VERSION ""

NS_ :

BS_:

BU_: WCM VPM VLM VKM UVM TIM TEST_TOOL_2 TEST_TOOL_1 TCP TCM TCCM3 TCCM STC SRR_SRR SRR_SLR SRR_RR SRR_RF SRR_LR_CR SRR_LF SIB SDM SCL SBZA_R SBZA_L SBM SADS RadioLow RSC RDCM PTM PDR PA NVM MTCM_R MTCM_L MSM_RR MSM_P MSM_LR MSM_D MSB2 MSB1 MRCM_R MRCM_L MFC LRR_HC LRR LIB1 IPC ICS_Info ICCM HVAC_FP_R HVAC_FP_F HUD_CAN HDLM FCM_LC FCM EPS EOCM_HCP2 EOCM_HCP1 EOCM ELM ECP_X1 ECP_MC ECP_E ECM EBCM DMS DEFC DCM CSM CMMb CMMa CGM BSM_MH BSM BCM ARS ARB APA AOS AMP ALC AHS AHL_AFL AGC

BO_ 1425 CGM_CAN5_PDU108: 6 CGM
 SG_ PTOSet2SpdCstAvlFlg4 : 0|1@0+ (1,0) [0|1] "" CSM,RadioLow
 SG_ PTOSet2SpdCstAvlFlg3 : 1|1@0+ (1,0) [0|1] "" CSM,RadioLow
 SG_ PTOSet2SpdCstAvlFlg2 : 2|1@0+ (1,0) [0|1] "" CSM,RadioLow
 SG_ PTOSet2SpdCstAvlFlg15 : 3|1@0+ (1,0) [0|1] "" CSM,RadioLow
 SG_ PTOSet2SpdCstAvlFlg14 : 4|1@0+ (1,0) [0|1] "" CSM,RadioLow
 SG_ PTOSet2SpdCstAvlFlg13 : 5|1@0+ (1,0) [0|1] "" CSM,RadioLow
 SG_ PTOSet2SpdCstAvlFlg12 : 6|1@0+ (1,0) [0|1] "" CSM,RadioLow
 SG_ PTOSet2SpdCstAvlFlg11 : 7|1@0+ (1,0) [0|1] "" CSM,RadioLow
 SG_ PTOStndbySpdCstAvlFlg3 : 8|1@0+ (1,0) [0|1] "" CSM,RadioLow
 SG_ PTOStndbySpdCstAvlFlg2 : 9|1@0+ (1,0) [0|1] "" CSM,RadioLow
 SG_ PTOStndbySpdCstAvlFlg1 : 10|1@0+ (1,0) [0|1] "" CSM,RadioLow
 SG_ PTOSet2SpdCstAvlFlg9 : 11|1@0+ (1,0) [0|1] "" CSM,RadioLow
 SG_ PTOSet2SpdCstAvlFlg8 : 12|1@0+ (1,0) [0|1] "" CSM,RadioLow
 SG_ PTOSet2SpdCstAvlFlg7 : 13|1@0+ (1,0) [0|1] "" CSM,RadioLow
 SG_ PTOSet2SpdCstAvlFlg6 : 14|1@0+ (1,0) [0|1] "" CSM,RadioLow
 SG_ PTOSet2SpdCstAvlFlg5 : 15|1@0+ (1,0) [0|1] "" CSM,RadioLow
 SG_ PTOTpStpSpdCstAvlFlg4 : 16|1@0+ (1,0) [0|1] "" CSM,RadioLow
 SG_ PTOTpStpSpdCstAvlFlg3 : 17|1@0+ (1,0) [0|1] "" CSM,RadioLow
 SG_ PTOTpStpSpdCstAvlFlg2 : 18|1@0+ (1,0) [0|1] "" CSM,RadioLow
 SG_ PTOTpStpSpdCstAvlFlg1 : 19|1@0+ (1,0) [0|1] "" CSM,RadioLow
 SG_ PTOStndbySpdCstAvlFlg7 : 20|1@0+ (1,0) [0|1] "" CSM,RadioLow
 SG_ PTOStndbySpdCstAvlFlg6 : 21|1@0+ (1,0) [0|1] "" CSM,RadioLow
 SG_ PTOStndbySpdCstAvlFlg5 : 22|1@0+ (1,0) [0|1] "" CSM,RadioLow
 SG_ PTOStndbySpdCstAvlFlg4 : 23|1@0+ (1,0) [0|1] "" CSM,RadioLow
 SG_ UpftrSnwPlwIndReq : 25|2@0+ (1,0) [0|3] "" IPC
 SG_ UpftrRrAprchPrtctnIndReq : 28|3@0+ (1,0) [0|4] "" IPC
 SG_ PTOTpStpSpdCstAvlFlg7 : 29|1@0+ (1,0) [0|1] "" CSM,RadioLow
 SG_ PTOTpStpSpdCstAvlFlg6 : 30|1@0+ (1,0) [0|1] "" CSM,RadioLow
 SG_ PTOTpStpSpdCstAvlFlg5 : 31|1@0+ (1,0) [0|1] "" CSM,RadioLow
 SG_ IBS12VEstdBatTemp : 34|8@0+ (1,-40) [-40|215] "Degree C" CSM
 SG_ IBS12VEstdBatTemp_Inv : 35|1@0+ (1,0) [0|1] "" CSM
 SG_ UpftrRadioMutReqd : 36|1@0+ (1,0) [0|1] "" RadioLow
 SG_ UpftrBkupCamActvnReqd : 37|1@0+ (1,0) [0|1] "" RadioLow
 SG_ UpftrVehStrtEnblIndReq : 41|2@0+ (1,0) [0|3] "" IPC
 SG_ TransOilFiltChgIndOn : 42|1@0+ (1,0) [0|1] "" IPC

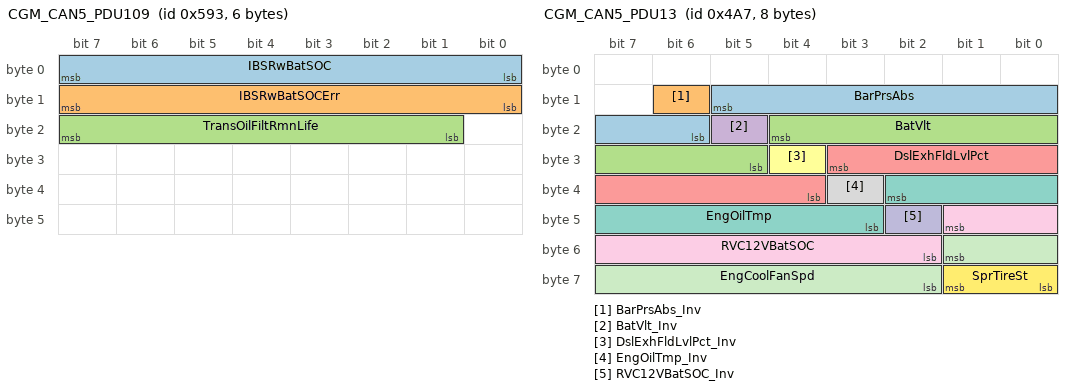
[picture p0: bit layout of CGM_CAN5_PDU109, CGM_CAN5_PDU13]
BO_ 1427 CGM_CAN5_PDU109: 6 CGM
 SG_ IBSRwBatSOC : 7|8@0+ (0.39,0) [0|99.45] "%" CSM
 SG_ IBSRwBatSOCErr : 15|8@0+ (0.39,0) [0|99.45] "%" CSM
 SG_ TransOilFiltRmnLife : 23|7@0+ (1,0) [0|127] "%" IPC

BO_ 1188 CGM_CAN5_PDU10: 8 CGM
 SG_ StBltTghtngCstAvlFlg7 : 0|1@0+ (1,0) [0|1] "" CSM,RadioLow
 SG_ StBltTghtngCstAvlFlg6 : 1|1@0+ (1,0) [0|1] "" CSM,RadioLow
 SG_ StBltTghtngCstAvlFlg5 : 2|1@0+ (1,0) [0|1] "" CSM,RadioLow
 SG_ StBltTghtngCstAvlFlg4 : 3|1@0+ (1,0) [0|1] "" CSM,RadioLow
 SG_ StBltTghtngCstAvlFlg3 : 4|1@0+ (1,0) [0|1] "" CSM,RadioLow
 SG_ StBltTghtngCstAvlFlg2 : 5|1@0+ (1,0) [0|1] "" CSM,RadioLow
 SG_ StBltTghtngCstAvlFlg1 : 6|1@0+ (1,0) [0|1] "" CSM,RadioLow
 SG_ RrCrsTrfcAlrtCstAvlFlg7 : 7|1@0+ (1,0) [0|1] "" CSM,RadioLow
 SG_ TrnsOlTmpSnsPrs : 8|1@0+ (1,0) [0|1] "" CSM,TCP
 SG_ TrffcLgtAsstCstAvlFlg7 : 9|1@0+ (1,0) [0|1] "" CSM,RadioLow
 SG_ TrffcLgtAsstCstAvlFlg6 : 10|1@0+ (1,0) [0|1] "" CSM,RadioLow
 SG_ TrffcLgtAsstCstAvlFlg5 : 11|1@0+ (1,0) [0|1] "" CSM,RadioLow
 SG_ TrffcLgtAsstCstAvlFlg4 : 12|1@0+ (1,0) [0|1] "" CSM,RadioLow
 SG_ TrffcLgtAsstCstAvlFlg3 : 13|1@0+ (1,0) [0|1] "" CSM,RadioLow
 SG_ TrffcLgtAsstCstAvlFlg2 : 14|1@0+ (1,0) [0|1] "" CSM,RadioLow
 SG_ TrffcLgtAsstCstAvlFlg1 : 15|1@0+ (1,0) [0|1] "" CSM,RadioLow
 SG_ DEFWVSL_S1SpdLmt : 23|8@0+ (1,0) [0|255] "km / h" IPC
 SG_ DEFWVSL_S2SpdLmt : 31|8@0+ (1,0) [0|255] "km / h" IPC
 SG_ DEFWVSL_S3SpdLmt : 39|8@0+ (1,0) [0|255] "km / h" IPC
 SG_ CustNonUsblSOC : 46|16@0+ (0.00152588,0) [0|99.9985] "%" IPC
 SG_ CustNonUsblSOC_DuD : 47|1@0+ (1,0) [0|1] "" IPC
 SG_ ClmCtlCbnAirCondCustLdEstd : 62|7@0+ (1,0) [0|127] "%" IPC

BO_ 1189 CGM_CAN5_PDU11: 8 CGM
 SG_ GoNotfrCstAvlFlg7 : 0|1@0+ (1,0) [0|1] "" CSM,RadioLow
 SG_ GoNotfrCstAvlFlg6 : 1|1@0+ (1,0) [0|1] "" CSM,RadioLow
 SG_ GoNotfrCstAvlFlg5 : 2|1@0+ (1,0) [0|1] "" CSM,RadioLow
 SG_ GoNotfrCstAvlFlg4 : 3|1@0+ (1,0) [0|1] "" CSM,RadioLow
 SG_ GoNotfrCstAvlFlg3 : 4|1@0+ (1,0) [0|1] "" CSM,RadioLow
 SG_ GoNotfrCstAvlFlg2 : 5|1@0+ (1,0) [0|1] "" CSM,RadioLow
 SG_ GoNotfrCstAvlFlg1 : 6|1@0+ (1,0) [0|1] "" CSM,RadioLow
 SG_ GlrFrHgBmRspTypCstAvlFlg7 : 7|1@0+ (1,0) [0|1] "" CSM,RadioLow
 SG_ LtRtHnTrCstAvlFlg1 : 8|1@0+ (1,0) [0|1] "" CSM,RadioLow
 SG_ LnChgAlrtCstAvlFlg7 : 9|1@0+ (1,0) [0|1] "" CSM,RadioLow,TCP
 SG_ LnChgAlrtCstAvlFlg6 : 10|1@0+ (1,0) [0|1] "" CSM,RadioLow,TCP
 SG_ LnChgAlrtCstAvlFlg5 : 11|1@0+ (1,0) [0|1] "" CSM,RadioLow,TCP
 SG_ LnChgAlrtCstAvlFlg4 : 12|1@0+ (1,0) [0|1] "" CSM,RadioLow,TCP
 SG_ LnChgAlrtCstAvlFlg3 : 13|1@0+ (1,0) [0|1] "" CSM,RadioLow,TCP
 SG_ LnChgAlrtCstAvlFlg2 : 14|1@0+ (1,0) [0|1] "" CSM,RadioLow,TCP
 SG_ LnChgAlrtCstAvlFlg1 : 15|1@0+ (1,0) [0|1] "" CSM,RadioLow,TCP
 SG_ PrkAsstONOFFCstAvlFlg1 : 16|1@0+ (1,0) [0|1] "" CSM,RadioLow
 SG_ PTHiElecLdReqd : 17|1@0+ (1,0) [0|1] "" CSM
 SG_ LtRtHnTrCstAvlFlg7 : 18|1@0+ (1,0) [0|1] "" CSM,RadioLow
 SG_ LtRtHnTrCstAvlFlg6 : 19|1@0+ (1,0) [0|1] "" CSM,RadioLow
 SG_ LtRtHnTrCstAvlFlg5 : 20|1@0+ (1,0) [0|1] "" CSM,RadioLow
 SG_ LtRtHnTrCstAvlFlg4 : 21|1@0+ (1,0) [0|1] "" CSM,RadioLow
 SG_ LtRtHnTrCstAvlFlg3 : 22|1@0+ (1,0) [0|1] "" CSM,RadioLow
 SG_ LtRtHnTrCstAvlFlg2 : 23|1@0+ (1,0) [0|1] "" CSM,RadioLow
 SG_ PrkAsstTrHtchPsntCstAvlFlg2 : 24|1@0+ (1,0) [0|1] "" CSM,RadioLow
 SG_ PrkAsstTrHtchPsntCstAvlFlg1 : 25|1@0+ (1,0) [0|1] "" CSM,RadioLow
 SG_ PrkAsstONOFFCstAvlFlg7 : 26|1@0+ (1,0) [0|1] "" CSM,RadioLow
 SG_ PrkAsstONOFFCstAvlFlg6 : 27|1@0+ (1,0) [0|1] "" CSM,RadioLow
 SG_ PrkAsstONOFFCstAvlFlg5 : 28|1@0+ (1,0) [0|1] "" CSM,RadioLow
 SG_ PrkAsstONOFFCstAvlFlg4 : 29|1@0+ (1,0) [0|1] "" CSM,RadioLow
 SG_ PrkAsstONOFFCstAvlFlg3 : 30|1@0+ (1,0) [0|1] "" CSM,RadioLow
 SG_ PrkAsstONOFFCstAvlFlg2 : 31|1@0+ (1,0) [0|1] "" CSM,RadioLow
 SG_ PFASndSeltnCstAvlFlg2 : 32|1@0+ (1,0) [0|1] "" CSM
 SG_ PFASndSeltnCstAvlFlg1 : 33|1@0+ (1,0) [0|1] "" CSM
 SG_ LgslDiagStdCndMet : 34|1@0+ (1,0) [0|1] "" TCP
 SG_ PrkAsstTrHtchPsntCstAvlFlg7 : 35|1@0+ (1,0) [0|1] "" CSM,RadioLow
 SG_ PrkAsstTrHtchPsntCstAvlFlg6 : 36|1@0+ (1,0) [0|1] "" CSM,RadioLow
 SG_ PrkAsstTrHtchPsntCstAvlFlg5 : 37|1@0+ (1,0) [0|1] "" CSM,RadioLow
 SG_ PrkAsstTrHtchPsntCstAvlFlg4 : 38|1@0+ (1,0) [0|1] "" CSM,RadioLow
 SG_ PrkAsstTrHtchPsntCstAvlFlg3 : 39|1@0+ (1,0) [0|1] "" CSM,RadioLow
 SG_ RnngBrdAutoDplyCstAvlFlg4 : 40|1@0+ (1,0) [0|1] "" CSM,RadioLow
 SG_ RnngBrdAutoDplyCstAvlFlg3 : 41|1@0+ (1,0) [0|1] "" CSM,RadioLow
 SG_ RnngBrdAutoDplyCstAvlFlg2 : 42|1@0+ (1,0) [0|1] "" CSM,RadioLow
 SG_ RnngBrdAutoDplyCstAvlFlg1 : 43|1@0+ (1,0) [0|1] "" CSM,RadioLow
 SG_ PFASndSeltnCstAvlFlg6 : 44|1@0+ (1,0) [0|1] "" CSM
 SG_ PFASndSeltnCstAvlFlg5 : 45|1@0+ (1,0) [0|1] "" CSM
 SG_ PFASndSeltnCstAvlFlg4 : 46|1@0+ (1,0) [0|1] "" CSM
 SG_ PFASndSeltnCstAvlFlg3 : 47|1@0+ (1,0) [0|1] "" CSM
 SG_ RnngBrdManDplyCstAvlFlg5 : 48|1@0+ (1,0) [0|1] "" CSM,RadioLow
 SG_ RnngBrdManDplyCstAvlFlg4 : 49|1@0+ (1,0) [0|1] "" CSM,RadioLow
 SG_ RnngBrdManDplyCstAvlFlg3 : 50|1@0+ (1,0) [0|1] "" CSM,RadioLow
 SG_ RnngBrdManDplyCstAvlFlg2 : 51|1@0+ (1,0) [0|1] "" CSM,RadioLow
 SG_ RnngBrdManDplyCstAvlFlg1 : 52|1@0+ (1,0) [0|1] "" CSM,RadioLow
 SG_ RnngBrdAutoDplyCstAvlFlg7 : 53|1@0+ (1,0) [0|1] "" CSM,RadioLow
 SG_ RnngBrdAutoDplyCstAvlFlg6 : 54|1@0+ (1,0) [0|1] "" CSM,RadioLow
 SG_ RnngBrdAutoDplyCstAvlFlg5 : 55|1@0+ (1,0) [0|1] "" CSM,RadioLow
 SG_ RrCrsTrfcAlrtCstAvlFlg6 : 56|1@0+ (1,0) [0|1] "" CSM,RadioLow
 SG_ RrCrsTrfcAlrtCstAvlFlg5 : 57|1@0+ (1,0) [0|1] "" CSM,RadioLow
 SG_ RrCrsTrfcAlrtCstAvlFlg4 : 58|1@0+ (1,0) [0|1] "" CSM,RadioLow
 SG_ RrCrsTrfcAlrtCstAvlFlg3 : 59|1@0+ (1,0) [0|1] "" CSM,RadioLow
 SG_ RrCrsTrfcAlrtCstAvlFlg2 : 60|1@0+ (1,0) [0|1] "" CSM,RadioLow
 SG_ RrCrsTrfcAlrtCstAvlFlg1 : 61|1@0+ (1,0) [0|1] "" CSM,RadioLow
 SG_ RnngBrdManDplyCstAvlFlg7 : 62|1@0+ (1,0) [0|1] "" CSM,RadioLow
 SG_ RnngBrdManDplyCstAvlFlg6 : 63|1@0+ (1,0) [0|1] "" CSM,RadioLow

BO_ 1190 CGM_CAN5_PDU12: 8 CGM
 SG_ TrnsOilRmnLf : 15|8@0+ (0.392157,0) [0|100] "%" CSM,IPC,TCP,VKM
 SG_ AutMemRclCstAvlFlg4 : 24|1@0+ (1,0) [0|1] "" CSM,RadioLow
 SG_ AutMemRclCstAvlFlg3 : 25|1@0+ (1,0) [0|1] "" CSM,RadioLow
 SG_ AutMemRclCstAvlFlg2 : 26|1@0+ (1,0) [0|1] "" CSM,RadioLow
 SG_ AutMemRclCstAvlFlg1 : 27|1@0+ (1,0) [0|1] "" CSM,RadioLow
 SG_ AdpLghtRspTypCstAvlFlg7 : 28|1@0+ (1,0) [0|1] "" CSM,RadioLow
 SG_ AdpLghtRspTypCstAvlFlg6 : 29|1@0+ (1,0) [0|1] "" CSM,RadioLow
 SG_ AdpLghtRspTypCstAvlFlg5 : 30|1@0+ (1,0) [0|1] "" CSM,RadioLow
 SG_ AdpLghtRspTypCstAvlFlg4 : 31|1@0+ (1,0) [0|1] "" CSM,RadioLow
 SG_ EsyExtCstAvlFlg4 : 32|1@0+ (1,0) [0|1] "" CSM,RadioLow
 SG_ EsyExtCstAvlFlg3 : 33|1@0+ (1,0) [0|1] "" CSM,RadioLow
 SG_ EsyExtCstAvlFlg2 : 34|1@0+ (1,0) [0|1] "" CSM,RadioLow
 SG_ EsyExtCstAvlFlg1 : 35|1@0+ (1,0) [0|1] "" CSM,RadioLow
 SG_ EngIdlAtv : 36|1@0+ (1,0) [0|1] "" CSM,IPC
 SG_ AutMemRclCstAvlFlg7 : 37|1@0+ (1,0) [0|1] "" CSM,RadioLow
 SG_ AutMemRclCstAvlFlg6 : 38|1@0+ (1,0) [0|1] "" CSM,RadioLow
 SG_ AutMemRclCstAvlFlg5 : 39|1@0+ (1,0) [0|1] "" CSM,RadioLow
 SG_ FrntPCMRspTypCstAvlFlg4 : 40|1@0+ (1,0) [0|1] "" CSM,RadioLow
 SG_ FrntPCMRspTypCstAvlFlg3 : 41|1@0+ (1,0) [0|1] "" CSM,RadioLow
 SG_ FrntPCMRspTypCstAvlFlg2 : 42|1@0+ (1,0) [0|1] "" CSM,RadioLow
 SG_ FrntPCMRspTypCstAvlFlg1 : 43|1@0+ (1,0) [0|1] "" CSM,RadioLow
 SG_ FlToPsSwAtv : 44|1@0+ (1,0) [0|1] "" CSM
 SG_ EsyExtCstAvlFlg7 : 45|1@0+ (1,0) [0|1] "" CSM,RadioLow
 SG_ EsyExtCstAvlFlg6 : 46|1@0+ (1,0) [0|1] "" CSM,RadioLow
 SG_ EsyExtCstAvlFlg5 : 47|1@0+ (1,0) [0|1] "" CSM,RadioLow
 SG_ FrwdImpMtgnOpSlctCstAvlFlg5 : 48|1@0+ (1,0) [0|1] "" CSM,RadioLow,TCP
 SG_ FrwdImpMtgnOpSlctCstAvlFlg4 : 49|1@0+ (1,0) [0|1] "" CSM,RadioLow,TCP
 SG_ FrwdImpMtgnOpSlctCstAvlFlg3 : 50|1@0+ (1,0) [0|1] "" CSM,RadioLow,TCP
 SG_ FrwdImpMtgnOpSlctCstAvlFlg2 : 51|1@0+ (1,0) [0|1] "" CSM,RadioLow,TCP
 SG_ FrwdImpMtgnOpSlctCstAvlFlg1 : 52|1@0+ (1,0) [0|1] "" CSM,RadioLow,TCP
 SG_ FrntPCMRspTypCstAvlFlg7 : 53|1@0+ (1,0) [0|1] "" CSM,RadioLow
 SG_ FrntPCMRspTypCstAvlFlg6 : 54|1@0+ (1,0) [0|1] "" CSM,RadioLow
 SG_ FrntPCMRspTypCstAvlFlg5 : 55|1@0+ (1,0) [0|1] "" CSM,RadioLow
 SG_ GlrFrHgBmRspTypCstAvlFlg6 : 56|1@0+ (1,0) [0|1] "" CSM,RadioLow
 SG_ GlrFrHgBmRspTypCstAvlFlg5 : 57|1@0+ (1,0) [0|1] "" CSM,RadioLow
 SG_ GlrFrHgBmRspTypCstAvlFlg4 : 58|1@0+ (1,0) [0|1] "" CSM,RadioLow
 SG_ GlrFrHgBmRspTypCstAvlFlg3 : 59|1@0+ (1,0) [0|1] "" CSM,RadioLow
 SG_ GlrFrHgBmRspTypCstAvlFlg2 : 60|1@0+ (1,0) [0|1] "" CSM,RadioLow
 SG_ GlrFrHgBmRspTypCstAvlFlg1 : 61|1@0+ (1,0) [0|1] "" CSM,RadioLow
 SG_ FrwdImpMtgnOpSlctCstAvlFlg7 : 62|1@0+ (1,0) [0|1] "" CSM,RadioLow,TCP
 SG_ FrwdImpMtgnOpSlctCstAvlFlg6 : 63|1@0+ (1,0) [0|1] "" CSM,RadioLow,TCP

BO_ 1191 CGM_CAN5_PDU13: 8 CGM
 SG_ BarPrsAbs : 13|8@0+ (0.5,0) [0|127.5] "kPa" CSM
 SG_ BarPrsAbs_Inv : 14|1@0+ (1,0) [0|1] "" CSM
 SG_ BatVlt : 20|8@0+ (0.1,3) [3|28.5] "volts" CSM,PDR,TCP,VKM
 SG_ BatVlt_Inv : 21|1@0+ (1,0) [0|1] "" CSM,PDR,TCP
 SG_ DslExhFldLvlPct : 27|8@0+ (0.392157,0) [0|100] "%" CSM,IPC
 SG_ DslExhFldLvlPct_Inv : 28|1@0+ (1,0) [0|1] "" CSM,IPC
 SG_ EngOilTmp : 34|8@0+ (1,-40) [-40|215] "deg C" CSM,IPC,PDR,TCP
 SG_ EngOilTmp_Inv : 35|1@0+ (1,0) [0|1] "" CSM,IPC,PDR
 SG_ RVC12VBatSOC : 41|8@0+ (0.5,0) [0|127.5] "%" CSM,TCP,VKM
 SG_ RVC12VBatSOC_Inv : 42|1@0+ (1,0) [0|1] "" CSM,TCP
 SG_ EngCoolFanSpd : 49|8@0+ (0.392157,0) [0|100] "%" CSM
 SG_ SprTireSt : 57|2@0+ (1,0) [0|2] "" CSM

BO_ 1192 CGM_CAN5_PDU14: 8 CGM
 SG_ OATP_OtsAirTmpAuth : 7|8@0+ (0.5,-40) [-40|87.5] "Deg C" CSM,RadioLow
 SG_ OATP_OtsAirTmpCrValAuth : 15|8@0+ (0.5,-40) [-40|87.5] "Deg C" CSM,IPC,PDR,RadioLow
 SG_ HiVltgBatMaxTemp : 21|8@0+ (0.5,-40) [-40|87.5] "Deg C" PDR
 SG_ HiVltgBatMaxTemp_Inv : 22|1@0+ (1,0) [0|1] "" PDR
 SG_ OATP_OtsAirTmpCrValAuth_Inv : 23|1@0+ (1,0) [0|1] "" CSM,IPC,PDR,RadioLow
 SG_ PwrRrClsrCstAvlFlg4 : 24|1@0+ (1,0) [0|1] "" CSM,RadioLow
 SG_ PwrRrClsrCstAvlFlg3 : 25|1@0+ (1,0) [0|1] "" CSM,RadioLow
 SG_ PwrRrClsrCstAvlFlg2 : 26|1@0+ (1,0) [0|1] "" CSM,RadioLow
 SG_ PwrRrClsrCstAvlFlg1 : 27|1@0+ (1,0) [0|1] "" CSM,RadioLow
 SG_ PFASndSeltnCstSetAval : 28|1@0+ (1,0) [0|1] "" CSM
 SG_ PFASndSeltnCstAvlFlg7 : 29|1@0+ (1,0) [0|1] "" CSM
 SG_ WEPRP_WhlEdgesPerRevRrAuth : 38|7@0+ (1,30) [30|157] "edges" CSM,TCP
 SG_ PwrRrClsrCstAvlFlg5 : 39|1@0+ (1,0) [0|1] "" CSM,RadioLow
 SG_ ACRfHiSdFldPrs_Inv : 40|1@0+ (1,0) [0|1] "" CSM,TCP
 SG_ WEPRP_WhlEdgesPerRevFrtAuth : 47|7@0+ (1,30) [30|157] "edges" CSM,TCP
 SG_ ACRfHiSdFldPrs : 55|8@0+ (14,0) [0|3570] "kPaG" CSM,TCP
 SG_ ACCmpNrmLdGrdAld : 63|8@0+ (0.1,0) [0|25.5] "dm3/m/s" CSM

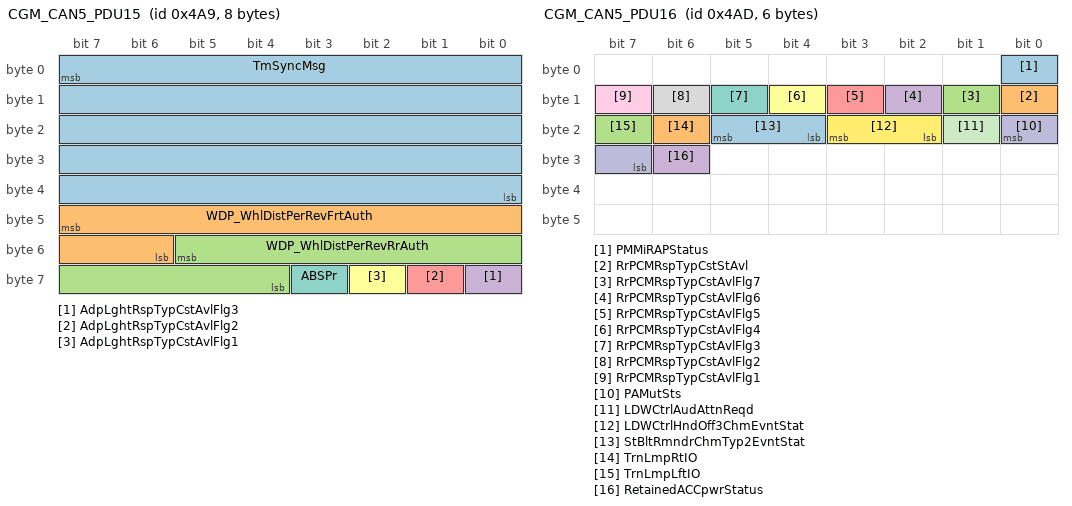
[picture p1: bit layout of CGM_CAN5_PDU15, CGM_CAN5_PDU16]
BO_ 1193 CGM_CAN5_PDU15: 8 CGM
 SG_ TmSyncMsg : 7|40@0+ (100,0) [0|1.09951e+014] "ms" AGC,AMP,CSM,HUD_CAN,HVAC_FP_F,HVAC_FP_R,ICS_Info,IPC,PDR,MFC,RSC,RadioLow,TCP,VKM,WCM
 SG_ WDP_WhlDistPerRevFrtAuth : 47|10@0+ (3,800) [800|3869] "mm" CSM,PDR,TCP
 SG_ WDP_WhlDistPerRevRrAuth : 53|10@0+ (3,800) [800|3869] "mm" CSM,PDR,TCP
 SG_ AdpLghtRspTypCstAvlFlg3 : 56|1@0+ (1,0) [0|1] "" CSM,RadioLow
 SG_ AdpLghtRspTypCstAvlFlg2 : 57|1@0+ (1,0) [0|1] "" CSM,RadioLow
 SG_ AdpLghtRspTypCstAvlFlg1 : 58|1@0+ (1,0) [0|1] "" CSM,RadioLow
 SG_ ABSPr : 59|1@0+ (1,0) [0|1] "" TCP

BO_ 1197 CGM_CAN5_PDU16: 6 CGM
 SG_ PMMiRAPStatus : 0|1@0+ (1,0) [0|1] "" WCM
 SG_ RrPCMRspTypCstStAvl : 8|1@0+ (1,0) [0|1] "" CSM,RadioLow
 SG_ RrPCMRspTypCstAvlFlg7 : 9|1@0+ (1,0) [0|1] "" CSM,RadioLow
 SG_ RrPCMRspTypCstAvlFlg6 : 10|1@0+ (1,0) [0|1] "" CSM,RadioLow
 SG_ RrPCMRspTypCstAvlFlg5 : 11|1@0+ (1,0) [0|1] "" CSM,RadioLow
 SG_ RrPCMRspTypCstAvlFlg4 : 12|1@0+ (1,0) [0|1] "" CSM,RadioLow
 SG_ RrPCMRspTypCstAvlFlg3 : 13|1@0+ (1,0) [0|1] "" CSM,RadioLow
 SG_ RrPCMRspTypCstAvlFlg2 : 14|1@0+ (1,0) [0|1] "" CSM,RadioLow
 SG_ RrPCMRspTypCstAvlFlg1 : 15|1@0+ (1,0) [0|1] "" CSM,RadioLow
 SG_ PAMutSts : 16|2@0+ (1,0) [0|2] "" IPC
 SG_ LDWCtrlAudAttnReqd : 17|1@0+ (1,0) [0|1] "" CSM,RadioLow
 SG_ LDWCtrlHndOff3ChmEvntStat : 19|2@0+ (1,0) [0|2] "" CSM,IPC
 SG_ StBltRmndrChmTyp2EvntStat : 21|2@0+ (1,0) [0|2] "" CSM,IPC
 SG_ TrnLmpRtIO : 22|1@0+ (1,0) [0|1] "" CSM,IPC,TCP
 SG_ TrnLmpLftIO : 23|1@0+ (1,0) [0|1] "" CSM,IPC,TCP
 SG_ RetainedACCpwrStatus : 30|1@0+ (1,0) [0|1] "" TCP

BO_ 1198 CGM_CAN5_PDU17: 8 CGM
 SG_ PrkAsstRrLftSdZn1ChEvntSt : 1|2@0+ (1,0) [0|2] "" IPC
 SG_ PrkAsstRrFrstRprtChEvntSt : 3|2@0+ (1,0) [0|2] "" IPC
 SG_ PrkAsstFrRgrChEvntSt : 5|2@0+ (1,0) [0|2] "" IPC
 SG_ PrkAsstFrRghtSdZn6ChEvntSt : 7|2@0+ (1,0) [0|2] "" IPC
 SG_ PrkAsstRrLftSdZn5ChEvntSt : 9|2@0+ (1,0) [0|2] "" IPC
 SG_ PrkAsstRrLftSdZn4ChEvntSt : 11|2@0+ (1,0) [0|2] "" IPC
 SG_ PrkAsstRrLftSdZn3ChEvntSt : 13|2@0+ (1,0) [0|2] "" IPC
 SG_ PrkAsstRrLftSdZn2ChEvntSt : 15|2@0+ (1,0) [0|2] "" IPC
 SG_ PrkAsstRrRghtSdZn3ChEvntSt : 17|2@0+ (1,0) [0|2] "" IPC
 SG_ PrkAsstRrRghtSdZn2ChEvntSt : 19|2@0+ (1,0) [0|2] "" IPC
 SG_ PrkAsstRrRghtSdZn1ChEvntSt : 21|2@0+ (1,0) [0|2] "" IPC
 SG_ PrkAsstRrLftSdZn6ChEvntSt : 23|2@0+ (1,0) [0|2] "" IPC
 SG_ PrkAsstRrRgrChEvntSt : 25|2@0+ (1,0) [0|2] "" IPC
 SG_ PrkAsstRrRghtSdZn6ChEvntSt : 27|2@0+ (1,0) [0|2] "" IPC
 SG_ PrkAsstRrRghtSdZn5ChEvntSt : 29|2@0+ (1,0) [0|2] "" IPC
 SG_ PrkAsstRrRghtSdZn4ChEvntSt : 31|2@0+ (1,0) [0|2] "" IPC
 SG_ RrCrsTrfcAlrtLftIndCtrl : 33|2@0+ (1,0) [0|2] "" CSM,RadioLow
 SG_ RlOvrDsblStsChgChmEvntStat : 35|2@0+ (1,0) [0|2] "" IPC
 SG_ RIMIntCllnChmEvStat : 37|2@0+ (1,0) [0|2] "" CSM,IPC
 SG_ RIMBrkPlsChEvStat : 39|2@0+ (1,0) [0|2] "" IPC
 SG_ RrPCMChmEvntSt : 41|2@0+ (1,0) [0|2] "" CSM,IPC
 SG_ RrCrsTrfcAlrtRtSdChmEvntStat : 43|2@0+ (1,0) [0|2] "" CSM,IPC
 SG_ RrCrsTrfcAlrtRgIndCtrl : 45|2@0+ (1,0) [0|2] "" CSM,RadioLow
 SG_ RrCrsTrfcAlrtLtSdChmEvntStat : 47|2@0+ (1,0) [0|2] "" CSM,IPC
 SG_ DrHndlLRAuthReqd : 48|1@0+ (1,0) [0|1] "" VKM
 SG_ DrHndlLFAuthReqd : 49|1@0+ (1,0) [0|1] "" VKM
 SG_ FrtPedtrnClsnMtgnAudAttnReqd : 50|1@0+ (1,0) [0|1] "" CSM,RadioLow
 SG_ ACCGoNtfrChmEvntSt : 51|1@0+ (1,0) [0|1] "" IPC
 SG_ TrffcLgtAsstWrnChmEvntStat : 53|2@0+ (1,0) [0|3] "" IPC
 SG_ StBltRmndrChmEvntStat : 55|2@0+ (1,0) [0|2] "" CSM,IPC
 SG_ HVACUsrCtlIntrctnDispReqd : 56|1@0+ (1,0) [0|1] "" CSM,RadioLow
 SG_ AirDflctrIndReq : 58|2@0+ (1,0) [0|2] "" IPC
 SG_ RrClsrRelAuthReqd : 59|1@0+ (1,0) [0|1] "" VKM
 SG_ LnKpAsstTkStrIndOn : 60|1@0+ (1,0) [0|1] "" CSM,TCP
 SG_ FrtClsrRelAuthReqd : 61|1@0+ (1,0) [0|1] "" VKM
 SG_ DrHndlRRAuthReqd : 62|1@0+ (1,0) [0|1] "" VKM
 SG_ DrHndlRFAuthReqd : 63|1@0+ (1,0) [0|1] "" VKM

BO_ 1199 CGM_CAN5_PDU18: 8 CGM
 SG_ MemStrTrplBeepChmEvStCoDrv : 1|2@0+ (1,0) [0|2] "" IPC
 SG_ MemStrSnglBeepChmEvStRR : 3|2@0+ (1,0) [0|2] "" IPC
 SG_ MemStrSnglBeepChmEvStLR : 5|2@0+ (1,0) [0|2] "" IPC
 SG_ MemStrSnglBeepChmEvStDrv : 7|2@0+ (1,0) [0|2] "" IPC
 SG_ PrkAsstFlChEvntSt : 9|2@0+ (1,0) [0|2] "" CSM,IPC
 SG_ MemStrTrplBeepChmEvStRR : 11|2@0+ (1,0) [0|2] "" IPC
 SG_ MemStrTrplBeepChmEvStLR : 13|2@0+ (1,0) [0|2] "" IPC
 SG_ MemStrTrplBeepChmEvStDrv : 15|2@0+ (1,0) [0|2] "" IPC
 SG_ PrkAsstFllFrZn4ChEvntSt : 17|2@0+ (1,0) [0|2] "" CSM,IPC
 SG_ PrkAsstFllFrZn3ChEvntSt : 19|2@0+ (1,0) [0|2] "" CSM,IPC
 SG_ PrkAsstFllFrZn2ChEvntSt : 21|2@0+ (1,0) [0|2] "" CSM,IPC
 SG_ PrkAsstFllFrZn1ChEvntSt : 23|2@0+ (1,0) [0|2] "" CSM,IPC
 SG_ PrkAsstFllRrZn2ChEvntSt : 25|2@0+ (1,0) [0|2] "" CSM,IPC
 SG_ PrkAsstFllRrZn1ChEvntSt : 27|2@0+ (1,0) [0|2] "" CSM,IPC
 SG_ PrkAsstFllFrZn6ChEvntSt : 29|2@0+ (1,0) [0|2] "" CSM,IPC
 SG_ PrkAsstFllFrZn5ChEvntSt : 31|2@0+ (1,0) [0|2] "" CSM,IPC
 SG_ PrkAsstFllRrZn6ChEvntSt : 33|2@0+ (1,0) [0|2] "" CSM,IPC
 SG_ PrkAsstFllRrZn5ChEvntSt : 35|2@0+ (1,0) [0|2] "" CSM,IPC
 SG_ PrkAsstFllRrZn4ChEvntSt : 37|2@0+ (1,0) [0|2] "" CSM,IPC
 SG_ PrkAsstFllRrZn3ChEvntSt : 39|2@0+ (1,0) [0|2] "" CSM,IPC
 SG_ PrkAsstFrLftSdZn3ChEvntSt : 41|2@0+ (1,0) [0|2] "" CSM,IPC
 SG_ PrkAsstFrLftSdZn2ChEvntSt : 43|2@0+ (1,0) [0|2] "" CSM,IPC
 SG_ PrkAsstFrLftSdZn1ChEvntSt : 45|2@0+ (1,0) [0|2] "" CSM,IPC
 SG_ PrkAsstFrFrstRprtChEvntSt : 47|2@0+ (1,0) [0|2] "" CSM,IPC
 SG_ PrkAsstFrRghtSdZn1ChEvntSt : 49|2@0+ (1,0) [0|2] "" CSM,IPC
 SG_ PrkAsstFrLftSdZn6ChEvntSt : 51|2@0+ (1,0) [0|2] "" CSM,IPC
 SG_ PrkAsstFrLftSdZn5ChEvntSt : 53|2@0+ (1,0) [0|2] "" CSM,IPC
 SG_ PrkAsstFrLftSdZn4ChEvntSt : 55|2@0+ (1,0) [0|2] "" CSM,IPC
 SG_ PrkAsstFrRghtSdZn5ChEvntSt : 57|2@0+ (1,0) [0|2] "" CSM,IPC
 SG_ PrkAsstFrRghtSdZn4ChEvntSt : 59|2@0+ (1,0) [0|2] "" CSM,IPC
 SG_ PrkAsstFrRghtSdZn3ChEvntSt : 61|2@0+ (1,0) [0|2] "" CSM,IPC
 SG_ PrkAsstFrRghtSdZn2ChEvntSt : 63|2@0+ (1,0) [0|2] "" CSM,IPC

BO_ 1200 CGM_CAN5_PDU19: 8 CGM
 SG_ TrlrConnCntr : 3|4@0+ (1,0) [0|15] "Count" CSM
 SG_ FrwdClsnAlrtImntAlrtAudAttnReqd : 4|1@0+ (1,0) [0|1] "" CSM,RadioLow
 SG_ LKALnMrkgIndLt : 7|3@0+ (1,0) [0|4] "" CSM,IPC
 SG_ LKALnMrkgIndRt : 9|3@0+ (1,0) [0|4] "" CSM,IPC
 SG_ FrntPsSeatbeltStat : 11|2@0+ (1,0) [0|2] "" CSM,RadioLow,TCP
 SG_ FrntPsSeatbeltStat_Inv : 12|1@0+ (1,0) [0|1] "" CSM,RadioLow,TCP
 SG_ EPBSP_ElecPrkBrkApplStsAuth : 15|3@0+ (1,0) [0|4] "" CSM,VKM
 SG_ RrPCMRspTypCstCrStVal : 16|3@0+ (1,0) [0|6] "" CSM,RadioLow
 SG_ ORIP_DrvrStBltStsAuth_Inv : 17|1@0+ (1,0) [0|1] "" CSM,RadioLow,TCP
 SG_ ORIP_DrvrStBltStsAuth : 19|2@0+ (1,0) [0|2] "" CSM,RadioLow,TCP
 SG_ LnDtWrnCntrlVsAlrtCmdGnc : 22|3@0+ (1,0) [0|4] "" CSM,HUD_CAN,IPC,RadioLow
 SG_ ElecPrkBrkCtnChiEveStat : 33|2@0+ (1,0) [0|2] "" CSM,IPC
 SG_ LDWCtrlHndOff1ChmEvntStat : 41|2@0+ (1,0) [0|2] "" CSM,IPC,TCP
 SG_ FrwdCllsnAlrtImAlrtDrIntAlrtChmE : 43|2@0+ (1,0) [0|2] "" CSM,IPC,TCP
 SG_ FrntPCMChmEvntStat : 45|2@0+ (1,0) [0|2] "" CSM,IPC
 SG_ ElecPrkBrkFixDurChiEveStat : 47|2@0+ (1,0) [0|2] "" CSM,IPC
 SG_ MemStrDblBeepChmEvStCoDrv : 49|2@0+ (1,0) [0|2] "" IPC
 SG_ LDWCtrlRtHndSdChmEvntStat : 51|2@0+ (1,0) [0|2] "" CSM,IPC,TCP
 SG_ LDWCtrlLtHndSdChmEvntStat : 53|2@0+ (1,0) [0|2] "" CSM,IPC,TCP
 SG_ LDWCtrlHndOff2ChmEvntStat : 55|2@0+ (1,0) [0|2] "" CSM,IPC,TCP
 SG_ MemStrSnglBeepChmEvStCoDrv : 57|2@0+ (1,0) [0|2] "" IPC
 SG_ MemStrDblBeepChmEvStRR : 59|2@0+ (1,0) [0|2] "" IPC
 SG_ MemStrDblBeepChmEvStLR : 61|2@0+ (1,0) [0|2] "" IPC
 SG_ MemStrDblBeepChmEvStDrv : 63|2@0+ (1,0) [0|2] "" IPC

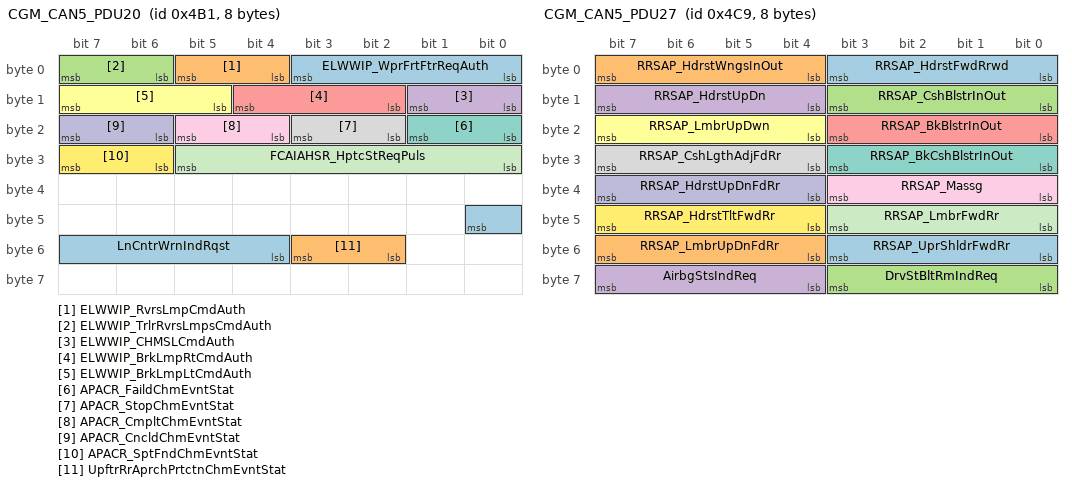
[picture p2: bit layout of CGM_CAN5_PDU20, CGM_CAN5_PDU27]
BO_ 1201 CGM_CAN5_PDU20: 8 CGM
 SG_ ELWWIP_WprFrtFtrReqAuth : 3|4@0+ (1,0) [0|12] "" CSM
 SG_ ELWWIP_RvrsLmpCmdAuth : 5|2@0+ (1,0) [0|2] "" CSM
 SG_ ELWWIP_TrlrRvrsLmpsCmdAuth : 7|2@0+ (1,0) [0|2] "" CSM
 SG_ ELWWIP_CHMSLCmdAuth : 9|2@0+ (1,0) [0|3] "" CSM
 SG_ ELWWIP_BrkLmpRtCmdAuth : 12|3@0+ (1,0) [0|4] "" CSM
 SG_ ELWWIP_BrkLmpLtCmdAuth : 15|3@0+ (1,0) [0|4] "" CSM
 SG_ APACR_FaildChmEvntStat : 17|2@0+ (1,0) [0|2] "" CSM,IPC
 SG_ APACR_StopChmEvntStat : 19|2@0+ (1,0) [0|2] "" CSM,IPC
 SG_ APACR_CmpltChmEvntStat : 21|2@0+ (1,0) [0|2] "" CSM,IPC
 SG_ APACR_CncldChmEvntStat : 23|2@0+ (1,0) [0|2] "" CSM,IPC
 SG_ FCAIAHSR_HptcStReqPuls : 29|6@0+ (1,0) [0|63] "pulses" CSM,TCP
 SG_ APACR_SptFndChmEvntStat : 31|2@0+ (1,0) [0|2] "" CSM,IPC
 SG_ LnCntrWrnIndRqst : 40|5@0+ (1,0) [0|16] "" CSM,TCP
 SG_ UpftrRrAprchPrtctnChmEvntStat : 51|2@0+ (1,0) [0|2] "" IPC

BO_ 1219 CGM_CAN5_PDU21: 8 CGM
 SG_ TrlLfTrInLtFld : 0|1@0+ (1,0) [0|1] "" CSM,IPC,RadioLow
 SG_ TnDrvRIMOFFUnvIndOn : 1|1@0+ (1,0) [0|1] "" IPC,TCP
 SG_ StNtLtchdIO : 2|1@0+ (1,0) [0|1] "" IPC
 SG_ SrvPedtrnProtSysIO : 3|1@0+ (1,0) [0|1] "" CSM,IPC,TCP
 SG_ SftTpVltLwIO : 4|1@0+ (1,0) [0|1] "" IPC
 SG_ SftTpVehOvSpdIO : 5|1@0+ (1,0) [0|1] "" CSM,IPC
 SG_ SftTpTmpLwIO : 6|1@0+ (1,0) [0|1] "" CSM,IPC
 SG_ SftTpStrIO : 7|1@0+ (1,0) [0|1] "" CSM,IPC
 SG_ TrlrTlLtFld : 8|1@0+ (1,0) [0|1] "" CSM,IPC,RadioLow
 SG_ RrVirtBmpAutoBrkRelIndOn : 9|1@0+ (1,0) [0|1] "" IPC
 SG_ TrlrRvrsLmpOtgIndOn : 10|1@0+ (1,0) [0|1] "" CSM,IPC,RadioLow
 SG_ TrlrRtTrInLtFld : 11|1@0+ (1,0) [0|1] "" CSM,IPC,RadioLow
 SG_ TrlrFgLtFld : 13|1@0+ (1,0) [0|1] "" CSM,IPC,RadioLow
 SG_ TrlrDisconndIndOn : 14|1@0+ (1,0) [0|1] "" CSM
 SG_ TrlrBrkLtFld : 15|1@0+ (1,0) [0|1] "" CSM,IPC,RadioLow
 SG_ TrnsNEmsRltMlfActv : 16|1@0+ (1,0) [0|1] "" CSM,IPC,TCP
 SG_ TrnsEmsRltMlfAtv : 17|1@0+ (1,0) [0|1] "" CSM
 SG_ DM2Denied : 18|1@0+ (1,0) [0|1] "" IPC
 SG_ TrnLmpRrRtOtgIndOn : 19|1@0+ (1,0) [0|1] "" CSM,IPC,TCP
 SG_ TrnLmpRrLtOtgIndOn : 20|1@0+ (1,0) [0|1] "" CSM,IPC,TCP
 SG_ DM1Denied : 21|1@0+ (1,0) [0|1] "" IPC
 SG_ TrnLmpFrtRtOtgIndOn : 22|1@0+ (1,0) [0|1] "" CSM,IPC,RadioLow,TCP
 SG_ TrnLmpFrtLtOtgIndOn : 23|1@0+ (1,0) [0|1] "" CSM,IPC,RadioLow,TCP
 SG_ RdHgtStatIndReq : 24|4@0+ (1,0) [0|10] "" IPC
 SG_ SftTpFlrIO : 25|1@0+ (1,0) [0|1] "" IPC
 SG_ ACCSysSlctdMd : 27|2@0+ (1,0) [0|2] "" IPC,TCP
 SG_ BkupPwrMdStrtStpIgntSwtchPrsdRpt : 28|1@0+ (1,0) [0|1] "" CSM,RadioLow
 SG_ VltSwAtvIO : 29|1@0+ (1,0) [0|1] "" CSM,IPC,TCP
 SG_ ValetModeActive : 30|1@0+ (1,0) [0|1] "" CSM,IPC,PDR,RadioLow,TCP
 SG_ TrnsOilChngIO : 31|1@0+ (1,0) [0|1] "" IPC,TCP,VKM
 SG_ HillDscntCtlTgtSetSpd : 32|10@0+ (0.1,0) [0|102.3] "km/h" IPC
 SG_ RdHgtWrn2IndReq : 36|4@0+ (1,0) [0|14] "" IPC
 SG_ LnchCtlWhlSlSts : 48|5@0+ (1,0) [0|21] "" IPC
 SG_ LnchCtlEngRPMSts : 54|6@0+ (1,0) [0|38] "" IPC
 SG_ LnchCtlBrkPresVal : 59|4@0+ (10,0) [0|150] "%" IPC

BO_ 1220 CGM_CAN5_PDU22: 8 CGM
 SG_ LogisticModeStatus : 1|2@0+ (1,0) [0|3] "" CSM,HVAC_FP_F,HVAC_FP_R,PDR,RadioLow,VKM
 SG_ LnCntrEsclnSts : 3|2@0+ (1,0) [0|3] "" TCP
 SG_ InvsblTrlrOprtlSts : 5|2@0+ (1,0) [0|3] "" CSM
 SG_ GlrFrHiBmSts : 7|2@0+ (1,0) [0|2] "" CSM
 SG_ CkBrkLmpsIndOn : 8|1@0+ (1,0) [0|1] "" CSM,IPC
 SG_ CIBAutoBrkRelIndOn : 9|1@0+ (1,0) [0|1] "" IPC
 SG_ BrkLtsAtv : 10|1@0+ (1,0) [0|1] "" CSM
 SG_ AutoHgBmCtrlIO : 11|1@0+ (1,0) [0|1] "" CSM,IPC
 SG_ PAVisObjIndStatReq : 15|2@0+ (1,0) [0|3] "" IPC
 SG_ ClsTrnkLidIO : 16|1@0+ (1,0) [0|1] "" CSM,IPC
 SG_ CkSoftTpIO : 17|1@0+ (1,0) [0|1] "" CSM,IPC
 SG_ CkRrPrkLmpIndOn : 18|1@0+ (1,0) [0|1] "" IPC,TCP
 SG_ CkLoBmsIndOn : 19|1@0+ (1,0) [0|1] "" CSM,IPC,RadioLow,TCP
 SG_ CkFrtPrkLmpsIndOn : 20|1@0+ (1,0) [0|1] "" CSM,IPC,TCP
 SG_ CkFgLmpsIndOn : 21|1@0+ (1,0) [0|1] "" IPC
 SG_ CkDyTmRnngLmpsIndOn : 22|1@0+ (1,0) [0|1] "" CSM,IPC,TCP
 SG_ CkCrnrLmpsIndOn : 23|1@0+ (1,0) [0|1] "" IPC
 SG_ FrntPsMtzdStBltFldIndOn : 24|1@0+ (1,0) [0|1] "" CSM,IPC
 SG_ ESCLTrntheStrWheelWhlStrtgIO : 25|1@0+ (1,0) [0|1] "" IPC
 SG_ DrvStBltRmIndOn : 26|1@0+ (1,0) [0|1] "" IPC
 SG_ DrvShftCntrlReqDndIO : 27|1@0+ (1,0) [0|1] "" CSM,IPC
 SG_ DrMtzdStBltUnIndOn : 28|1@0+ (1,0) [0|1] "" CSM,IPC
 SG_ DrMtzdStBltFldIndOn : 29|1@0+ (1,0) [0|1] "" CSM,IPC
 SG_ DRLAct : 30|1@0+ (1,0) [0|1] "" CSM,IPC
 SG_ CrsCntAtv : 31|1@0+ (1,0) [0|1] "" CSM,IPC
 SG_ LicLpOtIO : 32|1@0+ (1,0) [0|1] "" CSM,IPC,RadioLow,TCP
 SG_ LSCMBAutoBrkRlsIndOn : 33|1@0+ (1,0) [0|1] "" IPC
 SG_ HiBmOtgIndOn : 34|1@0+ (1,0) [0|1] "" CSM,IPC
 SG_ GrdBrkgAct : 35|1@0+ (1,0) [0|1] "" CSM,IPC
 SG_ FrwdVhHdwyAlrtIndOn : 36|1@0+ (1,0) [0|1] "" CSM,IPC,TCP
 SG_ EngFuelInjnSysFltIndOn : 37|1@0+ (1,0) [0|1] "" IPC
 SG_ FrntPsStbltRmIndOn : 38|1@0+ (1,0) [0|1] "" IPC,TCP
 SG_ FrntPsMtzdStBltUnIndOn : 39|1@0+ (1,0) [0|1] "" CSM,IPC
 SG_ RIMOFFIndOn : 40|1@0+ (1,0) [0|1] "" CSM,IPC
 SG_ PrkBrkSwAtv : 41|1@0+ (1,0) [0|1] "" CSM,IPC,RadioLow,TCP,VKM
 SG_ PedtrnProtSysDpl : 42|1@0+ (1,0) [0|1] "" IPC
 SG_ NoSDCrdPrIndOn : 43|1@0+ (1,0) [0|1] "" CSM,RadioLow
 SG_ MovblTpServRqrdIO : 44|1@0+ (1,0) [0|1] "" IPC
 SG_ MovblTpNormzRqrdIO : 45|1@0+ (1,0) [0|1] "" IPC
 SG_ LnCntrMisuseCond : 46|1@0+ (1,0) [0|1] "" TCP
 SG_ LnCntrDrvAwrIndOn : 47|1@0+ (1,0) [0|1] "" TCP
 SG_ RvLpOtIO : 48|1@0+ (1,0) [0|1] "" CSM,IPC,RadioLow,TCP
 SG_ RstrntDplyIndOn : 49|1@0+ (1,0) [0|1] "" IPC
 SG_ RrFgLpOtIO : 50|1@0+ (1,0) [0|1] "" CSM,IPC,TCP
 SG_ RrCrsTrfcAlrtOffIndOn : 51|1@0+ (1,0) [0|1] "" IPC
 SG_ BrkOvrhtdIndOn : 52|1@0+ (1,0) [0|1] "" IPC
 SG_ RearPsStbltVisIndMd : 53|1@0+ (1,0) [0|1] "" CSM,IPC
 SG_ RIMUnIndOn : 54|1@0+ (1,0) [0|1] "" CSM,IPC
 SG_ RIMONIndOn : 55|1@0+ (1,0) [0|1] "" IPC
 SG_ SftTpPlsDnWrngIO : 56|1@0+ (1,0) [0|1] "" CSM,IPC
 SG_ SftTpPlsDnSrtdIO : 57|1@0+ (1,0) [0|1] "" CSM,IPC
 SG_ SftTpMchnOvhtIO : 58|1@0+ (1,0) [0|1] "" CSM,IPC
 SG_ SftTpLtcIO : 59|1@0+ (1,0) [0|1] "" CSM,IPC
 SG_ ServHdlmpsIndOn : 60|1@0+ (1,0) [0|1] "" IPC
 SG_ SerRideSysIO : 61|1@0+ (1,0) [0|1] "" CSM,IPC,TCP
 SG_ SDCrdFllIndOn : 62|1@0+ (1,0) [0|1] "" CSM,RadioLow
 SG_ SDCrdErrIndOn : 63|1@0+ (1,0) [0|1] "" CSM,RadioLow

BO_ 1221 CGM_CAN5_PDU23: 8 CGM
 SG_ LnchCtlModeSts : 1|3@0+ (1,0) [0|7] "" IPC
 SG_ RdHgtMvmtIndReq : 4|3@0+ (1,0) [0|4] "" IPC
 SG_ RdHgtAtLocIndReq : 7|3@0+ (1,0) [0|5] "" IPC
 SG_ TrlrMirVidEnblCstCurrSetVal : 8|3@0+ (1,0) [0|7] "" CSM,RadioLow
 SG_ PARgn : 11|3@0+ (1,0) [0|1] "" IPC
 SG_ RdHgtWrn1IndReq : 14|3@0+ (1,0) [0|6] "" IPC
 SG_ WndPstnStsLF : 18|3@0+ (1,0) [0|7] "" AMP,RadioLow,TCP,VKM
 SG_ TrnsSftMdSt : 21|3@0+ (1,0) [0|3] "" CSM,IPC
 SG_ WndPstnStsRR : 25|3@0+ (1,0) [0|7] "" AMP,RadioLow,TCP,VKM
 SG_ WndPstnStsRF : 28|3@0+ (1,0) [0|7] "" AMP,RadioLow,TCP,VKM
 SG_ WndPstnStsLR : 31|3@0+ (1,0) [0|7] "" AMP,RadioLow,TCP,VKM
 SG_ CltTpTrvAchv_Inv : 32|1@0+ (1,0) [0|1] "" CSM
 SG_ BrkPadLifeFrtDistWrnIndReq : 34|2@0+ (1,0) [0|2] "" IPC
 SG_ AdvdFrtLgtSysIndReq : 36|2@0+ (1,0) [0|3] "" CSM,IPC
 SG_ ACCAutoStSpStat : 38|2@0+ (1,0) [0|3] "" CSM,IPC
 SG_ CmdThrdRwCtStbtVisInd : 40|2@0+ (1,0) [0|3] "" CSM,IPC
 SG_ CmdSndRwRtStbtVisInd : 42|2@0+ (1,0) [0|3] "" CSM,IPC
 SG_ CmdSndRwLtStbtVisInd : 44|2@0+ (1,0) [0|3] "" CSM,IPC
 SG_ CmdSndRwCtStbtVisInd : 46|2@0+ (1,0) [0|3] "" CSM,IPC
 SG_ CltTpTrvAchv : 47|1@0+ (1,0) [0|1] "" CSM
 SG_ DrLckStsLR : 48|2@0+ (1,0) [0|2] "" VKM
 SG_ DrLckStsLF : 50|2@0+ (1,0) [0|2] "" VKM
 SG_ CmdThrdRwRtStbtVisInd : 52|2@0+ (1,0) [0|3] "" CSM,IPC
 SG_ CmdThrdRwLtStbtVisInd : 54|2@0+ (1,0) [0|3] "" CSM,IPC
 SG_ AutoBmSlctAllwd : 56|1@0+ (1,0) [0|1] "" CSM
 SG_ DrSlctdSpdLmtAutMdSpdLmtStat : 58|2@0+ (1,0) [0|3] "" CSM,IPC,TCP
 SG_ DrLckStsRR : 60|2@0+ (1,0) [0|2] "" VKM
 SG_ DrLckStsRF : 62|2@0+ (1,0) [0|2] "" VKM

BO_ 1222 CGM_CAN5_PDU24: 8 CGM
 SG_ PAIM_FaildIndOn : 0|1@0+ (1,0) [0|1] "" CSM,IPC,TCP
 SG_ PAIM_RrOffIndOn : 1|1@0+ (1,0) [0|1] "" IPC,TCP
 SG_ PAIM_DsbldIndOn : 2|1@0+ (1,0) [0|1] "" CSM,IPC
 SG_ PAIM_TeenDrvrPAOffUnvIndOn : 3|1@0+ (1,0) [0|1] "" IPC
 SG_ PAIM_FrtOffIndOn : 4|1@0+ (1,0) [0|1] "" IPC
 SG_ PAIM_SnsrDstbdIndOn : 5|1@0+ (1,0) [0|1] "" CSM,IPC
 SG_ PAIM_SnsrBlckdIndOn : 6|1@0+ (1,0) [0|1] "" CSM,IPC
 SG_ PAIM_SnsrClnIndOn : 7|1@0+ (1,0) [0|1] "" CSM,IPC
 SG_ eLSDActrTrqPctg : 13|8@0+ (0.4,0) [0|102] "%" IPC,PDR
 SG_ eLSDActrTrqPctg_Inv : 14|1@0+ (1,0) [0|1] "" IPC,PDR
 SG_ PAIM_OffIndOn : 15|1@0+ (1,0) [0|1] "" IPC,TCP
 SG_ FourWhlDrvWrnIndReq : 17|4@0+ (1,0) [0|15] "" IPC
 SG_ EnrgMgtLdShdRq : 21|4@0+ (1,0) [0|4] "" CSM,TCP,WCM
 SG_ BrkSysHillStrtAsstStat : 25|3@0+ (1,0) [0|7] "" CSM
 SG_ FrntPsStbltRmIndReq : 29|4@0+ (1,0) [0|7] "" CSM,IPC,TCP
 SG_ CrgBedVwAutoLgtCstCurrSetVal : 32|3@0+ (1,0) [0|7] "" CSM,RadioLow
 SG_ CnvtBkWndPstnSts : 35|3@0+ (1,0) [0|7] "" CSM
 SG_ CTDStat : 38|3@0+ (1,0) [0|5] "" TCP,VKM
 SG_ FrntPsStBltRmOccStat : 41|2@0+ (1,0) [0|2] "" CSM,RadioLow
 SG_ FrntPsStBltRmOccStat_Inv : 42|1@0+ (1,0) [0|1] "" CSM,RadioLow
 SG_ EngAirFiltMonSts : 45|3@0+ (1,0) [0|5] "" CSM,IPC
 SG_ LnDtWrnCntrlFtrSt : 52|3@0+ (1,0) [0|4] "" CSM,TCP
 SG_ FrwdVhImAlrtIndRqst : 55|3@0+ (1,0) [0|7] "" CSM,IPC,RadioLow,TCP
 SG_ AirbgStIndOn : 56|1@0+ (1,0) [0|1] "" IPC,TCP
 SG_ PrkAsstStat : 59|3@0+ (1,0) [0|7] "" CSM,RadioLow
 SG_ NghtVsnSysStat : 62|3@0+ (1,0) [0|7] "" IPC

BO_ 1223 CGM_CAN5_PDU25: 8 CGM
 SG_ FPARS_RtCntr : 3|4@0+ (1,0) [0|14] "" CSM,IPC
 SG_ FPARS_Lt : 7|4@0+ (1,0) [0|14] "" CSM,IPC
 SG_ FPARS_Rt : 11|4@0+ (1,0) [0|14] "" CSM,IPC
 SG_ FPARS_LtCntr : 15|4@0+ (1,0) [0|14] "" CSM,IPC
 SG_ FPLTLI_PrkLmpLtCmd : 17|3@0+ (1,0) [0|4] "" CSM
 SG_ FPLTLI_AuxPrkLmpLtCmd : 20|3@0+ (1,0) [0|4] "" CSM
 SG_ FPLTLI_PrkLmpRtCmd : 23|3@0+ (1,0) [0|4] "" CSM
 SG_ PAVehPathCrv : 27|12@0- (0.001,0) [-2.048|2.047] "" IPC
 SG_ FPLTLI_AuxPrkLmpRtCmd : 30|3@0+ (1,0) [0|4] "" CSM
 SG_ CrwlModeDndRsnIndReq : 40|3@0+ (1,0) [0|4] "" IPC
 SG_ FuelFiltRmnLife : 47|7@0+ (1,0) [0|127] "%" CSM,IPC
 SG_ BSISP_ETRSHydrlcBrkgStsAuth : 49|2@0+ (1,0) [0|2] "" CSM
 SG_ BSISP_ESCActvAuth : 50|1@0+ (1,0) [0|1] "" CSM,PDR,RadioLow
 SG_ BSISP_TCSFaildAuth : 51|1@0+ (1,0) [0|1] "" CSM,TCP
 SG_ MaxChrgSts : 53|2@0+ (1,0) [0|2] "" CSM,IPC
 SG_ ArtcldRnngBrdSt : 58|3@0+ (1,0) [0|6] "" IPC
 SG_ BSISP_ESCSysStsAuth : 61|3@0+ (1,0) [0|4] "" CSM
 SG_ BSISP_TCSActvAuth : 62|1@0+ (1,0) [0|1] "" CSM,PDR,RadioLow,TCP
 SG_ BSISP_TCSDrvrIntntAuth : 63|1@0+ (1,0) [0|1] "" CSM

BO_ 1224 CGM_CAN5_PDU26: 8 CGM
 SG_ BVSCRP_CPSAxlTrqCmdLimStsAuth : 1|2@0+ (1,0) [0|3] "" CSM
 SG_ BVSCRP_ACCAxlTrqCmdReqStsAuth : 4|3@0+ (1,0) [0|4] "" CSM,TCP
 SG_ BVSCRP_ACCAxlTrqCmdLimStsAuth : 6|2@0+ (1,0) [0|3] "" CSM
 SG_ BVSCRP_CruzCtlEnbldAuth : 7|1@0+ (1,0) [0|1] "" CSM,IPC
 SG_ BVSCRP_CltchPdlActPosAuth : 12|8@0+ (0.392157,0) [0|100] "" AMP,CSM,PDR,TCP
 SG_ BVSCRP_CPSAxlTrqCmdReqStsAuth : 15|3@0+ (1,0) [0|6] "" CSM
 SG_ TCTPIR_EstdClchTmpDisp : 19|8@0+ (0.392157,0) [0|100] "%" IPC
 SG_ BVSCRP_CltchPdlActPosAuth_Inv : 20|1@0+ (1,0) [0|1] "" AMP,CSM,PDR,TCP
 SG_ TCTPIR_DrvrNtfn : 27|4@0+ (1,0) [0|8] "" IPC
 SG_ TCTPIR_EstdClchCoolDnTmpTgtDisp : 39|8@0+ (0.392157,0) [0|100] "%" IPC
 SG_ RTPP_TirePrsRRAuth : 46|8@0+ (4,0) [0|1020] "kPaG" CSM,IPC,PDR,RadioLow,TCP,VKM
 SG_ RTPP_TirePrsRRAuth_Inv : 47|1@0+ (1,0) [0|1] "" CSM,IPC,PDR,RadioLow,TCP,VKM
 SG_ RTPP_TirePrsLRAuth : 53|8@0+ (4,0) [0|1020] "kPaG" CSM,IPC,PDR,RadioLow,TCP,VKM
 SG_ RTPP_TirePrsLRAuth_Inv : 54|1@0+ (1,0) [0|1] "" CSM,IPC,PDR,RadioLow,TCP,VKM
 SG_ AdptCrsCntrlEngd : 56|1@0+ (1,0) [0|1] "" CSM,IPC,TCP
 SG_ SGI_PV : 58|2@0+ (1,0) [0|3] "" IPC
 SG_ SGI_ARC : 60|2@0+ (1,0) [0|3] "" IPC
 SG_ SGI_ServStSysIndOn : 61|1@0+ (1,0) [0|1] "" IPC,TCP

BO_ 1225 CGM_CAN5_PDU27: 8 CGM
 SG_ RRSAP_HdrstFwdRrwd : 3|4@0+ (1,0) [0|15] "" CSM,RadioLow
 SG_ RRSAP_HdrstWngsInOut : 7|4@0+ (1,0) [0|15] "" CSM,RadioLow
 SG_ RRSAP_CshBlstrInOut : 11|4@0+ (1,0) [0|15] "" CSM,RadioLow
 SG_ RRSAP_HdrstUpDn : 15|4@0+ (1,0) [0|15] "" CSM,RadioLow
 SG_ RRSAP_BkBlstrInOut : 19|4@0+ (1,0) [0|15] "" CSM,RadioLow
 SG_ RRSAP_LmbrUpDwn : 23|4@0+ (1,0) [0|15] "" CSM,RadioLow
 SG_ RRSAP_BkCshBlstrInOut : 27|4@0+ (1,0) [0|15] "" CSM,RadioLow
 SG_ RRSAP_CshLgthAdjFdRr : 31|4@0+ (1,0) [0|15] "" CSM,RadioLow
 SG_ RRSAP_Massg : 35|4@0+ (1,0) [0|15] "" CSM,RadioLow
 SG_ RRSAP_HdrstUpDnFdRr : 39|4@0+ (1,0) [0|15] "" CSM,RadioLow
 SG_ RRSAP_LmbrFwdRr : 43|4@0+ (1,0) [0|15] "" CSM,RadioLow
 SG_ RRSAP_HdrstTltFwdRr : 47|4@0+ (1,0) [0|15] "" CSM,RadioLow
 SG_ RRSAP_UprShldrFwdRr : 51|4@0+ (1,0) [0|15] "" CSM,RadioLow
 SG_ RRSAP_LmbrUpDnFdRr : 55|4@0+ (1,0) [0|15] "" CSM,RadioLow
 SG_ DrvStBltRmIndReq : 59|4@0+ (1,0) [0|7] "" CSM,IPC
 SG_ AirbgStsIndReq : 63|4@0+ (1,0) [0|7] "" CSM,IPC

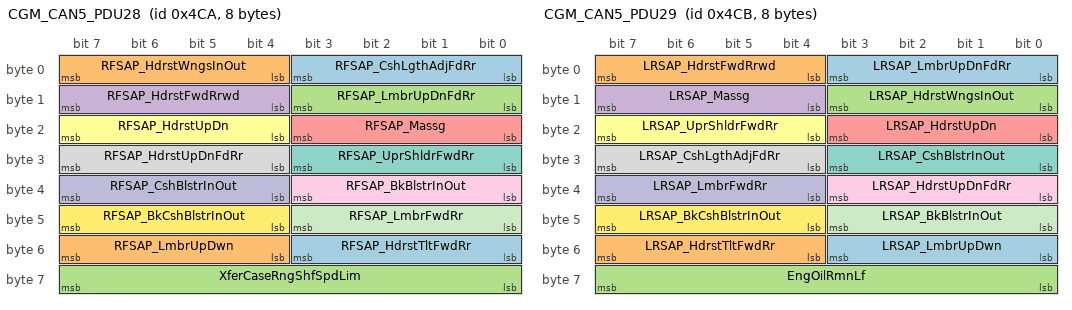
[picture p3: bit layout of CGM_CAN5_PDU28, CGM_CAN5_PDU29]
BO_ 1226 CGM_CAN5_PDU28: 8 CGM
 SG_ RFSAP_CshLgthAdjFdRr : 3|4@0+ (1,0) [0|15] "" CSM,RadioLow
 SG_ RFSAP_HdrstWngsInOut : 7|4@0+ (1,0) [0|15] "" CSM,RadioLow
 SG_ RFSAP_LmbrUpDnFdRr : 11|4@0+ (1,0) [0|15] "" CSM,RadioLow
 SG_ RFSAP_HdrstFwdRrwd : 15|4@0+ (1,0) [0|15] "" CSM,RadioLow
 SG_ RFSAP_Massg : 19|4@0+ (1,0) [0|15] "" CSM,RadioLow
 SG_ RFSAP_HdrstUpDn : 23|4@0+ (1,0) [0|15] "" CSM,RadioLow
 SG_ RFSAP_UprShldrFwdRr : 27|4@0+ (1,0) [0|15] "" CSM,RadioLow
 SG_ RFSAP_HdrstUpDnFdRr : 31|4@0+ (1,0) [0|15] "" CSM,RadioLow
 SG_ RFSAP_BkBlstrInOut : 35|4@0+ (1,0) [0|15] "" CSM,RadioLow
 SG_ RFSAP_CshBlstrInOut : 39|4@0+ (1,0) [0|15] "" CSM,RadioLow
 SG_ RFSAP_LmbrFwdRr : 43|4@0+ (1,0) [0|15] "" CSM,RadioLow
 SG_ RFSAP_BkCshBlstrInOut : 47|4@0+ (1,0) [0|15] "" CSM,RadioLow
 SG_ RFSAP_HdrstTltFwdRr : 51|4@0+ (1,0) [0|15] "" CSM,RadioLow
 SG_ RFSAP_LmbrUpDwn : 55|4@0+ (1,0) [0|15] "" CSM,RadioLow
 SG_ XferCaseRngShfSpdLim : 63|8@0+ (1,0) [0|255] "km/h" IPC

BO_ 1227 CGM_CAN5_PDU29: 8 CGM
 SG_ LRSAP_LmbrUpDnFdRr : 3|4@0+ (1,0) [0|15] "" CSM,RadioLow
 SG_ LRSAP_HdrstFwdRrwd : 7|4@0+ (1,0) [0|15] "" CSM,RadioLow
 SG_ LRSAP_HdrstWngsInOut : 11|4@0+ (1,0) [0|15] "" CSM,RadioLow
 SG_ LRSAP_Massg : 15|4@0+ (1,0) [0|15] "" CSM,RadioLow
 SG_ LRSAP_HdrstUpDn : 19|4@0+ (1,0) [0|15] "" CSM,RadioLow
 SG_ LRSAP_UprShldrFwdRr : 23|4@0+ (1,0) [0|15] "" CSM,RadioLow
 SG_ LRSAP_CshBlstrInOut : 27|4@0+ (1,0) [0|15] "" CSM,RadioLow
 SG_ LRSAP_CshLgthAdjFdRr : 31|4@0+ (1,0) [0|15] "" CSM,RadioLow
 SG_ LRSAP_HdrstUpDnFdRr : 35|4@0+ (1,0) [0|15] "" CSM,RadioLow
 SG_ LRSAP_LmbrFwdRr : 39|4@0+ (1,0) [0|15] "" CSM,RadioLow
 SG_ LRSAP_BkBlstrInOut : 43|4@0+ (1,0) [0|15] "" CSM,RadioLow
 SG_ LRSAP_BkCshBlstrInOut : 47|4@0+ (1,0) [0|15] "" CSM,RadioLow
 SG_ LRSAP_LmbrUpDwn : 51|4@0+ (1,0) [0|15] "" CSM,RadioLow
 SG_ LRSAP_HdrstTltFwdRr : 55|4@0+ (1,0) [0|15] "" CSM,RadioLow
 SG_ EngOilRmnLf : 63|8@0+ (0.392157,0) [0|100] "%" CSM,IPC,RadioLow,TCP,VKM

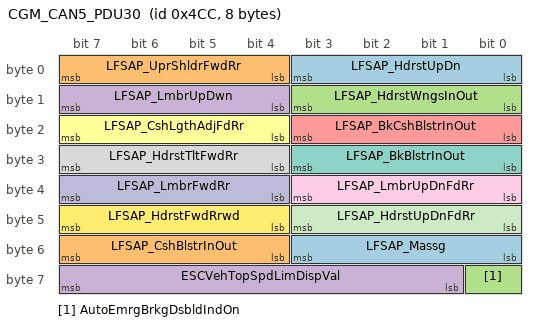
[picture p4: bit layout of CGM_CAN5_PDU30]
BO_ 1228 CGM_CAN5_PDU30: 8 CGM
 SG_ LFSAP_HdrstUpDn : 3|4@0+ (1,0) [0|15] "" CSM,RadioLow
 SG_ LFSAP_UprShldrFwdRr : 7|4@0+ (1,0) [0|15] "" CSM,RadioLow
 SG_ LFSAP_HdrstWngsInOut : 11|4@0+ (1,0) [0|15] "" CSM,RadioLow
 SG_ LFSAP_LmbrUpDwn : 15|4@0+ (1,0) [0|15] "" CSM,RadioLow
 SG_ LFSAP_BkCshBlstrInOut : 19|4@0+ (1,0) [0|15] "" CSM,RadioLow
 SG_ LFSAP_CshLgthAdjFdRr : 23|4@0+ (1,0) [0|15] "" CSM,RadioLow
 SG_ LFSAP_BkBlstrInOut : 27|4@0+ (1,0) [0|15] "" CSM,RadioLow
 SG_ LFSAP_HdrstTltFwdRr : 31|4@0+ (1,0) [0|15] "" CSM,RadioLow
 SG_ LFSAP_LmbrUpDnFdRr : 35|4@0+ (1,0) [0|15] "" CSM,RadioLow
 SG_ LFSAP_LmbrFwdRr : 39|4@0+ (1,0) [0|15] "" CSM,RadioLow
 SG_ LFSAP_HdrstUpDnFdRr : 43|4@0+ (1,0) [0|15] "" CSM,RadioLow
 SG_ LFSAP_HdrstFwdRrwd : 47|4@0+ (1,0) [0|15] "" CSM,RadioLow
 SG_ LFSAP_Massg : 51|4@0+ (1,0) [0|15] "" CSM,RadioLow
 SG_ LFSAP_CshBlstrInOut : 55|4@0+ (1,0) [0|15] "" CSM,RadioLow
 SG_ AutoEmrgBrkgDsbldIndOn : 56|1@0+ (1,0) [0|1] "" CSM,IPC
 SG_ ESCVehTopSpdLimDispVal : 63|7@0+ (1,0) [0|127] "kph" IPC

BO_ 1230 CGM_CAN5_PDU31: 6 CGM
 SG_ PTCrnkAct : 3|1@0+ (1,0) [0|1] "" IPC,TCP
 SG_ DrvShftCntrlTrgtGr : 7|4@0+ (1,0) [0|10] "" CSM,IPC

BO_ 1240 CGM_CAN5_PDU32: 8 CGM
 SG_ DrvrAlrtTypCstAvlFlg3 : 0|1@0+ (1,0) [0|1] "" CSM,RadioLow
 SG_ DrvrAlrtTypCstAvlFlg2 : 1|1@0+ (1,0) [0|1] "" CSM,RadioLow
 SG_ DrvrAlrtTypCstAvlFlg1 : 2|1@0+ (1,0) [0|1] "" CSM,RadioLow
 SG_ CrgBedVwAutoLgtCstSetAval : 3|1@0+ (1,0) [0|1] "" CSM,RadioLow
 SG_ RrClsrAjrStat : 4|1@0+ (1,0) [0|1] "" AMP,CSM,IPC,RadioLow,TCP,VKM
 SG_ RrClsrAjrStat_Inv : 5|1@0+ (1,0) [0|1] "" CSM,IPC,TCP,VKM
 SG_ RRDrAjrStat : 6|1@0+ (1,0) [0|1] "" AMP,CSM,IPC,RadioLow,TCP,VKM
 SG_ RRDrAjrStat_Inv : 7|1@0+ (1,0) [0|1] "" CSM,IPC,TCP,VKM
 SG_ EsyExtCstStAvl : 8|1@0+ (1,0) [0|1] "" CSM,RadioLow
 SG_ DsplyTrgVdOn : 9|1@0+ (1,0) [0|1] "" CSM,RadioLow
 SG_ DspFrnt360CmrON : 10|1@0+ (1,0) [0|1] "" CSM,RadioLow
 SG_ DrvrAlrtTypCstStAvl : 11|1@0+ (1,0) [0|1] "" CSM,RadioLow
 SG_ DrvrAlrtTypCstAvlFlg7 : 12|1@0+ (1,0) [0|1] "" CSM,RadioLow
 SG_ DrvrAlrtTypCstAvlFlg6 : 13|1@0+ (1,0) [0|1] "" CSM,RadioLow
 SG_ DrvrAlrtTypCstAvlFlg5 : 14|1@0+ (1,0) [0|1] "" CSM,RadioLow
 SG_ DrvrAlrtTypCstAvlFlg4 : 15|1@0+ (1,0) [0|1] "" CSM,RadioLow
 SG_ LnChgAlrtLmtdTrlrIndOn : 16|1@0+ (1,0) [0|1] "" IPC
 SG_ LnChgAlrtCstStAvl : 17|1@0+ (1,0) [0|1] "" CSM,RadioLow,TCP
 SG_ JckKnfDtnCstSetAval : 18|1@0+ (1,0) [0|1] "" CSM,RadioLow
 SG_ HptcStFldIndOn : 19|1@0+ (1,0) [0|1] "" IPC,TCP
 SG_ GoNotfrCstStAvl : 20|1@0+ (1,0) [0|1] "" CSM,RadioLow
 SG_ GlrFrHgBmRspTypCstStAvl : 21|1@0+ (1,0) [0|1] "" CSM,RadioLow
 SG_ FrwdImpMtgnOpSlctCstStAvl : 22|1@0+ (1,0) [0|1] "" CSM,RadioLow,TCP
 SG_ FrntPCMRspTypCstStAvl : 23|1@0+ (1,0) [0|1] "" CSM,RadioLow
 SG_ RnngBrdManDplyCstSetSelbl : 24|1@0+ (1,0) [0|1] "" CSM,RadioLow
 SG_ RnngBrdManDplyCstSetAval : 25|1@0+ (1,0) [0|1] "" CSM,RadioLow
 SG_ RnngBrdAutoDplyCstSetAval : 26|1@0+ (1,0) [0|1] "" CSM,RadioLow
 SG_ PrkAsstTrHtchPsntCstStAvl : 28|1@0+ (1,0) [0|1] "" CSM,RadioLow
 SG_ PrkAsstONOFFCstStAvl : 29|1@0+ (1,0) [0|1] "" CSM,RadioLow
 SG_ LtRtHnTrCstStAvl : 30|1@0+ (1,0) [0|1] "" CSM,RadioLow
 SG_ LnChgAlrtSysOffIndOn : 31|1@0+ (1,0) [0|1] "" IPC,TCP
 SG_ SBZAlrtCstAvlFlg6 : 32|1@0+ (1,0) [0|1] "" CSM,RadioLow
 SG_ SBZAlrtCstAvlFlg5 : 33|1@0+ (1,0) [0|1] "" CSM,RadioLow
 SG_ SBZAlrtCstAvlFlg4 : 34|1@0+ (1,0) [0|1] "" CSM,RadioLow
 SG_ SBZAlrtCstAvlFlg3 : 35|1@0+ (1,0) [0|1] "" CSM,RadioLow
 SG_ SBZAlrtCstAvlFlg2 : 36|1@0+ (1,0) [0|1] "" CSM,RadioLow
 SG_ SBZAlrtCstAvlFlg1 : 37|1@0+ (1,0) [0|1] "" CSM,RadioLow
 SG_ RrVwPrkAstSymCsStAvl : 38|1@0+ (1,0) [0|1] "" CSM,RadioLow
 SG_ RrCrsTrfcAlrtCstStAvl : 39|1@0+ (1,0) [0|1] "" CSM,RadioLow
 SG_ TargaTopAjrStat : 40|1@0+ (1,0) [0|1] "" AMP,CSM,RadioLow
 SG_ StBltTghtngCstStAv : 41|1@0+ (1,0) [0|1] "" CSM,RadioLow
 SG_ SrrndVwLghtCsStAvl : 42|1@0+ (1,0) [0|1] "" CSM,RadioLow
 SG_ ServSdDtcSysIndOn : 43|1@0+ (1,0) [0|1] "" IPC,TCP
 SG_ SdDtcTempUnvIndOn : 44|1@0+ (1,0) [0|1] "" IPC
 SG_ SBZAlrtOffIndOn : 45|1@0+ (1,0) [0|1] "" IPC
 SG_ SBZAlrtCstStAvl : 46|1@0+ (1,0) [0|1] "" CSM,RadioLow
 SG_ SBZAlrtCstAvlFlg7 : 47|1@0+ (1,0) [0|1] "" CSM,RadioLow
 SG_ EngAirFiltLifeRmn : 49|7@0+ (1,0) [0|127] "%" CSM,IPC,TCP
 SG_ TrnSigSwRtActv : 50|1@0+ (1,0) [0|1] "" CSM,TCP
 SG_ TrnSigSwLtActv : 51|1@0+ (1,0) [0|1] "" CSM,TCP
 SG_ TrlrMirVidGdlnsCstSetAval : 52|1@0+ (1,0) [0|1] "" CSM,RadioLow
 SG_ TrlrMirVidEnblCstSetAval : 53|1@0+ (1,0) [0|1] "" CSM,RadioLow
 SG_ TrlrConnStat : 54|1@0+ (1,0) [0|1] "" CSM,RadioLow
 SG_ TrffcLgtAsstCstSetAval : 55|1@0+ (1,0) [0|1] "" CSM,RadioLow
 SG_ PwrRrClsrCstCurrSetVal : 58|3@0+ (1,0) [0|7] "" CSM,RadioLow

BO_ 1241 CGM_CAN5_PDU33: 8 CGM
 SG_ GlrFrHgBmRspTypCstCurSetVal : 1|3@0+ (1,0) [0|7] "" CSM,RadioLow
 SG_ FrwdImpMtgnOpSlctCstCrStVal : 4|3@0+ (1,0) [0|7] "" CSM,RadioLow,TCP
 SG_ FrntPCMRspTypCstCrStVal : 7|3@0+ (1,0) [0|7] "" CSM,RadioLow
 SG_ LnChgAlrtCstCrStVal : 8|3@0+ (1,0) [0|7] "" CSM,RadioLow,TCP
 SG_ JckKnfDtnCstCurrSetVal : 11|3@0+ (1,0) [0|7] "" CSM,RadioLow
 SG_ GoNotfrCstCrStVal : 14|3@0+ (1,0) [0|7] "" CSM,RadioLow
 SG_ PrkAsstONOFFCstCrStVal : 18|3@0+ (1,0) [0|7] "" CSM,RadioLow
 SG_ LtRtHnTrCstCurSetVal : 21|3@0+ (1,0) [0|7] "" CSM,RadioLow
 SG_ RnngBrdAutoDplyCstCurrSetVal : 25|3@0+ (1,0) [0|6] "" CSM,RadioLow
 SG_ PFASndSeltnCstCurrSetVal : 28|3@0+ (1,0) [0|7] "" CSM
 SG_ PrkAsstTrHtchPsntCstCrStVal : 31|3@0+ (1,0) [0|7] "" CSM,RadioLow
 SG_ RrVwPrkAstSymCsCrStVal : 32|3@0+ (1,0) [0|7] "" CSM,RadioLow
 SG_ RrCrsTrfcAlrtCstCrStVal : 35|3@0+ (1,0) [0|7] "" CSM,RadioLow
 SG_ RnngBrdManDplyCstCurrSetVal : 38|3@0+ (1,0) [0|7] "" CSM,RadioLow
 SG_ SrrndVwLghtCsCrStVal : 42|3@0+ (1,0) [0|7] "" CSM,RadioLow
 SG_ SBZAlrtCstCrStVal : 45|3@0+ (1,0) [0|7] "" CSM,RadioLow
 SG_ TrlrMirVidGdlnsCstCurrSetVal : 49|3@0+ (1,0) [0|7] "" CSM,RadioLow
 SG_ TrffcLgtAsstCstCurrSetVal : 52|3@0+ (1,0) [0|7] "" CSM,RadioLow
 SG_ StBltTghtngCstCrStVal : 55|3@0+ (1,0) [0|7] "" CSM,RadioLow
 SG_ CnvtblTopTneuAjrStat : 56|1@0+ (1,0) [0|1] "" AMP
 SG_ LftglsAjrStat : 57|1@0+ (1,0) [0|1] "" AMP,IPC,VKM
 SG_ LftglsAjrStat_Inv : 58|1@0+ (1,0) [0|1] "" AMP,IPC,VKM
 SG_ LRDrAjrStat : 59|1@0+ (1,0) [0|1] "" AMP,CSM,IPC,RadioLow,TCP,VKM
 SG_ LRDrAjrStat_Inv : 60|1@0+ (1,0) [0|1] "" CSM,TCP,VKM
 SG_ ElvtdIdlCstCrStVal : 62|2@0+ (1,0) [0|2] "" CSM,IPC,RadioLow

BA_DEF_ SG_  "SignalType" STRING ;
BA_DEF_ SG_  "SignalLongName" STRING ;
BA_DEF_ BO_  "GenMsgCycleTime" INT 0 10000;
BA_DEF_ BO_  "GenMsgSendType" ENUM "cyclicX","spontanX","cyclicIfActiveX","spontanWithDelay","cyclicAndSpontanX","cyclicAndSpontanWithDelay","spontanWithRepetition","cyclicIfActiveAndSpontanWD";
BA_DEF_DEF_  "SignalType" "";
BA_DEF_DEF_  "SignalLongName" "";
BA_DEF_DEF_  "GenMsgCycleTime" 0;
BA_DEF_DEF_  "GenMsgSendType" "cyclicX";
BA_ "GenMsgCycleTime" BO_ 1425 1000;
BA_ "GenMsgCycleTime" BO_ 1427 1000;
BA_ "GenMsgCycleTime" BO_ 1188 1000;
BA_ "GenMsgCycleTime" BO_ 1189 1000;
BA_ "GenMsgCycleTime" BO_ 1190 1000;
BA_ "GenMsgCycleTime" BO_ 1191 1000;
BA_ "GenMsgCycleTime" BO_ 1192 1000;
BA_ "GenMsgCycleTime" BO_ 1193 1000;
BA_ "GenMsgCycleTime" BO_ 1197 1000;
BA_ "GenMsgCycleTime" BO_ 1198 1000;
BA_ "GenMsgCycleTime" BO_ 1199 1000;
BA_ "GenMsgCycleTime" BO_ 1200 1000;
BA_ "GenMsgCycleTime" BO_ 1201 1000;
BA_ "GenMsgCycleTime" BO_ 1219 1000;
BA_ "GenMsgCycleTime" BO_ 1220 1000;
BA_ "GenMsgCycleTime" BO_ 1221 1000;
BA_ "GenMsgCycleTime" BO_ 1222 1000;
BA_ "GenMsgCycleTime" BO_ 1223 1000;
BA_ "GenMsgCycleTime" BO_ 1224 1000;
BA_ "GenMsgCycleTime" BO_ 1225 1000;
BA_ "GenMsgCycleTime" BO_ 1226 1000;
BA_ "GenMsgCycleTime" BO_ 1227 1000;
BA_ "GenMsgCycleTime" BO_ 1228 1000;
BA_ "GenMsgCycleTime" BO_ 1230 1000;
BA_ "GenMsgCycleTime" BO_ 1240 1000;
BA_ "GenMsgCycleTime" BO_ 1241 1000;
BA_ "SignalType" SG_ 1425 PTOSet2SpdCstAvlFlg4 "ENM";
BA_ "SignalLongName" SG_ 1425 PTOSet2SpdCstAvlFlg4 "Power Take Off Set 2 Speed Customization Availability Flag 4";
BA_ "SignalType" SG_ 1425 PTOSet2SpdCstAvlFlg3 "ENM";
BA_ "SignalLongName" SG_ 1425 PTOSet2SpdCstAvlFlg3 "Power Take Off Set 2 Speed Customization Availability Flag 3";
BA_ "SignalType" SG_ 1425 PTOSet2SpdCstAvlFlg2 "ENM";
BA_ "SignalLongName" SG_ 1425 PTOSet2SpdCstAvlFlg2 "Power Take Off Set 2 Speed Customization Availability Flag 2";
BA_ "SignalType" SG_ 1425 PTOSet2SpdCstAvlFlg15 "ENM";
BA_ "SignalLongName" SG_ 1425 PTOSet2SpdCstAvlFlg15 "Power Take Off Set 2 Speed Customization Availability Flag 15";
BA_ "SignalType" SG_ 1425 PTOSet2SpdCstAvlFlg14 "ENM";
BA_ "SignalLongName" SG_ 1425 PTOSet2SpdCstAvlFlg14 "Power Take Off Set 2 Speed Customization Availability Flag 14";
BA_ "SignalType" SG_ 1425 PTOSet2SpdCstAvlFlg13 "ENM";
BA_ "SignalLongName" SG_ 1425 PTOSet2SpdCstAvlFlg13 "Power Take Off Set 2 Speed Customization Availability Flag 13";
BA_ "SignalType" SG_ 1425 PTOSet2SpdCstAvlFlg12 "ENM";
BA_ "SignalLongName" SG_ 1425 PTOSet2SpdCstAvlFlg12 "Power Take Off Set 2 Speed Customization Availability Flag 12";
BA_ "SignalType" SG_ 1425 PTOSet2SpdCstAvlFlg11 "ENM";
BA_ "SignalLongName" SG_ 1425 PTOSet2SpdCstAvlFlg11 "Power Take Off Set 2 Speed Customization Availability Flag 11";
BA_ "SignalType" SG_ 1425 PTOStndbySpdCstAvlFlg3 "ENM";
BA_ "SignalLongName" SG_ 1425 PTOStndbySpdCstAvlFlg3 "Power Take Off Standby Speed Customization Availability Flag 3";
BA_ "SignalType" SG_ 1425 PTOStndbySpdCstAvlFlg2 "ENM";
BA_ "SignalLongName" SG_ 1425 PTOStndbySpdCstAvlFlg2 "Power Take Off Standby Speed Customization Availability Flag 2";
BA_ "SignalType" SG_ 1425 PTOStndbySpdCstAvlFlg1 "ENM";
BA_ "SignalLongName" SG_ 1425 PTOStndbySpdCstAvlFlg1 "Power Take Off Standby Speed Customization Availability Flag 1";
BA_ "SignalType" SG_ 1425 PTOSet2SpdCstAvlFlg9 "ENM";
BA_ "SignalLongName" SG_ 1425 PTOSet2SpdCstAvlFlg9 "Power Take Off Set 2 Speed Customization Availability Flag 9";
BA_ "SignalType" SG_ 1425 PTOSet2SpdCstAvlFlg8 "ENM";
BA_ "SignalLongName" SG_ 1425 PTOSet2SpdCstAvlFlg8 "Power Take Off Set 2 Speed Customization Availability Flag 8";
BA_ "SignalType" SG_ 1425 PTOSet2SpdCstAvlFlg7 "ENM";
BA_ "SignalLongName" SG_ 1425 PTOSet2SpdCstAvlFlg7 "Power Take Off Set 2 Speed Customization Availability Flag 7";
BA_ "SignalType" SG_ 1425 PTOSet2SpdCstAvlFlg6 "ENM";
BA_ "SignalLongName" SG_ 1425 PTOSet2SpdCstAvlFlg6 "Power Take Off Set 2 Speed Customization Availability Flag 6";
BA_ "SignalType" SG_ 1425 PTOSet2SpdCstAvlFlg5 "ENM";
BA_ "SignalLongName" SG_ 1425 PTOSet2SpdCstAvlFlg5 "Power Take Off Set 2 Speed Customization Availability Flag 5";
BA_ "SignalType" SG_ 1425 PTOTpStpSpdCstAvlFlg4 "ENM";
BA_ "SignalLongName" SG_ 1425 PTOTpStpSpdCstAvlFlg4 "Power Take Off Tap Step Speed Customization Availability Flag 4";
BA_ "SignalType" SG_ 1425 PTOTpStpSpdCstAvlFlg3 "ENM";
BA_ "SignalLongName" SG_ 1425 PTOTpStpSpdCstAvlFlg3 "Power Take Off Tap Step Speed Customization Availability Flag 3";
BA_ "SignalType" SG_ 1425 PTOTpStpSpdCstAvlFlg2 "ENM";
BA_ "SignalLongName" SG_ 1425 PTOTpStpSpdCstAvlFlg2 "Power Take Off Tap Step Speed Customization Availability Flag 2";
BA_ "SignalType" SG_ 1425 PTOTpStpSpdCstAvlFlg1 "ENM";
BA_ "SignalLongName" SG_ 1425 PTOTpStpSpdCstAvlFlg1 "Power Take Off Tap Step Speed Customization Availability Flag 1";
BA_ "SignalType" SG_ 1425 PTOStndbySpdCstAvlFlg7 "ENM";
BA_ "SignalLongName" SG_ 1425 PTOStndbySpdCstAvlFlg7 "Power Take Off Standby Speed Customization Availability Flag 7";
BA_ "SignalType" SG_ 1425 PTOStndbySpdCstAvlFlg6 "ENM";
BA_ "SignalLongName" SG_ 1425 PTOStndbySpdCstAvlFlg6 "Power Take Off Standby Speed Customization Availability Flag 6";
BA_ "SignalType" SG_ 1425 PTOStndbySpdCstAvlFlg5 "ENM";
BA_ "SignalLongName" SG_ 1425 PTOStndbySpdCstAvlFlg5 "Power Take Off Standby Speed Customization Availability Flag 5";
BA_ "SignalType" SG_ 1425 PTOStndbySpdCstAvlFlg4 "ENM";
BA_ "SignalLongName" SG_ 1425 PTOStndbySpdCstAvlFlg4 "Power Take Off Standby Speed Customization Availability Flag 4";
BA_ "SignalType" SG_ 1425 UpftrSnwPlwIndReq "ENM";
BA_ "SignalLongName" SG_ 1425 UpftrSnwPlwIndReq "Upfitter Snow Plow Indication Request";
BA_ "SignalType" SG_ 1425 UpftrRrAprchPrtctnIndReq "ENM";
BA_ "SignalLongName" SG_ 1425 UpftrRrAprchPrtctnIndReq "Upfitter Rear Approach Protection Indication Request";
BA_ "SignalType" SG_ 1425 PTOTpStpSpdCstAvlFlg7 "ENM";
BA_ "SignalLongName" SG_ 1425 PTOTpStpSpdCstAvlFlg7 "Power Take Off Tap Step Speed Customization Availability Flag 7";
BA_ "SignalType" SG_ 1425 PTOTpStpSpdCstAvlFlg6 "ENM";
BA_ "SignalLongName" SG_ 1425 PTOTpStpSpdCstAvlFlg6 "Power Take Off Tap Step Speed Customization Availability Flag 6";
BA_ "SignalType" SG_ 1425 PTOTpStpSpdCstAvlFlg5 "ENM";
BA_ "SignalLongName" SG_ 1425 PTOTpStpSpdCstAvlFlg5 "Power Take Off Tap Step Speed Customization Availability Flag 5";
BA_ "SignalLongName" SG_ 1425 IBS12VEstdBatTemp "IBS 12V Estimated Battery Temperature";
BA_ "SignalType" SG_ 1425 IBS12VEstdBatTemp_Inv "ENM";
BA_ "SignalLongName" SG_ 1425 IBS12VEstdBatTemp_Inv "IBS 12V Estimated Battery Temperature Invalid";
BA_ "SignalType" SG_ 1425 UpftrRadioMutReqd "ENM";
BA_ "SignalLongName" SG_ 1425 UpftrRadioMutReqd "Upfitter Radio Mute Requested";
BA_ "SignalType" SG_ 1425 UpftrBkupCamActvnReqd "ENM";
BA_ "SignalLongName" SG_ 1425 UpftrBkupCamActvnReqd "Upfitter Backup Camera Activation Requested";
BA_ "SignalType" SG_ 1425 UpftrVehStrtEnblIndReq "ENM";
BA_ "SignalLongName" SG_ 1425 UpftrVehStrtEnblIndReq "Upfitter Vehicle Start Enable Indication Request";
BA_ "SignalType" SG_ 1425 TransOilFiltChgIndOn "ENM";
BA_ "SignalLongName" SG_ 1425 TransOilFiltChgIndOn "Transmission Oil Filter Change Indication On";
BA_ "SignalLongName" SG_ 1427 IBSRwBatSOC "IBS 12V Battery State of Charge";
BA_ "SignalLongName" SG_ 1427 IBSRwBatSOCErr "IBS Raw Battery SOC Error";
BA_ "SignalLongName" SG_ 1427 TransOilFiltRmnLife "Transmission Oil Filter Remaining Life";
BA_ "SignalType" SG_ 1188 StBltTghtngCstAvlFlg7 "ENM";
BA_ "SignalLongName" SG_ 1188 StBltTghtngCstAvlFlg7 "Seat Belt Tightening CustomizationAvailabilityFlag7";
BA_ "SignalType" SG_ 1188 StBltTghtngCstAvlFlg6 "ENM";
BA_ "SignalLongName" SG_ 1188 StBltTghtngCstAvlFlg6 "Seat Belt Tightening CustomizationAvailabilityFlag6";
BA_ "SignalType" SG_ 1188 StBltTghtngCstAvlFlg5 "ENM";
BA_ "SignalLongName" SG_ 1188 StBltTghtngCstAvlFlg5 "Seat Belt Tightening CustomizationAvailabilityFlag5";
BA_ "SignalType" SG_ 1188 StBltTghtngCstAvlFlg4 "ENM";
BA_ "SignalLongName" SG_ 1188 StBltTghtngCstAvlFlg4 "Seat Belt Tightening CustomizationAvailabilityFlag4";
BA_ "SignalType" SG_ 1188 StBltTghtngCstAvlFlg3 "ENM";
BA_ "SignalLongName" SG_ 1188 StBltTghtngCstAvlFlg3 "Seat Belt Tightening CustomizationAvailabilityFlag3";
BA_ "SignalType" SG_ 1188 StBltTghtngCstAvlFlg2 "ENM";
BA_ "SignalLongName" SG_ 1188 StBltTghtngCstAvlFlg2 "Seat Belt Tightening CustomizationAvailabilityFlag2";
BA_ "SignalType" SG_ 1188 StBltTghtngCstAvlFlg1 "ENM";
BA_ "SignalLongName" SG_ 1188 StBltTghtngCstAvlFlg1 "Seat Belt Tightening CustomizationAvailabilityFlag1";
BA_ "SignalType" SG_ 1188 RrCrsTrfcAlrtCstAvlFlg7 "ENM";
BA_ "SignalLongName" SG_ 1188 RrCrsTrfcAlrtCstAvlFlg7 "RearCrossTrafficAlertCustomizationAvailabilityFlag7";
BA_ "SignalType" SG_ 1188 TrnsOlTmpSnsPrs "ENM";
BA_ "SignalLongName" SG_ 1188 TrnsOlTmpSnsPrs "Transmission Oil Temperature Sensor Present";
BA_ "SignalType" SG_ 1188 TrffcLgtAsstCstAvlFlg7 "ENM";
BA_ "SignalLongName" SG_ 1188 TrffcLgtAsstCstAvlFlg7 "Traffic Light Assist Customization Availability Flag 7";
BA_ "SignalType" SG_ 1188 TrffcLgtAsstCstAvlFlg6 "ENM";
BA_ "SignalLongName" SG_ 1188 TrffcLgtAsstCstAvlFlg6 "Traffic Light Assist Customization Availability Flag 6";
BA_ "SignalType" SG_ 1188 TrffcLgtAsstCstAvlFlg5 "ENM";
BA_ "SignalLongName" SG_ 1188 TrffcLgtAsstCstAvlFlg5 "Traffic Light Assist Customization Availability Flag 5";
BA_ "SignalType" SG_ 1188 TrffcLgtAsstCstAvlFlg4 "ENM";
BA_ "SignalLongName" SG_ 1188 TrffcLgtAsstCstAvlFlg4 "Traffic Light Assist Customization Availability Flag 4";
BA_ "SignalType" SG_ 1188 TrffcLgtAsstCstAvlFlg3 "ENM";
BA_ "SignalLongName" SG_ 1188 TrffcLgtAsstCstAvlFlg3 "Traffic Light Assist Customization Availability Flag 3";
BA_ "SignalType" SG_ 1188 TrffcLgtAsstCstAvlFlg2 "ENM";
BA_ "SignalLongName" SG_ 1188 TrffcLgtAsstCstAvlFlg2 "Traffic Light Assist Customization Availability Flag 2";
BA_ "SignalType" SG_ 1188 TrffcLgtAsstCstAvlFlg1 "ENM";
BA_ "SignalLongName" SG_ 1188 TrffcLgtAsstCstAvlFlg1 "Traffic Light Assist Customization Availability Flag 1";
BA_ "SignalLongName" SG_ 1188 DEFWVSL_S1SpdLmt "Diesel Exhaust Fluid Warning Vehicle Speed Limit : Stage 1 Vehicle Speed Limit";
BA_ "SignalLongName" SG_ 1188 DEFWVSL_S2SpdLmt "Diesel Exhaust Fluid Warning Vehicle Speed Limit : Stage 2 Vehicle Speed Limit";
BA_ "SignalLongName" SG_ 1188 DEFWVSL_S3SpdLmt "Diesel Exhaust Fluid Warning Vehicle Speed Limit : Stage 3 Vehicle Speed Limit";
BA_ "SignalLongName" SG_ 1188 CustNonUsblSOC "Customer Non Usable State of Charge";
BA_ "SignalType" SG_ 1188 CustNonUsblSOC_DuD "ENM";
BA_ "SignalLongName" SG_ 1188 CustNonUsblSOC_DuD "Customer Non Usable State of Charge Don't Use Data";
BA_ "SignalLongName" SG_ 1188 ClmCtlCbnAirCondCustLdEstd "Climate Control Cabin Air Conditioning Customer Load Estimated";
BA_ "SignalType" SG_ 1189 GoNotfrCstAvlFlg7 "ENM";
BA_ "SignalLongName" SG_ 1189 GoNotfrCstAvlFlg7 "GoNotifierCustomizationAvailabilityFlag7";
BA_ "SignalType" SG_ 1189 GoNotfrCstAvlFlg6 "ENM";
BA_ "SignalLongName" SG_ 1189 GoNotfrCstAvlFlg6 "GoNotifierCustomizationAvailabilityFlag6";
BA_ "SignalType" SG_ 1189 GoNotfrCstAvlFlg5 "ENM";
BA_ "SignalLongName" SG_ 1189 GoNotfrCstAvlFlg5 "GoNotifierCustomizationAvailabilityFlag5";
BA_ "SignalType" SG_ 1189 GoNotfrCstAvlFlg4 "ENM";
BA_ "SignalLongName" SG_ 1189 GoNotfrCstAvlFlg4 "GoNotifierCustomizationAvailabilityFlag4";
BA_ "SignalType" SG_ 1189 GoNotfrCstAvlFlg3 "ENM";
BA_ "SignalLongName" SG_ 1189 GoNotfrCstAvlFlg3 "GoNotifierCustomizationAvailabilityFlag3";
BA_ "SignalType" SG_ 1189 GoNotfrCstAvlFlg2 "ENM";
BA_ "SignalLongName" SG_ 1189 GoNotfrCstAvlFlg2 "GoNotifierCustomizationAvailabilityFlag2";
BA_ "SignalType" SG_ 1189 GoNotfrCstAvlFlg1 "ENM";
BA_ "SignalLongName" SG_ 1189 GoNotfrCstAvlFlg1 "GoNotifierCustomizationAvailabilityFlag1";
BA_ "SignalType" SG_ 1189 GlrFrHgBmRspTypCstAvlFlg7 "ENM";
BA_ "SignalLongName" SG_ 1189 GlrFrHgBmRspTypCstAvlFlg7 "Glare Free High Beam Response Type Customization Availability Flag7";
BA_ "SignalType" SG_ 1189 LtRtHnTrCstAvlFlg1 "ENM";
BA_ "SignalLongName" SG_ 1189 LtRtHnTrCstAvlFlg1 "Left Right Hand Traffic Customization Availability Flag1";
BA_ "SignalType" SG_ 1189 LnChgAlrtCstAvlFlg7 "ENM";
BA_ "SignalLongName" SG_ 1189 LnChgAlrtCstAvlFlg7 "LaneChangeAlertCustomizationAvailabilityFlag7";
BA_ "SignalType" SG_ 1189 LnChgAlrtCstAvlFlg6 "ENM";
BA_ "SignalLongName" SG_ 1189 LnChgAlrtCstAvlFlg6 "LaneChangeAlertCustomizationAvailabilityFlag6";
BA_ "SignalType" SG_ 1189 LnChgAlrtCstAvlFlg5 "ENM";
BA_ "SignalLongName" SG_ 1189 LnChgAlrtCstAvlFlg5 "LaneChangeAlertCustomizationAvailabilityFlag5";
BA_ "SignalType" SG_ 1189 LnChgAlrtCstAvlFlg4 "ENM";
BA_ "SignalLongName" SG_ 1189 LnChgAlrtCstAvlFlg4 "LaneChangeAlertCustomizationAvailabilityFlag4";
BA_ "SignalType" SG_ 1189 LnChgAlrtCstAvlFlg3 "ENM";
BA_ "SignalLongName" SG_ 1189 LnChgAlrtCstAvlFlg3 "LaneChangeAlertCustomizationAvailabilityFlag3";
BA_ "SignalType" SG_ 1189 LnChgAlrtCstAvlFlg2 "ENM";
BA_ "SignalLongName" SG_ 1189 LnChgAlrtCstAvlFlg2 "LaneChangeAlertCustomizationAvailabilityFlag2";
BA_ "SignalType" SG_ 1189 LnChgAlrtCstAvlFlg1 "ENM";
BA_ "SignalLongName" SG_ 1189 LnChgAlrtCstAvlFlg1 "LaneChangeAlertCustomizationAvailabilityFlag1";
BA_ "SignalType" SG_ 1189 PrkAsstONOFFCstAvlFlg1 "ENM";
BA_ "SignalLongName" SG_ 1189 PrkAsstONOFFCstAvlFlg1 "ParkAssistOnOffCustomizationAvailabilityFlag1";
BA_ "SignalType" SG_ 1189 PTHiElecLdReqd "ENM";
BA_ "SignalLongName" SG_ 1189 PTHiElecLdReqd "Powertrain High Electrical Load Requested";
BA_ "SignalType" SG_ 1189 LtRtHnTrCstAvlFlg7 "ENM";
BA_ "SignalLongName" SG_ 1189 LtRtHnTrCstAvlFlg7 "Left Right Hand Traffic Customization Availability Flag7";
BA_ "SignalType" SG_ 1189 LtRtHnTrCstAvlFlg6 "ENM";
BA_ "SignalLongName" SG_ 1189 LtRtHnTrCstAvlFlg6 "Left Right Hand Traffic Customization Availability Flag6";
BA_ "SignalType" SG_ 1189 LtRtHnTrCstAvlFlg5 "ENM";
BA_ "SignalLongName" SG_ 1189 LtRtHnTrCstAvlFlg5 "Left Right Hand Traffic Customization Availability Flag5";
BA_ "SignalType" SG_ 1189 LtRtHnTrCstAvlFlg4 "ENM";
BA_ "SignalLongName" SG_ 1189 LtRtHnTrCstAvlFlg4 "Left Right Hand Traffic Customization Availability Flag4";
BA_ "SignalType" SG_ 1189 LtRtHnTrCstAvlFlg3 "ENM";
BA_ "SignalLongName" SG_ 1189 LtRtHnTrCstAvlFlg3 "Left Right Hand Traffic Customization Availability Flag3";
BA_ "SignalType" SG_ 1189 LtRtHnTrCstAvlFlg2 "ENM";
BA_ "SignalLongName" SG_ 1189 LtRtHnTrCstAvlFlg2 "Left Right Hand Traffic Customization Availability Flag2";
BA_ "SignalType" SG_ 1189 PrkAsstTrHtchPsntCstAvlFlg2 "ENM";
BA_ "SignalLongName" SG_ 1189 PrkAsstTrHtchPsntCstAvlFlg2 "ParkAssistTrailerHitchPresentCustomizationAvailabilityFlag2";
BA_ "SignalType" SG_ 1189 PrkAsstTrHtchPsntCstAvlFlg1 "ENM";
BA_ "SignalLongName" SG_ 1189 PrkAsstTrHtchPsntCstAvlFlg1 "ParkAssistTrailerHitchPresentCustomizationAvailabilityFlag1";
BA_ "SignalType" SG_ 1189 PrkAsstONOFFCstAvlFlg7 "ENM";
BA_ "SignalLongName" SG_ 1189 PrkAsstONOFFCstAvlFlg7 "ParkAssistOnOffCustomizationAvailabilityFlag7";
BA_ "SignalType" SG_ 1189 PrkAsstONOFFCstAvlFlg6 "ENM";
BA_ "SignalLongName" SG_ 1189 PrkAsstONOFFCstAvlFlg6 "ParkAssistOnOffCustomizationAvailabilityFlag6";
BA_ "SignalType" SG_ 1189 PrkAsstONOFFCstAvlFlg5 "ENM";
BA_ "SignalLongName" SG_ 1189 PrkAsstONOFFCstAvlFlg5 "ParkAssistOnOffCustomizationAvailabilityFlag5";
BA_ "SignalType" SG_ 1189 PrkAsstONOFFCstAvlFlg4 "ENM";
BA_ "SignalLongName" SG_ 1189 PrkAsstONOFFCstAvlFlg4 "ParkAssistOnOffCustomizationAvailabilityFlag4";
BA_ "SignalType" SG_ 1189 PrkAsstONOFFCstAvlFlg3 "ENM";
BA_ "SignalLongName" SG_ 1189 PrkAsstONOFFCstAvlFlg3 "ParkAssistOnOffCustomizationAvailabilityFlag3";
BA_ "SignalType" SG_ 1189 PrkAsstONOFFCstAvlFlg2 "ENM";
BA_ "SignalLongName" SG_ 1189 PrkAsstONOFFCstAvlFlg2 "ParkAssistOnOffCustomizationAvailabilityFlag2";
BA_ "SignalType" SG_ 1189 PFASndSeltnCstAvlFlg2 "ENM";
BA_ "SignalLongName" SG_ 1189 PFASndSeltnCstAvlFlg2 "Pedestrian Friendly Alert Sound Selection Customization Availability Flag 2";
BA_ "SignalType" SG_ 1189 PFASndSeltnCstAvlFlg1 "ENM";
BA_ "SignalLongName" SG_ 1189 PFASndSeltnCstAvlFlg1 "Pedestrian Friendly Alert Sound Selection Customization Availability Flag 1";
BA_ "SignalType" SG_ 1189 LgslDiagStdCndMet "ENM";
BA_ "SignalLongName" SG_ 1189 LgslDiagStdCndMet "Legislated Diagnostics Standard Conditions Met";
BA_ "SignalType" SG_ 1189 PrkAsstTrHtchPsntCstAvlFlg7 "ENM";
BA_ "SignalLongName" SG_ 1189 PrkAsstTrHtchPsntCstAvlFlg7 "ParkAssistTrailerHitchPresentCustomizationAvailabilityFlag7";
BA_ "SignalType" SG_ 1189 PrkAsstTrHtchPsntCstAvlFlg6 "ENM";
BA_ "SignalLongName" SG_ 1189 PrkAsstTrHtchPsntCstAvlFlg6 "ParkAssistTrailerHitchPresentCustomizationAvailabilityFlag6";
BA_ "SignalType" SG_ 1189 PrkAsstTrHtchPsntCstAvlFlg5 "ENM";
BA_ "SignalLongName" SG_ 1189 PrkAsstTrHtchPsntCstAvlFlg5 "ParkAssistTrailerHitchPresentCustomizationAvailabilityFlag5";
BA_ "SignalType" SG_ 1189 PrkAsstTrHtchPsntCstAvlFlg4 "ENM";
BA_ "SignalLongName" SG_ 1189 PrkAsstTrHtchPsntCstAvlFlg4 "ParkAssistTrailerHitchPresentCustomizationAvailabilityFlag4";
BA_ "SignalType" SG_ 1189 PrkAsstTrHtchPsntCstAvlFlg3 "ENM";
BA_ "SignalLongName" SG_ 1189 PrkAsstTrHtchPsntCstAvlFlg3 "ParkAssistTrailerHitchPresentCustomizationAvailabilityFlag3";
BA_ "SignalType" SG_ 1189 RnngBrdAutoDplyCstAvlFlg4 "ENM";
BA_ "SignalLongName" SG_ 1189 RnngBrdAutoDplyCstAvlFlg4 "Running Boards Automatic Deployment Customization Availability Flag 4";
BA_ "SignalType" SG_ 1189 RnngBrdAutoDplyCstAvlFlg3 "ENM";
BA_ "SignalLongName" SG_ 1189 RnngBrdAutoDplyCstAvlFlg3 "Running Boards Automatic Deployment Customization Availability Flag 3";
BA_ "SignalType" SG_ 1189 RnngBrdAutoDplyCstAvlFlg2 "ENM";
BA_ "SignalLongName" SG_ 1189 RnngBrdAutoDplyCstAvlFlg2 "Running Boards Automatic Deployment Customization Availability Flag 2";
BA_ "SignalType" SG_ 1189 RnngBrdAutoDplyCstAvlFlg1 "ENM";
BA_ "SignalLongName" SG_ 1189 RnngBrdAutoDplyCstAvlFlg1 "Running Boards Automatic Deployment Customization Availability Flag 1";
BA_ "SignalType" SG_ 1189 PFASndSeltnCstAvlFlg6 "ENM";
BA_ "SignalLongName" SG_ 1189 PFASndSeltnCstAvlFlg6 "Pedestrian Friendly Alert Sound Selection Customization Availability Flag 6";
BA_ "SignalType" SG_ 1189 PFASndSeltnCstAvlFlg5 "ENM";
BA_ "SignalLongName" SG_ 1189 PFASndSeltnCstAvlFlg5 "Pedestrian Friendly Alert Sound Selection Customization Availability Flag 5";
BA_ "SignalType" SG_ 1189 PFASndSeltnCstAvlFlg4 "ENM";
BA_ "SignalLongName" SG_ 1189 PFASndSeltnCstAvlFlg4 "Pedestrian Friendly Alert Sound Selection Customization Availability Flag 4";
BA_ "SignalType" SG_ 1189 PFASndSeltnCstAvlFlg3 "ENM";
BA_ "SignalLongName" SG_ 1189 PFASndSeltnCstAvlFlg3 "Pedestrian Friendly Alert Sound Selection Customization Availability Flag 3";
BA_ "SignalType" SG_ 1189 RnngBrdManDplyCstAvlFlg5 "ENM";
BA_ "SignalLongName" SG_ 1189 RnngBrdManDplyCstAvlFlg5 "Running Boards Manual Deployment Customization Availability Flag 5";
BA_ "SignalType" SG_ 1189 RnngBrdManDplyCstAvlFlg4 "ENM";
BA_ "SignalLongName" SG_ 1189 RnngBrdManDplyCstAvlFlg4 "Running Boards Manual Deployment Customization Availability Flag 4";
BA_ "SignalType" SG_ 1189 RnngBrdManDplyCstAvlFlg3 "ENM";
BA_ "SignalLongName" SG_ 1189 RnngBrdManDplyCstAvlFlg3 "Running Boards Manual Deployment Customization Availability Flag 3";
BA_ "SignalType" SG_ 1189 RnngBrdManDplyCstAvlFlg2 "ENM";
BA_ "SignalLongName" SG_ 1189 RnngBrdManDplyCstAvlFlg2 "Running Boards Manual Deployment Customization Availability Flag 2";
BA_ "SignalType" SG_ 1189 RnngBrdManDplyCstAvlFlg1 "ENM";
BA_ "SignalLongName" SG_ 1189 RnngBrdManDplyCstAvlFlg1 "Running Boards Manual Deployment Customization Availability Flag 1";
BA_ "SignalType" SG_ 1189 RnngBrdAutoDplyCstAvlFlg7 "ENM";
BA_ "SignalLongName" SG_ 1189 RnngBrdAutoDplyCstAvlFlg7 "Running Boards Automatic Deployment Customization Availability Flag 7";
BA_ "SignalType" SG_ 1189 RnngBrdAutoDplyCstAvlFlg6 "ENM";
BA_ "SignalLongName" SG_ 1189 RnngBrdAutoDplyCstAvlFlg6 "Running Boards Automatic Deployment Customization Availability Flag 6";
BA_ "SignalType" SG_ 1189 RnngBrdAutoDplyCstAvlFlg5 "ENM";
BA_ "SignalLongName" SG_ 1189 RnngBrdAutoDplyCstAvlFlg5 "Running Boards Automatic Deployment Customization Availability Flag 5";
BA_ "SignalType" SG_ 1189 RrCrsTrfcAlrtCstAvlFlg6 "ENM";
BA_ "SignalLongName" SG_ 1189 RrCrsTrfcAlrtCstAvlFlg6 "RearCrossTrafficAlertCustomizationAvailabilityFlag6";
BA_ "SignalType" SG_ 1189 RrCrsTrfcAlrtCstAvlFlg5 "ENM";
BA_ "SignalLongName" SG_ 1189 RrCrsTrfcAlrtCstAvlFlg5 "RearCrossTrafficAlertCustomizationAvailabilityFlag5";
BA_ "SignalType" SG_ 1189 RrCrsTrfcAlrtCstAvlFlg4 "ENM";
BA_ "SignalLongName" SG_ 1189 RrCrsTrfcAlrtCstAvlFlg4 "RearCrossTrafficAlertCustomizationAvailabilityFlag4";
BA_ "SignalType" SG_ 1189 RrCrsTrfcAlrtCstAvlFlg3 "ENM";
BA_ "SignalLongName" SG_ 1189 RrCrsTrfcAlrtCstAvlFlg3 "RearCrossTrafficAlertCustomizationAvailabilityFlag3";
BA_ "SignalType" SG_ 1189 RrCrsTrfcAlrtCstAvlFlg2 "ENM";
BA_ "SignalLongName" SG_ 1189 RrCrsTrfcAlrtCstAvlFlg2 "RearCrossTrafficAlertCustomizationAvailabilityFlag2";
BA_ "SignalType" SG_ 1189 RrCrsTrfcAlrtCstAvlFlg1 "ENM";
BA_ "SignalLongName" SG_ 1189 RrCrsTrfcAlrtCstAvlFlg1 "RearCrossTrafficAlertCustomizationAvailabilityFlag1";
BA_ "SignalType" SG_ 1189 RnngBrdManDplyCstAvlFlg7 "ENM";
BA_ "SignalLongName" SG_ 1189 RnngBrdManDplyCstAvlFlg7 "Running Boards Manual Deployment Customization Availability Flag 7";
BA_ "SignalType" SG_ 1189 RnngBrdManDplyCstAvlFlg6 "ENM";
BA_ "SignalLongName" SG_ 1189 RnngBrdManDplyCstAvlFlg6 "Running Boards Manual Deployment Customization Availability Flag 6";
BA_ "SignalLongName" SG_ 1190 TrnsOilRmnLf "Transmission Oil Remaining Life";
BA_ "SignalType" SG_ 1190 AutMemRclCstAvlFlg4 "ENM";
BA_ "SignalLongName" SG_ 1190 AutMemRclCstAvlFlg4 "AutoMemoryRecallCustomizationAvailabilityFlag4";
BA_ "SignalType" SG_ 1190 AutMemRclCstAvlFlg3 "ENM";
BA_ "SignalLongName" SG_ 1190 AutMemRclCstAvlFlg3 "AutoMemoryRecallCustomizationAvailabilityFlag3";
BA_ "SignalType" SG_ 1190 AutMemRclCstAvlFlg2 "ENM";
BA_ "SignalLongName" SG_ 1190 AutMemRclCstAvlFlg2 "AutoMemoryRecallCustomizationAvailabilityFlag2";
BA_ "SignalType" SG_ 1190 AutMemRclCstAvlFlg1 "ENM";
BA_ "SignalLongName" SG_ 1190 AutMemRclCstAvlFlg1 "AutoMemoryRecallCustomizationAvailabilityFlag1";
BA_ "SignalType" SG_ 1190 AdpLghtRspTypCstAvlFlg7 "ENM";
BA_ "SignalLongName" SG_ 1190 AdpLghtRspTypCstAvlFlg7 "Adaptive Lighting Response Type Customization Availability Flag7";
BA_ "SignalType" SG_ 1190 AdpLghtRspTypCstAvlFlg6 "ENM";
BA_ "SignalLongName" SG_ 1190 AdpLghtRspTypCstAvlFlg6 "Adaptive Lighting Response Type Customization Availability Flag6";
BA_ "SignalType" SG_ 1190 AdpLghtRspTypCstAvlFlg5 "ENM";
BA_ "SignalLongName" SG_ 1190 AdpLghtRspTypCstAvlFlg5 "Adaptive Lighting Response Type Customization Availability Flag5";
BA_ "SignalType" SG_ 1190 AdpLghtRspTypCstAvlFlg4 "ENM";
BA_ "SignalLongName" SG_ 1190 AdpLghtRspTypCstAvlFlg4 "Adaptive Lighting Response Type Customization Availability Flag4";
BA_ "SignalType" SG_ 1190 EsyExtCstAvlFlg4 "ENM";
BA_ "SignalLongName" SG_ 1190 EsyExtCstAvlFlg4 "EasyExitCustomizationAvailabilityFlag4";
BA_ "SignalType" SG_ 1190 EsyExtCstAvlFlg3 "ENM";
BA_ "SignalLongName" SG_ 1190 EsyExtCstAvlFlg3 "EasyExitCustomizationAvailabilityFlag3";
BA_ "SignalType" SG_ 1190 EsyExtCstAvlFlg2 "ENM";
BA_ "SignalLongName" SG_ 1190 EsyExtCstAvlFlg2 "EasyExitCustomizationAvailabilityFlag2";
BA_ "SignalType" SG_ 1190 EsyExtCstAvlFlg1 "ENM";
BA_ "SignalLongName" SG_ 1190 EsyExtCstAvlFlg1 "EasyExitCustomizationAvailabilityFlag1";
BA_ "SignalType" SG_ 1190 EngIdlAtv "ENM";
BA_ "SignalLongName" SG_ 1190 EngIdlAtv "Engine Idle Active";
BA_ "SignalType" SG_ 1190 AutMemRclCstAvlFlg7 "ENM";
BA_ "SignalLongName" SG_ 1190 AutMemRclCstAvlFlg7 "AutoMemoryRecallCustomizationAvailabilityFlag7";
BA_ "SignalType" SG_ 1190 AutMemRclCstAvlFlg6 "ENM";
BA_ "SignalLongName" SG_ 1190 AutMemRclCstAvlFlg6 "AutoMemoryRecallCustomizationAvailabilityFlag6";
BA_ "SignalType" SG_ 1190 AutMemRclCstAvlFlg5 "ENM";
BA_ "SignalLongName" SG_ 1190 AutMemRclCstAvlFlg5 "AutoMemoryRecallCustomizationAvailabilityFlag5";
BA_ "SignalType" SG_ 1190 FrntPCMRspTypCstAvlFlg4 "ENM";
BA_ "SignalLongName" SG_ 1190 FrntPCMRspTypCstAvlFlg4 "FrontPCMResponseTypeCustomizationAvailabilityFlag4";
BA_ "SignalType" SG_ 1190 FrntPCMRspTypCstAvlFlg3 "ENM";
BA_ "SignalLongName" SG_ 1190 FrntPCMRspTypCstAvlFlg3 "FrontPCMResponseTypeCustomizationAvailabilityFlag3";
BA_ "SignalType" SG_ 1190 FrntPCMRspTypCstAvlFlg2 "ENM";
BA_ "SignalLongName" SG_ 1190 FrntPCMRspTypCstAvlFlg2 "FrontPCMResponseTypeCustomizationAvailabilityFlag2";
BA_ "SignalType" SG_ 1190 FrntPCMRspTypCstAvlFlg1 "ENM";
BA_ "SignalLongName" SG_ 1190 FrntPCMRspTypCstAvlFlg1 "FrontPCMResponseTypeCustomizationAvailabilityFlag1";
BA_ "SignalType" SG_ 1190 FlToPsSwAtv "ENM";
BA_ "SignalLongName" SG_ 1190 FlToPsSwAtv "Flash To Pass Active";
BA_ "SignalType" SG_ 1190 EsyExtCstAvlFlg7 "ENM";
BA_ "SignalLongName" SG_ 1190 EsyExtCstAvlFlg7 "EasyExitCustomizationAvailabilityFlag7";
BA_ "SignalType" SG_ 1190 EsyExtCstAvlFlg6 "ENM";
BA_ "SignalLongName" SG_ 1190 EsyExtCstAvlFlg6 "EasyExitCustomizationAvailabilityFlag6";
BA_ "SignalType" SG_ 1190 EsyExtCstAvlFlg5 "ENM";
BA_ "SignalLongName" SG_ 1190 EsyExtCstAvlFlg5 "EasyExitCustomizationAvailabilityFlag5";
BA_ "SignalType" SG_ 1190 FrwdImpMtgnOpSlctCstAvlFlg5 "ENM";
BA_ "SignalLongName" SG_ 1190 FrwdImpMtgnOpSlctCstAvlFlg5 "ForwardImpactMitigationOperationSelectCustomizationAvailabilityFlag5";
BA_ "SignalType" SG_ 1190 FrwdImpMtgnOpSlctCstAvlFlg4 "ENM";
BA_ "SignalLongName" SG_ 1190 FrwdImpMtgnOpSlctCstAvlFlg4 "ForwardImpactMitigationOperationSelectCustomizationAvailabilityFlag4";
BA_ "SignalType" SG_ 1190 FrwdImpMtgnOpSlctCstAvlFlg3 "ENM";
BA_ "SignalLongName" SG_ 1190 FrwdImpMtgnOpSlctCstAvlFlg3 "ForwardImpactMitigationOperationSelectCustomizationAvailabilityFlag3";
BA_ "SignalType" SG_ 1190 FrwdImpMtgnOpSlctCstAvlFlg2 "ENM";
BA_ "SignalLongName" SG_ 1190 FrwdImpMtgnOpSlctCstAvlFlg2 "ForwardImpactMitigationOperationSelectCustomizationAvailabilityFlag2";
BA_ "SignalType" SG_ 1190 FrwdImpMtgnOpSlctCstAvlFlg1 "ENM";
BA_ "SignalLongName" SG_ 1190 FrwdImpMtgnOpSlctCstAvlFlg1 "Forward Impact Mitigation Operation SelectCustomizationAvailabilityFlag1";
BA_ "SignalType" SG_ 1190 FrntPCMRspTypCstAvlFlg7 "ENM";
BA_ "SignalLongName" SG_ 1190 FrntPCMRspTypCstAvlFlg7 "FrontPCMResponseTypeCustomizationAvailabilityFlag7";
BA_ "SignalType" SG_ 1190 FrntPCMRspTypCstAvlFlg6 "ENM";
BA_ "SignalLongName" SG_ 1190 FrntPCMRspTypCstAvlFlg6 "FrontPCMResponseTypeCustomizationAvailabilityFlag6";
BA_ "SignalType" SG_ 1190 FrntPCMRspTypCstAvlFlg5 "ENM";
BA_ "SignalLongName" SG_ 1190 FrntPCMRspTypCstAvlFlg5 "FrontPCMResponseTypeCustomizationAvailabilityFlag5";
BA_ "SignalType" SG_ 1190 GlrFrHgBmRspTypCstAvlFlg6 "ENM";
BA_ "SignalLongName" SG_ 1190 GlrFrHgBmRspTypCstAvlFlg6 "Glare Free High Beam Response Type Customization Availability Flag6";
BA_ "SignalType" SG_ 1190 GlrFrHgBmRspTypCstAvlFlg5 "ENM";
BA_ "SignalLongName" SG_ 1190 GlrFrHgBmRspTypCstAvlFlg5 "Glare Free High Beam Response Type Customization Availability Flag5";
BA_ "SignalType" SG_ 1190 GlrFrHgBmRspTypCstAvlFlg4 "ENM";
BA_ "SignalLongName" SG_ 1190 GlrFrHgBmRspTypCstAvlFlg4 "Glare Free High Beam Response Type Customization Availability Flag4";
BA_ "SignalType" SG_ 1190 GlrFrHgBmRspTypCstAvlFlg3 "ENM";
BA_ "SignalLongName" SG_ 1190 GlrFrHgBmRspTypCstAvlFlg3 "Glare Free High Beam Response Type Customization Availability Flag3";
BA_ "SignalType" SG_ 1190 GlrFrHgBmRspTypCstAvlFlg2 "ENM";
BA_ "SignalLongName" SG_ 1190 GlrFrHgBmRspTypCstAvlFlg2 "Glare Free High Beam Response Type Customization Availability Flag2";
BA_ "SignalType" SG_ 1190 GlrFrHgBmRspTypCstAvlFlg1 "ENM";
BA_ "SignalLongName" SG_ 1190 GlrFrHgBmRspTypCstAvlFlg1 "Glare Free High Beam Response Type Customization Availability Flag1";
BA_ "SignalType" SG_ 1190 FrwdImpMtgnOpSlctCstAvlFlg7 "ENM";
BA_ "SignalLongName" SG_ 1190 FrwdImpMtgnOpSlctCstAvlFlg7 "ForwardImpactMitigationOperationSelectCustomizationAvailabilityFlag7";
BA_ "SignalType" SG_ 1190 FrwdImpMtgnOpSlctCstAvlFlg6 "ENM";
BA_ "SignalLongName" SG_ 1190 FrwdImpMtgnOpSlctCstAvlFlg6 "ForwardImpactMitigationOperationSelectCustomizationAvailabilityFlag6";
BA_ "SignalLongName" SG_ 1191 BarPrsAbs "Barometric Pressure Absolute";
BA_ "SignalType" SG_ 1191 BarPrsAbs_Inv "ENM";
BA_ "SignalLongName" SG_ 1191 BarPrsAbs_Inv "Barometric Pressure Absolute Invalid";
BA_ "SignalLongName" SG_ 1191 BatVlt "Battery Voltage";
BA_ "SignalType" SG_ 1191 BatVlt_Inv "ENM";
BA_ "SignalLongName" SG_ 1191 BatVlt_Inv "RVC 12V Battery Voltage Invalid";
BA_ "SignalLongName" SG_ 1191 DslExhFldLvlPct "Diesel Exhaust Fluid Level Percent";
BA_ "SignalType" SG_ 1191 DslExhFldLvlPct_Inv "ENM";
BA_ "SignalLongName" SG_ 1191 DslExhFldLvlPct_Inv "Diesel Exhaust Fluid Level Percent Invalid";
BA_ "SignalLongName" SG_ 1191 EngOilTmp "Engine Oil Temperature";
BA_ "SignalType" SG_ 1191 EngOilTmp_Inv "ENM";
BA_ "SignalLongName" SG_ 1191 EngOilTmp_Inv "Engine Oil Temperature Invalid";
BA_ "SignalLongName" SG_ 1191 RVC12VBatSOC "RVC 12V Battery State of Charge";
BA_ "SignalType" SG_ 1191 RVC12VBatSOC_Inv "ENM";
BA_ "SignalLongName" SG_ 1191 RVC12VBatSOC_Inv "RVC 12V Battery Stateof Charge Invalidity";
BA_ "SignalLongName" SG_ 1191 EngCoolFanSpd "Engine Cooling Fan Speed";
BA_ "SignalType" SG_ 1191 SprTireSt "ENM";
BA_ "SignalLongName" SG_ 1191 SprTireSt "Spare Tire Status";
BA_ "SignalLongName" SG_ 1192 OATP_OtsAirTmpAuth "Outside Air Temperature Protected : Outside Air Temperature Authenticated";
BA_ "SignalLongName" SG_ 1192 OATP_OtsAirTmpCrValAuth "Outside Air Temperature Protected : Outside Air Temperature Corrected Value Authenticated";
BA_ "SignalLongName" SG_ 1192 HiVltgBatMaxTemp "High Voltage Battery Maximum Temperature";
BA_ "SignalType" SG_ 1192 HiVltgBatMaxTemp_Inv "ENM";
BA_ "SignalLongName" SG_ 1192 HiVltgBatMaxTemp_Inv "High Voltage Battery Maximum Temperature Invalid";
BA_ "SignalType" SG_ 1192 OATP_OtsAirTmpCrValAuth_Inv "ENM";
BA_ "SignalLongName" SG_ 1192 OATP_OtsAirTmpCrValAuth_Inv "Outside Air Temperature Protected : Outside Air Temperature Corrected Value Authenticated Invalid";
BA_ "SignalType" SG_ 1192 PwrRrClsrCstAvlFlg4 "ENM";
BA_ "SignalLongName" SG_ 1192 PwrRrClsrCstAvlFlg4 "Power Rear Closure Customization Availability Flag 4";
BA_ "SignalType" SG_ 1192 PwrRrClsrCstAvlFlg3 "ENM";
BA_ "SignalLongName" SG_ 1192 PwrRrClsrCstAvlFlg3 "Power Rear Closure Customization Availability Flag 3";
BA_ "SignalType" SG_ 1192 PwrRrClsrCstAvlFlg2 "ENM";
BA_ "SignalLongName" SG_ 1192 PwrRrClsrCstAvlFlg2 "Power Rear Closure Customization Availability Flag 2";
BA_ "SignalType" SG_ 1192 PwrRrClsrCstAvlFlg1 "ENM";
BA_ "SignalLongName" SG_ 1192 PwrRrClsrCstAvlFlg1 "Power Rear Closure Customization Availability Flag 1";
BA_ "SignalType" SG_ 1192 PFASndSeltnCstSetAval "ENM";
BA_ "SignalLongName" SG_ 1192 PFASndSeltnCstSetAval "Pedestrian Friendly Alert Sound Selection Customization Setting Available";
BA_ "SignalType" SG_ 1192 PFASndSeltnCstAvlFlg7 "ENM";
BA_ "SignalLongName" SG_ 1192 PFASndSeltnCstAvlFlg7 "Pedestrian Friendly Alert Sound Selection Customization Availability Flag 7";
BA_ "SignalLongName" SG_ 1192 WEPRP_WhlEdgesPerRevRrAuth "Wheel Edges Per Revolution Protected : Wheel Edges Per Revolution Rear Authenticated";
BA_ "SignalType" SG_ 1192 PwrRrClsrCstAvlFlg5 "ENM";
BA_ "SignalLongName" SG_ 1192 PwrRrClsrCstAvlFlg5 "Power Rear Closure Customization Availability Flag 5";
BA_ "SignalType" SG_ 1192 ACRfHiSdFldPrs_Inv "ENM";
BA_ "SignalLongName" SG_ 1192 ACRfHiSdFldPrs_Inv "Air Conditioning Refrigerant High Side Fluid Pressure Invalid";
BA_ "SignalLongName" SG_ 1192 WEPRP_WhlEdgesPerRevFrtAuth "Wheel Edges Per Revolution Protected : Wheel Edges Per Revolution Front Authenticated";
BA_ "SignalLongName" SG_ 1192 ACRfHiSdFldPrs "Air Conditioning Refrigerant High Side Fluid Pressure";
BA_ "SignalLongName" SG_ 1192 ACCmpNrmLdGrdAld "Air Conditioning Compressor Normalized Load Gradient Allowed";
BA_ "SignalLongName" SG_ 1193 TmSyncMsg "Time Sync Message";
BA_ "SignalLongName" SG_ 1193 WDP_WhlDistPerRevFrtAuth "Wheel Distance Protected : Wheel Distance Per Revolution Front Authenticated";
BA_ "SignalLongName" SG_ 1193 WDP_WhlDistPerRevRrAuth "Wheel Distance Protected : Wheel Distance Per Revolution Rear Authenticated";
BA_ "SignalType" SG_ 1193 AdpLghtRspTypCstAvlFlg3 "ENM";
BA_ "SignalLongName" SG_ 1193 AdpLghtRspTypCstAvlFlg3 "Adaptive Lighting Response Type Customization Availability Flag3";
BA_ "SignalType" SG_ 1193 AdpLghtRspTypCstAvlFlg2 "ENM";
BA_ "SignalLongName" SG_ 1193 AdpLghtRspTypCstAvlFlg2 "Adaptive Lighting Response Type Customization Availability Flag2";
BA_ "SignalType" SG_ 1193 AdpLghtRspTypCstAvlFlg1 "ENM";
BA_ "SignalLongName" SG_ 1193 AdpLghtRspTypCstAvlFlg1 "Adaptive Lighting Response Type Customization Availability Flag1";
BA_ "SignalType" SG_ 1193 ABSPr "ENM";
BA_ "SignalLongName" SG_ 1193 ABSPr "Antilock Brake System Present";
BA_ "SignalType" SG_ 1197 PMMiRAPStatus "ENM";
BA_ "SignalLongName" SG_ 1197 PMMiRAPStatus "Retained Accesory Power Signal Group : PMM iRAP Status";
BA_ "SignalType" SG_ 1197 RrPCMRspTypCstStAvl "ENM";
BA_ "SignalLongName" SG_ 1197 RrPCMRspTypCstStAvl "RearPCMResponseTypeCustomizationSettingAvailable";
BA_ "SignalType" SG_ 1197 RrPCMRspTypCstAvlFlg7 "ENM";
BA_ "SignalLongName" SG_ 1197 RrPCMRspTypCstAvlFlg7 "RearPCMResponseTypeCustomizationAvailabilityFlag7";
BA_ "SignalType" SG_ 1197 RrPCMRspTypCstAvlFlg6 "ENM";
BA_ "SignalLongName" SG_ 1197 RrPCMRspTypCstAvlFlg6 "RearPCMResponseTypeCustomizationAvailabilityFlag6";
BA_ "SignalType" SG_ 1197 RrPCMRspTypCstAvlFlg5 "ENM";
BA_ "SignalLongName" SG_ 1197 RrPCMRspTypCstAvlFlg5 "RearPCMResponseTypeCustomizationAvailabilityFlag5";
BA_ "SignalType" SG_ 1197 RrPCMRspTypCstAvlFlg4 "ENM";
BA_ "SignalLongName" SG_ 1197 RrPCMRspTypCstAvlFlg4 "RearPCMResponseTypeCustomizationAvailabilityFlag4";
BA_ "SignalType" SG_ 1197 RrPCMRspTypCstAvlFlg3 "ENM";
BA_ "SignalLongName" SG_ 1197 RrPCMRspTypCstAvlFlg3 "RearPCMResponseTypeCustomizationAvailabilityFlag3";
BA_ "SignalType" SG_ 1197 RrPCMRspTypCstAvlFlg2 "ENM";
BA_ "SignalLongName" SG_ 1197 RrPCMRspTypCstAvlFlg2 "RearPCMResponseTypeCustomizationAvailabilityFlag2";
BA_ "SignalType" SG_ 1197 RrPCMRspTypCstAvlFlg1 "ENM";
BA_ "SignalLongName" SG_ 1197 RrPCMRspTypCstAvlFlg1 "RearPCMResponseTypeCustomizationAvailabilityFlag1";
BA_ "SignalType" SG_ 1197 PAMutSts "ENM";
BA_ "SignalLongName" SG_ 1197 PAMutSts "Park Assist Mute Status";
BA_ "SignalType" SG_ 1197 LDWCtrlAudAttnReqd "ENM";
BA_ "SignalLongName" SG_ 1197 LDWCtrlAudAttnReqd "Lane Detection Warning and Control Audio Attenuation Requested";
BA_ "SignalType" SG_ 1197 LDWCtrlHndOff3ChmEvntStat "ENM";
BA_ "SignalLongName" SG_ 1197 LDWCtrlHndOff3ChmEvntStat "Lane Detection Warning and Control Hands Off 3 Chime Event State";
BA_ "SignalType" SG_ 1197 StBltRmndrChmTyp2EvntStat "ENM";
BA_ "SignalLongName" SG_ 1197 StBltRmndrChmTyp2EvntStat "Seat Belt Reminder Chime Type 2 Event State";
BA_ "SignalType" SG_ 1197 TrnLmpRtIO "ENM";
BA_ "SignalLongName" SG_ 1197 TrnLmpRtIO "Turn Lamp Right Indication On";
BA_ "SignalType" SG_ 1197 TrnLmpLftIO "ENM";
BA_ "SignalLongName" SG_ 1197 TrnLmpLftIO "Turn Lamp Left Indication On";
BA_ "SignalType" SG_ 1197 RetainedACCpwrStatus "ENM";
BA_ "SignalLongName" SG_ 1197 RetainedACCpwrStatus "Retained Accesory Power Signal Group : Retained Accessory Power Status";
BA_ "SignalType" SG_ 1198 PrkAsstRrLftSdZn1ChEvntSt "ENM";
BA_ "SignalLongName" SG_ 1198 PrkAsstRrLftSdZn1ChEvntSt "ParkAssistRearLeftSideZone1ChimeEventState";
BA_ "SignalType" SG_ 1198 PrkAsstRrFrstRprtChEvntSt "ENM";
BA_ "SignalLongName" SG_ 1198 PrkAsstRrFrstRprtChEvntSt "ParkAssistRearFirstReportChimeEventState";
BA_ "SignalType" SG_ 1198 PrkAsstFrRgrChEvntSt "ENM";
BA_ "SignalLongName" SG_ 1198 PrkAsstFrRgrChEvntSt "ParkAssistFrontRogerChimeEventState";
BA_ "SignalType" SG_ 1198 PrkAsstFrRghtSdZn6ChEvntSt "ENM";
BA_ "SignalLongName" SG_ 1198 PrkAsstFrRghtSdZn6ChEvntSt "ParkAssistFrontRightSideZone6ChimeEventState";
BA_ "SignalType" SG_ 1198 PrkAsstRrLftSdZn5ChEvntSt "ENM";
BA_ "SignalLongName" SG_ 1198 PrkAsstRrLftSdZn5ChEvntSt "ParkAssistRearLeftSideZone5ChimeEventState";
BA_ "SignalType" SG_ 1198 PrkAsstRrLftSdZn4ChEvntSt "ENM";
BA_ "SignalLongName" SG_ 1198 PrkAsstRrLftSdZn4ChEvntSt "ParkAssistRearLeftSideZone4ChimeEventState";
BA_ "SignalType" SG_ 1198 PrkAsstRrLftSdZn3ChEvntSt "ENM";
BA_ "SignalLongName" SG_ 1198 PrkAsstRrLftSdZn3ChEvntSt "ParkAssistRearLeftSideZone3ChimeEventState";
BA_ "SignalType" SG_ 1198 PrkAsstRrLftSdZn2ChEvntSt "ENM";
BA_ "SignalLongName" SG_ 1198 PrkAsstRrLftSdZn2ChEvntSt "ParkAssistRearLeftSideZone2ChimeEventState";
BA_ "SignalType" SG_ 1198 PrkAsstRrRghtSdZn3ChEvntSt "ENM";
BA_ "SignalLongName" SG_ 1198 PrkAsstRrRghtSdZn3ChEvntSt "ParkAssistRearRightSideZone3ChimeEventState";
BA_ "SignalType" SG_ 1198 PrkAsstRrRghtSdZn2ChEvntSt "ENM";
BA_ "SignalLongName" SG_ 1198 PrkAsstRrRghtSdZn2ChEvntSt "ParkAssistRearRightSideZone2ChimeEventState";
BA_ "SignalType" SG_ 1198 PrkAsstRrRghtSdZn1ChEvntSt "ENM";
BA_ "SignalLongName" SG_ 1198 PrkAsstRrRghtSdZn1ChEvntSt "ParkAssistRearRightSideZone1ChimeEventState";
BA_ "SignalType" SG_ 1198 PrkAsstRrLftSdZn6ChEvntSt "ENM";
BA_ "SignalLongName" SG_ 1198 PrkAsstRrLftSdZn6ChEvntSt "ParkAssistRearLeftSideZone6ChimeEventState";
BA_ "SignalType" SG_ 1198 PrkAsstRrRgrChEvntSt "ENM";
BA_ "SignalLongName" SG_ 1198 PrkAsstRrRgrChEvntSt "ParkAssistRearRogerChimeEventState";
BA_ "SignalType" SG_ 1198 PrkAsstRrRghtSdZn6ChEvntSt "ENM";
BA_ "SignalLongName" SG_ 1198 PrkAsstRrRghtSdZn6ChEvntSt "ParkAssistRearRightSideZone6ChimeEventState";
BA_ "SignalType" SG_ 1198 PrkAsstRrRghtSdZn5ChEvntSt "ENM";
BA_ "SignalLongName" SG_ 1198 PrkAsstRrRghtSdZn5ChEvntSt "ParkAssistRearRightSideZone5ChimeEventState";
BA_ "SignalType" SG_ 1198 PrkAsstRrRghtSdZn4ChEvntSt "ENM";
BA_ "SignalLongName" SG_ 1198 PrkAsstRrRghtSdZn4ChEvntSt "ParkAssistRearRightSideZone4ChimeEventState";
BA_ "SignalType" SG_ 1198 RrCrsTrfcAlrtLftIndCtrl "ENM";
BA_ "SignalLongName" SG_ 1198 RrCrsTrfcAlrtLftIndCtrl "Rear Cross Traffic Alert Left Indication Control";
BA_ "SignalType" SG_ 1198 RlOvrDsblStsChgChmEvntStat "ENM";
BA_ "SignalLongName" SG_ 1198 RlOvrDsblStsChgChmEvntStat "Rollover Disable Status Change Chime Event State";
BA_ "SignalType" SG_ 1198 RIMIntCllnChmEvStat "ENM";
BA_ "SignalLongName" SG_ 1198 RIMIntCllnChmEvStat "Rearward Impact Mitigation Initial Collision Chime Event State";
BA_ "SignalType" SG_ 1198 RIMBrkPlsChEvStat "ENM";
BA_ "SignalLongName" SG_ 1198 RIMBrkPlsChEvStat "Rearward Impact Mitigation Brake Pulse Chime Event State";
BA_ "SignalType" SG_ 1198 RrPCMChmEvntSt "ENM";
BA_ "SignalLongName" SG_ 1198 RrPCMChmEvntSt "Rear Pedestrian Collision Mitigation Chime Event State";
BA_ "SignalType" SG_ 1198 RrCrsTrfcAlrtRtSdChmEvntStat "ENM";
BA_ "SignalLongName" SG_ 1198 RrCrsTrfcAlrtRtSdChmEvntStat "Rear Cross Traffic Alert Right Side Chime Event State";
BA_ "SignalType" SG_ 1198 RrCrsTrfcAlrtRgIndCtrl "ENM";
BA_ "SignalLongName" SG_ 1198 RrCrsTrfcAlrtRgIndCtrl "Rear Cross Traffic Alert Right Indication Control";
BA_ "SignalType" SG_ 1198 RrCrsTrfcAlrtLtSdChmEvntStat "ENM";
BA_ "SignalLongName" SG_ 1198 RrCrsTrfcAlrtLtSdChmEvntStat "Rear Cross Traffic Alert Left Side Chime Event State";
BA_ "SignalType" SG_ 1198 DrHndlLRAuthReqd "ENM";
BA_ "SignalLongName" SG_ 1198 DrHndlLRAuthReqd "Door Handle Left Rear Authentication Requested";
BA_ "SignalType" SG_ 1198 DrHndlLFAuthReqd "ENM";
BA_ "SignalLongName" SG_ 1198 DrHndlLFAuthReqd "Door Handle Left Front Authentication Requested";
BA_ "SignalType" SG_ 1198 FrtPedtrnClsnMtgnAudAttnReqd "ENM";
BA_ "SignalLongName" SG_ 1198 FrtPedtrnClsnMtgnAudAttnReqd "Front Pedestrian Collision Mitigation Audio Attenuation Requested";
BA_ "SignalType" SG_ 1198 ACCGoNtfrChmEvntSt "ENM";
BA_ "SignalLongName" SG_ 1198 ACCGoNtfrChmEvntSt "Adaptive Cruise Control Go Notifier Chime Event State";
BA_ "SignalType" SG_ 1198 TrffcLgtAsstWrnChmEvntStat "ENM";
BA_ "SignalLongName" SG_ 1198 TrffcLgtAsstWrnChmEvntStat "Traffic Light Assist Warning Chime Event State";
BA_ "SignalType" SG_ 1198 StBltRmndrChmEvntStat "ENM";
BA_ "SignalLongName" SG_ 1198 StBltRmndrChmEvntStat "Seat Belt Reminder Chime Event State";
BA_ "SignalType" SG_ 1198 HVACUsrCtlIntrctnDispReqd "ENM";
BA_ "SignalLongName" SG_ 1198 HVACUsrCtlIntrctnDispReqd "HVAC User Controls Interaction Display Requested";
BA_ "SignalType" SG_ 1198 AirDflctrIndReq "ENM";
BA_ "SignalLongName" SG_ 1198 AirDflctrIndReq "Air Deflector Indication Request";
BA_ "SignalType" SG_ 1198 RrClsrRelAuthReqd "ENM";
BA_ "SignalLongName" SG_ 1198 RrClsrRelAuthReqd "Rear Closure Release Authentication Requested";
BA_ "SignalType" SG_ 1198 LnKpAsstTkStrIndOn "ENM";
BA_ "SignalLongName" SG_ 1198 LnKpAsstTkStrIndOn "Lane Keep Assist Take Steering Indication On";
BA_ "SignalType" SG_ 1198 FrtClsrRelAuthReqd "ENM";
BA_ "SignalLongName" SG_ 1198 FrtClsrRelAuthReqd "Front Closure Release Authentication Requested";
BA_ "SignalType" SG_ 1198 DrHndlRRAuthReqd "ENM";
BA_ "SignalLongName" SG_ 1198 DrHndlRRAuthReqd "Door Handle Right Rear Authentication Requested";
BA_ "SignalType" SG_ 1198 DrHndlRFAuthReqd "ENM";
BA_ "SignalLongName" SG_ 1198 DrHndlRFAuthReqd "Door Handle Right Front Authentication Requested";
BA_ "SignalType" SG_ 1199 MemStrTrplBeepChmEvStCoDrv "ENM";
BA_ "SignalLongName" SG_ 1199 MemStrTrplBeepChmEvStCoDrv "Memory Store Triple Beep Chime Event State Co-Driver";
BA_ "SignalType" SG_ 1199 MemStrSnglBeepChmEvStRR "ENM";
BA_ "SignalLongName" SG_ 1199 MemStrSnglBeepChmEvStRR "Memory Store Single Beep Chime Event State Right Rear";
BA_ "SignalType" SG_ 1199 MemStrSnglBeepChmEvStLR "ENM";
BA_ "SignalLongName" SG_ 1199 MemStrSnglBeepChmEvStLR "Memory Store Single Beep Chime Event State Left Rear";
BA_ "SignalType" SG_ 1199 MemStrSnglBeepChmEvStDrv "ENM";
BA_ "SignalLongName" SG_ 1199 MemStrSnglBeepChmEvStDrv "Memory Store Single Beep Chime Event State Driver";
BA_ "SignalType" SG_ 1199 PrkAsstFlChEvntSt "ENM";
BA_ "SignalLongName" SG_ 1199 PrkAsstFlChEvntSt "ParkAssistFailChimeEventState";
BA_ "SignalType" SG_ 1199 MemStrTrplBeepChmEvStRR "ENM";
BA_ "SignalLongName" SG_ 1199 MemStrTrplBeepChmEvStRR "Memory Store Triple Beep Chime Event State Right Rear";
BA_ "SignalType" SG_ 1199 MemStrTrplBeepChmEvStLR "ENM";
BA_ "SignalLongName" SG_ 1199 MemStrTrplBeepChmEvStLR "Memory Store Triple Beep Chime Event State Left Rear";
BA_ "SignalType" SG_ 1199 MemStrTrplBeepChmEvStDrv "ENM";
BA_ "SignalLongName" SG_ 1199 MemStrTrplBeepChmEvStDrv "Memory Store Triple Beep Chime Event State Driver";
BA_ "SignalType" SG_ 1199 PrkAsstFllFrZn4ChEvntSt "ENM";
BA_ "SignalLongName" SG_ 1199 PrkAsstFllFrZn4ChEvntSt "ParkAssistFullFrontZone4ChimeEventState";
BA_ "SignalType" SG_ 1199 PrkAsstFllFrZn3ChEvntSt "ENM";
BA_ "SignalLongName" SG_ 1199 PrkAsstFllFrZn3ChEvntSt "ParkAssistFullFrontZone3ChimeEventState";
BA_ "SignalType" SG_ 1199 PrkAsstFllFrZn2ChEvntSt "ENM";
BA_ "SignalLongName" SG_ 1199 PrkAsstFllFrZn2ChEvntSt "ParkAssistFullFrontZone2ChimeEventState";
BA_ "SignalType" SG_ 1199 PrkAsstFllFrZn1ChEvntSt "ENM";
BA_ "SignalLongName" SG_ 1199 PrkAsstFllFrZn1ChEvntSt "ParkAssistFullFrontZone1ChimeEventState";
BA_ "SignalType" SG_ 1199 PrkAsstFllRrZn2ChEvntSt "ENM";
BA_ "SignalLongName" SG_ 1199 PrkAsstFllRrZn2ChEvntSt "ParkAssistFullRearZone2ChimeEventState";
BA_ "SignalType" SG_ 1199 PrkAsstFllRrZn1ChEvntSt "ENM";
BA_ "SignalLongName" SG_ 1199 PrkAsstFllRrZn1ChEvntSt "ParkAssistFullRearZone1ChimeEventState";
BA_ "SignalType" SG_ 1199 PrkAsstFllFrZn6ChEvntSt "ENM";
BA_ "SignalLongName" SG_ 1199 PrkAsstFllFrZn6ChEvntSt "ParkAssistFullFrontZone6ChimeEventState";
BA_ "SignalType" SG_ 1199 PrkAsstFllFrZn5ChEvntSt "ENM";
BA_ "SignalLongName" SG_ 1199 PrkAsstFllFrZn5ChEvntSt "ParkAssistFullFrontZone5ChimeEventState";
BA_ "SignalType" SG_ 1199 PrkAsstFllRrZn6ChEvntSt "ENM";
BA_ "SignalLongName" SG_ 1199 PrkAsstFllRrZn6ChEvntSt "ParkAssistFullRearZone6ChimeEventState";
BA_ "SignalType" SG_ 1199 PrkAsstFllRrZn5ChEvntSt "ENM";
BA_ "SignalLongName" SG_ 1199 PrkAsstFllRrZn5ChEvntSt "ParkAssistFullRearZone5ChimeEventState";
BA_ "SignalType" SG_ 1199 PrkAsstFllRrZn4ChEvntSt "ENM";
BA_ "SignalLongName" SG_ 1199 PrkAsstFllRrZn4ChEvntSt "ParkAssistFullRearZone4ChimeEventState";
BA_ "SignalType" SG_ 1199 PrkAsstFllRrZn3ChEvntSt "ENM";
BA_ "SignalLongName" SG_ 1199 PrkAsstFllRrZn3ChEvntSt "ParkAssistFullRearZone3ChimeEventState";
BA_ "SignalType" SG_ 1199 PrkAsstFrLftSdZn3ChEvntSt "ENM";
BA_ "SignalLongName" SG_ 1199 PrkAsstFrLftSdZn3ChEvntSt "ParkAssistFrontLeftSideZone3ChimeEventState";
BA_ "SignalType" SG_ 1199 PrkAsstFrLftSdZn2ChEvntSt "ENM";
BA_ "SignalLongName" SG_ 1199 PrkAsstFrLftSdZn2ChEvntSt "ParkAssistFrontLeftSideZone2ChimeEventState";
BA_ "SignalType" SG_ 1199 PrkAsstFrLftSdZn1ChEvntSt "ENM";
BA_ "SignalLongName" SG_ 1199 PrkAsstFrLftSdZn1ChEvntSt "ParkAssistFrontLeftSideZone1ChimeEventState";
BA_ "SignalType" SG_ 1199 PrkAsstFrFrstRprtChEvntSt "ENM";
BA_ "SignalLongName" SG_ 1199 PrkAsstFrFrstRprtChEvntSt "ParkAssistFrontFirstReportChimeEventState";
BA_ "SignalType" SG_ 1199 PrkAsstFrRghtSdZn1ChEvntSt "ENM";
BA_ "SignalLongName" SG_ 1199 PrkAsstFrRghtSdZn1ChEvntSt "ParkAssistFrontRightSideZone1ChimeEventState";
BA_ "SignalType" SG_ 1199 PrkAsstFrLftSdZn6ChEvntSt "ENM";
BA_ "SignalLongName" SG_ 1199 PrkAsstFrLftSdZn6ChEvntSt "ParkAssistFrontLeftSideZone6ChimeEventState";
BA_ "SignalType" SG_ 1199 PrkAsstFrLftSdZn5ChEvntSt "ENM";
BA_ "SignalLongName" SG_ 1199 PrkAsstFrLftSdZn5ChEvntSt "ParkAssistFrontLeftSideZone5ChimeEventState";
BA_ "SignalType" SG_ 1199 PrkAsstFrLftSdZn4ChEvntSt "ENM";
BA_ "SignalLongName" SG_ 1199 PrkAsstFrLftSdZn4ChEvntSt "ParkAssistFrontLeftSideZone4ChimeEventState";
BA_ "SignalType" SG_ 1199 PrkAsstFrRghtSdZn5ChEvntSt "ENM";
BA_ "SignalLongName" SG_ 1199 PrkAsstFrRghtSdZn5ChEvntSt "ParkAssistFrontRightSideZone5ChimeEventState";
BA_ "SignalType" SG_ 1199 PrkAsstFrRghtSdZn4ChEvntSt "ENM";
BA_ "SignalLongName" SG_ 1199 PrkAsstFrRghtSdZn4ChEvntSt "ParkAssistFrontRightSideZone4ChimeEventState";
BA_ "SignalType" SG_ 1199 PrkAsstFrRghtSdZn3ChEvntSt "ENM";
BA_ "SignalLongName" SG_ 1199 PrkAsstFrRghtSdZn3ChEvntSt "ParkAssistFrontRightSideZone3ChimeEventState";
BA_ "SignalType" SG_ 1199 PrkAsstFrRghtSdZn2ChEvntSt "ENM";
BA_ "SignalLongName" SG_ 1199 PrkAsstFrRghtSdZn2ChEvntSt "ParkAssistFrontRightSideZone2ChimeEventState";
BA_ "SignalLongName" SG_ 1200 TrlrConnCntr "Trailer Connection Counter";
BA_ "SignalType" SG_ 1200 FrwdClsnAlrtImntAlrtAudAttnReqd "ENM";
BA_ "SignalLongName" SG_ 1200 FrwdClsnAlrtImntAlrtAudAttnReqd "Forward Collision Alert Imminent Alert Audio Attenuation Requested";
BA_ "SignalType" SG_ 1200 LKALnMrkgIndLt "ENM";
BA_ "SignalLongName" SG_ 1200 LKALnMrkgIndLt "Lane Keep Assist Lane Marking Indication Left";
BA_ "SignalType" SG_ 1200 LKALnMrkgIndRt "ENM";
BA_ "SignalLongName" SG_ 1200 LKALnMrkgIndRt "Lane Keep Assist Lane Marking Indication Right";
BA_ "SignalType" SG_ 1200 FrntPsSeatbeltStat "ENM";
BA_ "SignalLongName" SG_ 1200 FrntPsSeatbeltStat "Front Passenger Seat belt Status";
BA_ "SignalType" SG_ 1200 FrntPsSeatbeltStat_Inv "ENM";
BA_ "SignalLongName" SG_ 1200 FrntPsSeatbeltStat_Inv "Front Passenger Seat Belt Status Invalid";
BA_ "SignalType" SG_ 1200 EPBSP_ElecPrkBrkApplStsAuth "ENM";
BA_ "SignalLongName" SG_ 1200 EPBSP_ElecPrkBrkApplStsAuth "Electric Park Brake Status Protected : Electric Park Brake Application Status Authenticated";
BA_ "SignalType" SG_ 1200 RrPCMRspTypCstCrStVal "ENM";
BA_ "SignalLongName" SG_ 1200 RrPCMRspTypCstCrStVal "Rear PCM Response Type Customization Current Setting Value";
BA_ "SignalType" SG_ 1200 ORIP_DrvrStBltStsAuth_Inv "ENM";
BA_ "SignalLongName" SG_ 1200 ORIP_DrvrStBltStsAuth_Inv "Occupant Restraint Information Protected : Driver Seat Belt Status Authenticated Invalid";
BA_ "SignalType" SG_ 1200 ORIP_DrvrStBltStsAuth "ENM";
BA_ "SignalLongName" SG_ 1200 ORIP_DrvrStBltStsAuth "Occupant Restraint Information Protected : Driver Seat Belt Status Authenticated";
BA_ "SignalType" SG_ 1200 LnDtWrnCntrlVsAlrtCmdGnc "ENM";
BA_ "SignalLongName" SG_ 1200 LnDtWrnCntrlVsAlrtCmdGnc "Lane Detection Warning and Control Visual Alert Command Generic";
BA_ "SignalType" SG_ 1200 ElecPrkBrkCtnChiEveStat "ENM";
BA_ "SignalLongName" SG_ 1200 ElecPrkBrkCtnChiEveStat "Electric Park Brake Continuous Chime Event State";
BA_ "SignalType" SG_ 1200 LDWCtrlHndOff1ChmEvntStat "ENM";
BA_ "SignalLongName" SG_ 1200 LDWCtrlHndOff1ChmEvntStat "Lane Detection Warning and Control Hands Off 1 Chime Event State";
BA_ "SignalType" SG_ 1200 FrwdCllsnAlrtImAlrtDrIntAlrtChmE "ENM";
BA_ "SignalLongName" SG_ 1200 FrwdCllsnAlrtImAlrtDrIntAlrtChmE "Forward Collision Alert Imminent Alert Driver Intervention Alert Chime Event State";
BA_ "SignalType" SG_ 1200 FrntPCMChmEvntStat "ENM";
BA_ "SignalLongName" SG_ 1200 FrntPCMChmEvntStat "Front Pedestrian Collision Mitigation Chime Event State";
BA_ "SignalType" SG_ 1200 ElecPrkBrkFixDurChiEveStat "ENM";
BA_ "SignalLongName" SG_ 1200 ElecPrkBrkFixDurChiEveStat "Electric Park Brake Fixed Duration Chime Event State";
BA_ "SignalType" SG_ 1200 MemStrDblBeepChmEvStCoDrv "ENM";
BA_ "SignalLongName" SG_ 1200 MemStrDblBeepChmEvStCoDrv "Memory Store Double Beep Chime Event State Co-Driver";
BA_ "SignalType" SG_ 1200 LDWCtrlRtHndSdChmEvntStat "ENM";
BA_ "SignalLongName" SG_ 1200 LDWCtrlRtHndSdChmEvntStat "Lane Detection Warning and Control Right Hand Side Chime Event State";
BA_ "SignalType" SG_ 1200 LDWCtrlLtHndSdChmEvntStat "ENM";
BA_ "SignalLongName" SG_ 1200 LDWCtrlLtHndSdChmEvntStat "Lane Detection Warning and Control Left Hand Side Chime Event State";
BA_ "SignalType" SG_ 1200 LDWCtrlHndOff2ChmEvntStat "ENM";
BA_ "SignalLongName" SG_ 1200 LDWCtrlHndOff2ChmEvntStat "Lane Detection Warning and Control Hands Off 2 Chime Event State";
BA_ "SignalType" SG_ 1200 MemStrSnglBeepChmEvStCoDrv "ENM";
BA_ "SignalLongName" SG_ 1200 MemStrSnglBeepChmEvStCoDrv "Memory Store Single Beep Chime Event State Co-Driver";
BA_ "SignalType" SG_ 1200 MemStrDblBeepChmEvStRR "ENM";
BA_ "SignalLongName" SG_ 1200 MemStrDblBeepChmEvStRR "Memory Store Double Beep Chime Event State Right Rear";
BA_ "SignalType" SG_ 1200 MemStrDblBeepChmEvStLR "ENM";
BA_ "SignalLongName" SG_ 1200 MemStrDblBeepChmEvStLR "Memory Store Double Beep Chime Event State Left Rear";
BA_ "SignalType" SG_ 1200 MemStrDblBeepChmEvStDrv "ENM";
BA_ "SignalLongName" SG_ 1200 MemStrDblBeepChmEvStDrv "Memory Store Double Beep Chime Event State Driver";
BA_ "SignalType" SG_ 1201 ELWWIP_WprFrtFtrReqAuth "ENM";
BA_ "SignalLongName" SG_ 1201 ELWWIP_WprFrtFtrReqAuth "Exterior Lighting and Wash Wiper Information Protected : Wiper Front Feature Request Authenticated";
BA_ "SignalType" SG_ 1201 ELWWIP_RvrsLmpCmdAuth "ENM";
BA_ "SignalLongName" SG_ 1201 ELWWIP_RvrsLmpCmdAuth "Exterior Lighting and Wash Wiper Information Protected : Reverse Lamp Command Authenticated";
BA_ "SignalType" SG_ 1201 ELWWIP_TrlrRvrsLmpsCmdAuth "ENM";
BA_ "SignalLongName" SG_ 1201 ELWWIP_TrlrRvrsLmpsCmdAuth "Exterior Lighting and Wash Wiper Information Protected : Trailer Reverse Lamps Command Authenticated";
BA_ "SignalType" SG_ 1201 ELWWIP_CHMSLCmdAuth "ENM";
BA_ "SignalLongName" SG_ 1201 ELWWIP_CHMSLCmdAuth "Exterior Lighting and Wash Wiper Information Protected : CHMSL Command Authenticated";
BA_ "SignalType" SG_ 1201 ELWWIP_BrkLmpRtCmdAuth "ENM";
BA_ "SignalLongName" SG_ 1201 ELWWIP_BrkLmpRtCmdAuth "Exterior Lighting and Wash Wiper Information Protected : Brake Lamp Right Command Authenticated";
BA_ "SignalType" SG_ 1201 ELWWIP_BrkLmpLtCmdAuth "ENM";
BA_ "SignalLongName" SG_ 1201 ELWWIP_BrkLmpLtCmdAuth "Exterior Lighting and Wash Wiper Information Protected : Brake Lamp Left Command Authenticated";
BA_ "SignalType" SG_ 1201 APACR_FaildChmEvntStat "ENM";
BA_ "SignalLongName" SG_ 1201 APACR_FaildChmEvntStat "Advanced Park Assist Chime Requests : Advanced Park Assist Failed Chime Event State";
BA_ "SignalType" SG_ 1201 APACR_StopChmEvntStat "ENM";
BA_ "SignalLongName" SG_ 1201 APACR_StopChmEvntStat "Advanced Park Assist Chime Requests : Advanced Park Assist Stop Chime Event State";
BA_ "SignalType" SG_ 1201 APACR_CmpltChmEvntStat "ENM";
BA_ "SignalLongName" SG_ 1201 APACR_CmpltChmEvntStat "Advanced Park Assist Chime Requests : Advanced Park Assist Complete Chime Event State";
BA_ "SignalType" SG_ 1201 APACR_CncldChmEvntStat "ENM";
BA_ "SignalLongName" SG_ 1201 APACR_CncldChmEvntStat "Advanced Park Assist Chime Requests : Advanced Park Assist Canceled Chime Event State";
BA_ "SignalLongName" SG_ 1201 FCAIAHSR_HptcStReqPuls "Forward Collision Alert Imminent Haptic Seat Request : Haptic Seat Request Pulses";
BA_ "SignalType" SG_ 1201 APACR_SptFndChmEvntStat "ENM";
BA_ "SignalLongName" SG_ 1201 APACR_SptFndChmEvntStat "Advanced Park Assist Chime Requests : Advanced Park Assist Spot Found Chime Event State";
BA_ "SignalType" SG_ 1201 LnCntrWrnIndRqst "ENM";
BA_ "SignalLongName" SG_ 1201 LnCntrWrnIndRqst "Lane Centering Warning Indication Request";
BA_ "SignalType" SG_ 1201 UpftrRrAprchPrtctnChmEvntStat "ENM";
BA_ "SignalLongName" SG_ 1201 UpftrRrAprchPrtctnChmEvntStat "Upfitter Rear Approach Protection Chime Event State";
BA_ "SignalType" SG_ 1219 TrlLfTrInLtFld "ENM";
BA_ "SignalLongName" SG_ 1219 TrlLfTrInLtFld "Trailer Left Turn Indicator Light Failed";
BA_ "SignalType" SG_ 1219 TnDrvRIMOFFUnvIndOn "ENM";
BA_ "SignalLongName" SG_ 1219 TnDrvRIMOFFUnvIndOn "Teen Driver Rearward Impact Mitigation OFF Unavailable Indication On";
BA_ "SignalType" SG_ 1219 StNtLtchdIO "ENM";
BA_ "SignalLongName" SG_ 1219 StNtLtchdIO "Seat Not Latched Indication On";
BA_ "SignalType" SG_ 1219 SrvPedtrnProtSysIO "ENM";
BA_ "SignalLongName" SG_ 1219 SrvPedtrnProtSysIO "Service Pedestrian Protection System Indication On";
BA_ "SignalType" SG_ 1219 SftTpVltLwIO "ENM";
BA_ "SignalLongName" SG_ 1219 SftTpVltLwIO "Soft Top Voltage Low Indication On";
BA_ "SignalType" SG_ 1219 SftTpVehOvSpdIO "ENM";
BA_ "SignalLongName" SG_ 1219 SftTpVehOvSpdIO "Soft Top Vehicle Overspeed Indication On";
BA_ "SignalType" SG_ 1219 SftTpTmpLwIO "ENM";
BA_ "SignalLongName" SG_ 1219 SftTpTmpLwIO "Soft Top Temperature Low Indication On";
BA_ "SignalType" SG_ 1219 SftTpStrIO "ENM";
BA_ "SignalLongName" SG_ 1219 SftTpStrIO "Soft Top Storage Indication On";
BA_ "SignalType" SG_ 1219 TrlrTlLtFld "ENM";
BA_ "SignalLongName" SG_ 1219 TrlrTlLtFld "Trailer Tail Light Failed";
BA_ "SignalType" SG_ 1219 RrVirtBmpAutoBrkRelIndOn "ENM";
BA_ "SignalLongName" SG_ 1219 RrVirtBmpAutoBrkRelIndOn "Rear Virtual Bumper Autonomous Brake Release Indication On";
BA_ "SignalType" SG_ 1219 TrlrRvrsLmpOtgIndOn "ENM";
BA_ "SignalLongName" SG_ 1219 TrlrRvrsLmpOtgIndOn "Trailer Reverse Lamp Outage Indication On";
BA_ "SignalType" SG_ 1219 TrlrRtTrInLtFld "ENM";
BA_ "SignalLongName" SG_ 1219 TrlrRtTrInLtFld "Trailer Right Turn Indicator Light Failed";
BA_ "SignalType" SG_ 1219 TrlrFgLtFld "ENM";
BA_ "SignalLongName" SG_ 1219 TrlrFgLtFld "Trailer Fog Light Failed";
BA_ "SignalType" SG_ 1219 TrlrDisconndIndOn "ENM";
BA_ "SignalLongName" SG_ 1219 TrlrDisconndIndOn "Trailer Disconnected Indication On";
BA_ "SignalType" SG_ 1219 TrlrBrkLtFld "ENM";
BA_ "SignalLongName" SG_ 1219 TrlrBrkLtFld "Trailer Brake Light Failed";
BA_ "SignalType" SG_ 1219 TrnsNEmsRltMlfActv "ENM";
BA_ "SignalLongName" SG_ 1219 TrnsNEmsRltMlfActv "Transmission Non Emissions Related Malfunction Active";
BA_ "SignalType" SG_ 1219 TrnsEmsRltMlfAtv "ENM";
BA_ "SignalLongName" SG_ 1219 TrnsEmsRltMlfAtv "Transmission Emissions Related Malfunction Active";
BA_ "SignalType" SG_ 1219 DM2Denied "ENM";
BA_ "SignalLongName" SG_ 1219 DM2Denied "Drive Mode 2 Denied";
BA_ "SignalType" SG_ 1219 TrnLmpRrRtOtgIndOn "ENM";
BA_ "SignalLongName" SG_ 1219 TrnLmpRrRtOtgIndOn "Turn Lamp Rear Right Outage Indication On";
BA_ "SignalType" SG_ 1219 TrnLmpRrLtOtgIndOn "ENM";
BA_ "SignalLongName" SG_ 1219 TrnLmpRrLtOtgIndOn "Turn Lamp Rear Left Outage Indication On";
BA_ "SignalType" SG_ 1219 DM1Denied "ENM";
BA_ "SignalLongName" SG_ 1219 DM1Denied "Drive Mode 1 Denied";
BA_ "SignalType" SG_ 1219 TrnLmpFrtRtOtgIndOn "ENM";
BA_ "SignalLongName" SG_ 1219 TrnLmpFrtRtOtgIndOn "Turn Lamp Front Right Outage Indication On";
BA_ "SignalType" SG_ 1219 TrnLmpFrtLtOtgIndOn "ENM";
BA_ "SignalLongName" SG_ 1219 TrnLmpFrtLtOtgIndOn "Turn Lamp Front Left Outage Indication On";
BA_ "SignalType" SG_ 1219 RdHgtStatIndReq "ENM";
BA_ "SignalLongName" SG_ 1219 RdHgtStatIndReq "Ride Height State Indication Request";
BA_ "SignalType" SG_ 1219 SftTpFlrIO "ENM";
BA_ "SignalLongName" SG_ 1219 SftTpFlrIO "Soft Top Failure Indication On";
BA_ "SignalType" SG_ 1219 ACCSysSlctdMd "ENM";
BA_ "SignalLongName" SG_ 1219 ACCSysSlctdMd "Adaptive Cruise Control System Selected Mode";
BA_ "SignalType" SG_ 1219 BkupPwrMdStrtStpIgntSwtchPrsdRpt "ENM";
BA_ "SignalLongName" SG_ 1219 BkupPwrMdStrtStpIgntSwtchPrsdRpt "BPMM Start/Stop Ignition Switch Pressed Report";
BA_ "SignalType" SG_ 1219 VltSwAtvIO "ENM";
BA_ "SignalLongName" SG_ 1219 VltSwAtvIO "Valet Switch Active Indication On";
BA_ "SignalType" SG_ 1219 ValetModeActive "ENM";
BA_ "SignalLongName" SG_ 1219 ValetModeActive "Valet Mode Active";
BA_ "SignalType" SG_ 1219 TrnsOilChngIO "ENM";
BA_ "SignalLongName" SG_ 1219 TrnsOilChngIO "Transmission Oil Change Indication On";
BA_ "SignalLongName" SG_ 1219 HillDscntCtlTgtSetSpd "Hill Descent Control Target Set Speed";
BA_ "SignalType" SG_ 1219 RdHgtWrn2IndReq "ENM";
BA_ "SignalLongName" SG_ 1219 RdHgtWrn2IndReq "Ride Height Warning 2 Indication Request";
BA_ "SignalType" SG_ 1219 LnchCtlWhlSlSts "ENM";
BA_ "SignalLongName" SG_ 1219 LnchCtlWhlSlSts "Launch Control Wheel Slip Status";
BA_ "SignalType" SG_ 1219 LnchCtlEngRPMSts "ENM";
BA_ "SignalLongName" SG_ 1219 LnchCtlEngRPMSts "Launch Control Engine RPM Status";
BA_ "SignalLongName" SG_ 1219 LnchCtlBrkPresVal "Launch Control Brake Pressure Value";
BA_ "SignalType" SG_ 1220 LogisticModeStatus "ENM";
BA_ "SignalLongName" SG_ 1220 LogisticModeStatus "Logistic Mode Status";
BA_ "SignalType" SG_ 1220 LnCntrEsclnSts "ENM";
BA_ "SignalLongName" SG_ 1220 LnCntrEsclnSts "Lane Centering Escalation Status";
BA_ "SignalType" SG_ 1220 InvsblTrlrOprtlSts "ENM";
BA_ "SignalLongName" SG_ 1220 InvsblTrlrOprtlSts "Invisible Trailer Operational Status";
BA_ "SignalType" SG_ 1220 GlrFrHiBmSts "ENM";
BA_ "SignalLongName" SG_ 1220 GlrFrHiBmSts "Glare Free High Beam Status";
BA_ "SignalType" SG_ 1220 CkBrkLmpsIndOn "ENM";
BA_ "SignalLongName" SG_ 1220 CkBrkLmpsIndOn "Check Brake Lamps Indication On";
BA_ "SignalType" SG_ 1220 CIBAutoBrkRelIndOn "ENM";
BA_ "SignalLongName" SG_ 1220 CIBAutoBrkRelIndOn "Collision Imminent Braking Autonomous Brake Release Indication On";
BA_ "SignalType" SG_ 1220 BrkLtsAtv "ENM";
BA_ "SignalLongName" SG_ 1220 BrkLtsAtv "Brake Lights Active";
BA_ "SignalType" SG_ 1220 AutoHgBmCtrlIO "ENM";
BA_ "SignalLongName" SG_ 1220 AutoHgBmCtrlIO "Auto High Beam Control Indication On";
BA_ "SignalType" SG_ 1220 PAVisObjIndStatReq "ENM";
BA_ "SignalLongName" SG_ 1220 PAVisObjIndStatReq "Park Assist Visual Object Indication State Request";
BA_ "SignalType" SG_ 1220 ClsTrnkLidIO "ENM";
BA_ "SignalLongName" SG_ 1220 ClsTrnkLidIO "Close Trunk Lid Indication On";
BA_ "SignalType" SG_ 1220 CkSoftTpIO "ENM";
BA_ "SignalLongName" SG_ 1220 CkSoftTpIO "Check Soft Top Indication On";
BA_ "SignalType" SG_ 1220 CkRrPrkLmpIndOn "ENM";
BA_ "SignalLongName" SG_ 1220 CkRrPrkLmpIndOn "Check Rear Park Lamp Indication On";
BA_ "SignalType" SG_ 1220 CkLoBmsIndOn "ENM";
BA_ "SignalLongName" SG_ 1220 CkLoBmsIndOn "Check Low Beams Indication On";
BA_ "SignalType" SG_ 1220 CkFrtPrkLmpsIndOn "ENM";
BA_ "SignalLongName" SG_ 1220 CkFrtPrkLmpsIndOn "Check Front Park Lamps Indication On";
BA_ "SignalType" SG_ 1220 CkFgLmpsIndOn "ENM";
BA_ "SignalLongName" SG_ 1220 CkFgLmpsIndOn "Check Fog Lamps Indication On";
BA_ "SignalType" SG_ 1220 CkDyTmRnngLmpsIndOn "ENM";
BA_ "SignalLongName" SG_ 1220 CkDyTmRnngLmpsIndOn "Check Daytime Running Lamps Indication On";
BA_ "SignalType" SG_ 1220 CkCrnrLmpsIndOn "ENM";
BA_ "SignalLongName" SG_ 1220 CkCrnrLmpsIndOn "Check Cornering Lamps Indication On";
BA_ "SignalType" SG_ 1220 FrntPsMtzdStBltFldIndOn "ENM";
BA_ "SignalLongName" SG_ 1220 FrntPsMtzdStBltFldIndOn "Front Passenger Motorized Seat Belt Failed Indication On";
BA_ "SignalType" SG_ 1220 ESCLTrntheStrWheelWhlStrtgIO "ENM";
BA_ "SignalLongName" SG_ 1220 ESCLTrntheStrWheelWhlStrtgIO "Electric Steering Column Lock Turn the Steering Wheel While Starting Indication On";
BA_ "SignalType" SG_ 1220 DrvStBltRmIndOn "ENM";
BA_ "SignalLongName" SG_ 1220 DrvStBltRmIndOn "Driver Seat Belt Reminder Indication On";
BA_ "SignalType" SG_ 1220 DrvShftCntrlReqDndIO "ENM";
BA_ "SignalLongName" SG_ 1220 DrvShftCntrlReqDndIO "Driver Shift Control Request Denied Indication On";
BA_ "SignalType" SG_ 1220 DrMtzdStBltUnIndOn "ENM";
BA_ "SignalLongName" SG_ 1220 DrMtzdStBltUnIndOn "Driver Motorized Seat Belt Unavailable Indication On";
BA_ "SignalType" SG_ 1220 DrMtzdStBltFldIndOn "ENM";
BA_ "SignalLongName" SG_ 1220 DrMtzdStBltFldIndOn "Driver Motorized Seat Belt Failed Indication On";
BA_ "SignalType" SG_ 1220 DRLAct "ENM";
BA_ "SignalLongName" SG_ 1220 DRLAct "DRL Active";
BA_ "SignalType" SG_ 1220 CrsCntAtv "ENM";
BA_ "SignalLongName" SG_ 1220 CrsCntAtv "Cruise Control Active";
BA_ "SignalType" SG_ 1220 LicLpOtIO "ENM";
BA_ "SignalLongName" SG_ 1220 LicLpOtIO "License Lamp Outage Indication On";
BA_ "SignalType" SG_ 1220 LSCMBAutoBrkRlsIndOn "ENM";
BA_ "SignalLongName" SG_ 1220 LSCMBAutoBrkRlsIndOn "LSCMB Autonomous Brake Release Indication On";
BA_ "SignalType" SG_ 1220 HiBmOtgIndOn "ENM";
BA_ "SignalLongName" SG_ 1220 HiBmOtgIndOn "High Beam Outage Indication On";
BA_ "SignalType" SG_ 1220 GrdBrkgAct "ENM";
BA_ "SignalLongName" SG_ 1220 GrdBrkgAct "Grade Braking Active";
BA_ "SignalType" SG_ 1220 FrwdVhHdwyAlrtIndOn "ENM";
BA_ "SignalLongName" SG_ 1220 FrwdVhHdwyAlrtIndOn "Forward Vehicle Headway Alert Indication On";
BA_ "SignalType" SG_ 1220 EngFuelInjnSysFltIndOn "ENM";
BA_ "SignalLongName" SG_ 1220 EngFuelInjnSysFltIndOn "Engine Fuel Injection System Fault Indication On";
BA_ "SignalType" SG_ 1220 FrntPsStbltRmIndOn "ENM";
BA_ "SignalLongName" SG_ 1220 FrntPsStbltRmIndOn "Front Passenger Seat Belt Reminder Indication On";
BA_ "SignalType" SG_ 1220 FrntPsMtzdStBltUnIndOn "ENM";
BA_ "SignalLongName" SG_ 1220 FrntPsMtzdStBltUnIndOn "Front Passenger Motorized Seat Belt Unavailable Indication On";
BA_ "SignalType" SG_ 1220 RIMOFFIndOn "ENM";
BA_ "SignalLongName" SG_ 1220 RIMOFFIndOn "Rearward Impact Mitigation OFF Indication On";
BA_ "SignalType" SG_ 1220 PrkBrkSwAtv "ENM";
BA_ "SignalLongName" SG_ 1220 PrkBrkSwAtv "Park Brake Switch Active";
BA_ "SignalType" SG_ 1220 PedtrnProtSysDpl "ENM";
BA_ "SignalLongName" SG_ 1220 PedtrnProtSysDpl "Pedestrian Protection System Deployed";
BA_ "SignalType" SG_ 1220 NoSDCrdPrIndOn "ENM";
BA_ "SignalLongName" SG_ 1220 NoSDCrdPrIndOn "No SD Card Present Indication On";
BA_ "SignalType" SG_ 1220 MovblTpServRqrdIO "ENM";
BA_ "SignalLongName" SG_ 1220 MovblTpServRqrdIO "Moveable Top Service Required Indication On";
BA_ "SignalType" SG_ 1220 MovblTpNormzRqrdIO "ENM";
BA_ "SignalLongName" SG_ 1220 MovblTpNormzRqrdIO "Moveable Top Normalization Required Indication On";
BA_ "SignalType" SG_ 1220 LnCntrMisuseCond "ENM";
BA_ "SignalLongName" SG_ 1220 LnCntrMisuseCond "Lane Centering Misuse Condition";
BA_ "SignalType" SG_ 1220 LnCntrDrvAwrIndOn "ENM";
BA_ "SignalLongName" SG_ 1220 LnCntrDrvAwrIndOn "Lane Centering Driver Awareness Indication On";
BA_ "SignalType" SG_ 1220 RvLpOtIO "ENM";
BA_ "SignalLongName" SG_ 1220 RvLpOtIO "Reverse Lamp Outage Indication On";
BA_ "SignalType" SG_ 1220 RstrntDplyIndOn "ENM";
BA_ "SignalLongName" SG_ 1220 RstrntDplyIndOn "Restraint Deployment Indication On";
BA_ "SignalType" SG_ 1220 RrFgLpOtIO "ENM";
BA_ "SignalLongName" SG_ 1220 RrFgLpOtIO "Rear Fog Lamp Outage Indication On";
BA_ "SignalType" SG_ 1220 RrCrsTrfcAlrtOffIndOn "ENM";
BA_ "SignalLongName" SG_ 1220 RrCrsTrfcAlrtOffIndOn "Rear Cross Traffic Alert System Off Indication On";
BA_ "SignalType" SG_ 1220 BrkOvrhtdIndOn "ENM";
BA_ "SignalLongName" SG_ 1220 BrkOvrhtdIndOn "Brakes Overheated Indication On";
BA_ "SignalType" SG_ 1220 RearPsStbltVisIndMd "ENM";
BA_ "SignalLongName" SG_ 1220 RearPsStbltVisIndMd "Rear Passenger Seatbelt Reminder Visual Indication Mode";
BA_ "SignalType" SG_ 1220 RIMUnIndOn "ENM";
BA_ "SignalLongName" SG_ 1220 RIMUnIndOn "Rearward Impact Mitigation Unavailable Indication On";
BA_ "SignalType" SG_ 1220 RIMONIndOn "ENM";
BA_ "SignalLongName" SG_ 1220 RIMONIndOn "Rearward Impact Mitigation ON Indication On";
BA_ "SignalType" SG_ 1220 SftTpPlsDnWrngIO "ENM";
BA_ "SignalLongName" SG_ 1220 SftTpPlsDnWrngIO "Soft Top Pulse Down Warning Indication On";
BA_ "SignalType" SG_ 1220 SftTpPlsDnSrtdIO "ENM";
BA_ "SignalLongName" SG_ 1220 SftTpPlsDnSrtdIO "Soft Top Pulse Down Started Indication On";
BA_ "SignalType" SG_ 1220 SftTpMchnOvhtIO "ENM";
BA_ "SignalLongName" SG_ 1220 SftTpMchnOvhtIO "Soft Top Mechanism Overheated Indication On";
BA_ "SignalType" SG_ 1220 SftTpLtcIO "ENM";
BA_ "SignalLongName" SG_ 1220 SftTpLtcIO "Soft Top Latch Indication On";
BA_ "SignalType" SG_ 1220 ServHdlmpsIndOn "ENM";
BA_ "SignalLongName" SG_ 1220 ServHdlmpsIndOn "Service Headlamps Indication On";
BA_ "SignalType" SG_ 1220 SerRideSysIO "ENM";
BA_ "SignalLongName" SG_ 1220 SerRideSysIO "Service Ride System Indication On";
BA_ "SignalType" SG_ 1220 SDCrdFllIndOn "ENM";
BA_ "SignalLongName" SG_ 1220 SDCrdFllIndOn "SD Card Full Indication On";
BA_ "SignalType" SG_ 1220 SDCrdErrIndOn "ENM";
BA_ "SignalLongName" SG_ 1220 SDCrdErrIndOn "SD Card Error Indication On";
BA_ "SignalType" SG_ 1221 LnchCtlModeSts "ENM";
BA_ "SignalLongName" SG_ 1221 LnchCtlModeSts "Launch Control Mode Status";
BA_ "SignalType" SG_ 1221 RdHgtMvmtIndReq "ENM";
BA_ "SignalLongName" SG_ 1221 RdHgtMvmtIndReq "Ride Height Movement Indication Request";
BA_ "SignalType" SG_ 1221 RdHgtAtLocIndReq "ENM";
BA_ "SignalLongName" SG_ 1221 RdHgtAtLocIndReq "Ride Height Auto Location Indication Request";
BA_ "SignalType" SG_ 1221 TrlrMirVidEnblCstCurrSetVal "ENM";
BA_ "SignalLongName" SG_ 1221 TrlrMirVidEnblCstCurrSetVal "Trailering Mirror Video Enable CustomizationCurrent Setting Value";
BA_ "SignalType" SG_ 1221 PARgn "ENM";
BA_ "SignalLongName" SG_ 1221 PARgn "Park Assist Region";
BA_ "SignalType" SG_ 1221 RdHgtWrn1IndReq "ENM";
BA_ "SignalLongName" SG_ 1221 RdHgtWrn1IndReq "Ride Height Warning 1 Indication Request";
BA_ "SignalType" SG_ 1221 WndPstnStsLF "ENM";
BA_ "SignalLongName" SG_ 1221 WndPstnStsLF "Window Position Status Left Front";
BA_ "SignalType" SG_ 1221 TrnsSftMdSt "ENM";
BA_ "SignalLongName" SG_ 1221 TrnsSftMdSt "Transmission Shift Mode State";
BA_ "SignalType" SG_ 1221 WndPstnStsRR "ENM";
BA_ "SignalLongName" SG_ 1221 WndPstnStsRR "Window Position Status Right Rear";
BA_ "SignalType" SG_ 1221 WndPstnStsRF "ENM";
BA_ "SignalLongName" SG_ 1221 WndPstnStsRF "Window Position Status Right Front";
BA_ "SignalType" SG_ 1221 WndPstnStsLR "ENM";
BA_ "SignalLongName" SG_ 1221 WndPstnStsLR "Window Position Status Left Rear";
BA_ "SignalType" SG_ 1221 CltTpTrvAchv_Inv "ENM";
BA_ "SignalLongName" SG_ 1221 CltTpTrvAchv_Inv "Clutch Top of Travel Achieved Invalid";
BA_ "SignalType" SG_ 1221 BrkPadLifeFrtDistWrnIndReq "ENM";
BA_ "SignalLongName" SG_ 1221 BrkPadLifeFrtDistWrnIndReq "Brake Pad Life Front Distance Warning Indication Request";
BA_ "SignalType" SG_ 1221 AdvdFrtLgtSysIndReq "ENM";
BA_ "SignalLongName" SG_ 1221 AdvdFrtLgtSysIndReq "Advanced Front Lighting System Indication Request";
BA_ "SignalType" SG_ 1221 ACCAutoStSpStat "ENM";
BA_ "SignalLongName" SG_ 1221 ACCAutoStSpStat "Adaptive Cruise Control Auto Set Speed Status";
BA_ "SignalType" SG_ 1221 CmdThrdRwCtStbtVisInd "ENM";
BA_ "SignalLongName" SG_ 1221 CmdThrdRwCtStbtVisInd "Command Rear Passenger Third Row Center Seat Belt Visual Indication";
BA_ "SignalType" SG_ 1221 CmdSndRwRtStbtVisInd "ENM";
BA_ "SignalLongName" SG_ 1221 CmdSndRwRtStbtVisInd "Command Rear Passenger Second Row Right Seat Belt Visual Indication";
BA_ "SignalType" SG_ 1221 CmdSndRwLtStbtVisInd "ENM";
BA_ "SignalLongName" SG_ 1221 CmdSndRwLtStbtVisInd "Command Rear Passenger Second Row Left Seat Belt Visual Indication";
BA_ "SignalType" SG_ 1221 CmdSndRwCtStbtVisInd "ENM";
BA_ "SignalLongName" SG_ 1221 CmdSndRwCtStbtVisInd "Command Rear Passenger Second Row Center Seat Belt Visual Indication";
BA_ "SignalType" SG_ 1221 CltTpTrvAchv "ENM";
BA_ "SignalLongName" SG_ 1221 CltTpTrvAchv "Clutch Top of Travel Achieved";
BA_ "SignalType" SG_ 1221 DrLckStsLR "ENM";
BA_ "SignalLongName" SG_ 1221 DrLckStsLR "Door Lock Status Left Rear";
BA_ "SignalType" SG_ 1221 DrLckStsLF "ENM";
BA_ "SignalLongName" SG_ 1221 DrLckStsLF "Door Lock Status Left Front";
BA_ "SignalType" SG_ 1221 CmdThrdRwRtStbtVisInd "ENM";
BA_ "SignalLongName" SG_ 1221 CmdThrdRwRtStbtVisInd "Command Rear Passenger Third Row Right Seat Belt Visual Indication";
BA_ "SignalType" SG_ 1221 CmdThrdRwLtStbtVisInd "ENM";
BA_ "SignalLongName" SG_ 1221 CmdThrdRwLtStbtVisInd "Command Rear Passenger Thrd Row Left Seat Belt Visual Indication";
BA_ "SignalType" SG_ 1221 AutoBmSlctAllwd "ENM";
BA_ "SignalLongName" SG_ 1221 AutoBmSlctAllwd "Automatic Beam Select Allowed";
BA_ "SignalType" SG_ 1221 DrSlctdSpdLmtAutMdSpdLmtStat "ENM";
BA_ "SignalLongName" SG_ 1221 DrSlctdSpdLmtAutMdSpdLmtStat "Driver Selected Speed Limiter Auto Mode Speed Limit Status";
BA_ "SignalType" SG_ 1221 DrLckStsRR "ENM";
BA_ "SignalLongName" SG_ 1221 DrLckStsRR "Door Lock Status Right Rear";
BA_ "SignalType" SG_ 1221 DrLckStsRF "ENM";
BA_ "SignalLongName" SG_ 1221 DrLckStsRF "Door Lock Status Right Front";
BA_ "SignalType" SG_ 1222 PAIM_FaildIndOn "ENM";
BA_ "SignalLongName" SG_ 1222 PAIM_FaildIndOn "Park Assist Indication Messages : Failed Indication O";
BA_ "SignalType" SG_ 1222 PAIM_RrOffIndOn "ENM";
BA_ "SignalLongName" SG_ 1222 PAIM_RrOffIndOn "Park Assist Indication Messages : Rear Off Indication On";
BA_ "SignalType" SG_ 1222 PAIM_DsbldIndOn "ENM";
BA_ "SignalLongName" SG_ 1222 PAIM_DsbldIndOn "Park Assist Indication Messages : Disabled Indication On";
BA_ "SignalType" SG_ 1222 PAIM_TeenDrvrPAOffUnvIndOn "ENM";
BA_ "SignalLongName" SG_ 1222 PAIM_TeenDrvrPAOffUnvIndOn "Park Assist Indication Messages : Teen Driver Off Unavailable Indication On";
BA_ "SignalType" SG_ 1222 PAIM_FrtOffIndOn "ENM";
BA_ "SignalLongName" SG_ 1222 PAIM_FrtOffIndOn "Park Assist Indication Messages : Front Off Indication On";
BA_ "SignalType" SG_ 1222 PAIM_SnsrDstbdIndOn "ENM";
BA_ "SignalLongName" SG_ 1222 PAIM_SnsrDstbdIndOn "Park Assist Indication Messages : Sensor Disturbed Indication On";
BA_ "SignalType" SG_ 1222 PAIM_SnsrBlckdIndOn "ENM";
BA_ "SignalLongName" SG_ 1222 PAIM_SnsrBlckdIndOn "Park Assist Indication Messages : Sensor Blocked Indication On";
BA_ "SignalType" SG_ 1222 PAIM_SnsrClnIndOn "ENM";
BA_ "SignalLongName" SG_ 1222 PAIM_SnsrClnIndOn "Park Assist Indication Messages : Sensor Clean Indication On";
BA_ "SignalLongName" SG_ 1222 eLSDActrTrqPctg "Electronic Limited Slip Differential Actuator Torque Percentage";
BA_ "SignalType" SG_ 1222 eLSDActrTrqPctg_Inv "ENM";
BA_ "SignalLongName" SG_ 1222 eLSDActrTrqPctg_Inv "Electronic Limited Slip Differential Actuator Torque Percentage Invalid";
BA_ "SignalType" SG_ 1222 PAIM_OffIndOn "ENM";
BA_ "SignalLongName" SG_ 1222 PAIM_OffIndOn "Park Assist Indication Messages : Off Indication On";
BA_ "SignalType" SG_ 1222 FourWhlDrvWrnIndReq "ENM";
BA_ "SignalLongName" SG_ 1222 FourWhlDrvWrnIndReq "Four Wheel Drive Warning Indication Request";
BA_ "SignalType" SG_ 1222 EnrgMgtLdShdRq "ENM";
BA_ "SignalLongName" SG_ 1222 EnrgMgtLdShdRq "Energy Management Load Shedding Request";
BA_ "SignalType" SG_ 1222 BrkSysHillStrtAsstStat "ENM";
BA_ "SignalLongName" SG_ 1222 BrkSysHillStrtAsstStat "Brake System Hill Start Assist Status";
BA_ "SignalType" SG_ 1222 FrntPsStbltRmIndReq "ENM";
BA_ "SignalLongName" SG_ 1222 FrntPsStbltRmIndReq "Front Passenger Seat Belt Reminder Indication Request";
BA_ "SignalType" SG_ 1222 CrgBedVwAutoLgtCstCurrSetVal "ENM";
BA_ "SignalLongName" SG_ 1222 CrgBedVwAutoLgtCstCurrSetVal "Cargo Bed View Auto Lighting CustomizationCurrent Setting Value";
BA_ "SignalType" SG_ 1222 CnvtBkWndPstnSts "ENM";
BA_ "SignalLongName" SG_ 1222 CnvtBkWndPstnSts "Convertible Back Window Position Status";
BA_ "SignalType" SG_ 1222 CTDStat "ENM";
BA_ "SignalLongName" SG_ 1222 CTDStat "Content Theft Deterrent State";
BA_ "SignalType" SG_ 1222 FrntPsStBltRmOccStat "ENM";
BA_ "SignalLongName" SG_ 1222 FrntPsStBltRmOccStat "Front Passenger Seat Belt Reminder Occupancy Status";
BA_ "SignalType" SG_ 1222 FrntPsStBltRmOccStat_Inv "ENM";
BA_ "SignalLongName" SG_ 1222 FrntPsStBltRmOccStat_Inv "Front Passenger Seat Belt Reminder Occupancy Status Invalid";
BA_ "SignalType" SG_ 1222 EngAirFiltMonSts "ENM";
BA_ "SignalLongName" SG_ 1222 EngAirFiltMonSts "Engine Air Filter Monitor Status";
BA_ "SignalType" SG_ 1222 LnDtWrnCntrlFtrSt "ENM";
BA_ "SignalLongName" SG_ 1222 LnDtWrnCntrlFtrSt "LaneDetectionWarningandControlFeatureState";
BA_ "SignalType" SG_ 1222 FrwdVhImAlrtIndRqst "ENM";
BA_ "SignalLongName" SG_ 1222 FrwdVhImAlrtIndRqst "Forward Vehicle Imminent Alert Indication Request";
BA_ "SignalType" SG_ 1222 AirbgStIndOn "ENM";
BA_ "SignalLongName" SG_ 1222 AirbgStIndOn "Airbag Status Indication On";
BA_ "SignalType" SG_ 1222 PrkAsstStat "ENM";
BA_ "SignalLongName" SG_ 1222 PrkAsstStat "ParkAssistStatus";
BA_ "SignalType" SG_ 1222 NghtVsnSysStat "ENM";
BA_ "SignalLongName" SG_ 1222 NghtVsnSysStat "Night Vision System Status";
BA_ "SignalType" SG_ 1223 FPARS_RtCntr "ENM";
BA_ "SignalLongName" SG_ 1223 FPARS_RtCntr "Front Park Assist Region Status : Right Center Region";
BA_ "SignalType" SG_ 1223 FPARS_Lt "ENM";
BA_ "SignalLongName" SG_ 1223 FPARS_Lt "Front Park Assist Region Status : Left Region";
BA_ "SignalType" SG_ 1223 FPARS_Rt "ENM";
BA_ "SignalLongName" SG_ 1223 FPARS_Rt "Front Park Assist Region Status : Right Region";
BA_ "SignalType" SG_ 1223 FPARS_LtCntr "ENM";
BA_ "SignalLongName" SG_ 1223 FPARS_LtCntr "Front Park Assist Region Status : Left Center Region";
BA_ "SignalType" SG_ 1223 FPLTLI_PrkLmpLtCmd "ENM";
BA_ "SignalLongName" SG_ 1223 FPLTLI_PrkLmpLtCmd "Front Park Lamps and Tail Lamps Information : Park Lamp Left Command";
BA_ "SignalType" SG_ 1223 FPLTLI_AuxPrkLmpLtCmd "ENM";
BA_ "SignalLongName" SG_ 1223 FPLTLI_AuxPrkLmpLtCmd "Front Park Lamps and Tail Lamps Information : Aux Park Lamp Left Command";
BA_ "SignalType" SG_ 1223 FPLTLI_PrkLmpRtCmd "ENM";
BA_ "SignalLongName" SG_ 1223 FPLTLI_PrkLmpRtCmd "Front Park Lamps and Tail Lamps Information : Park Lamp Right Command";
BA_ "SignalLongName" SG_ 1223 PAVehPathCrv "Park Assist Vehicle Path Curvature";
BA_ "SignalType" SG_ 1223 FPLTLI_AuxPrkLmpRtCmd "ENM";
BA_ "SignalLongName" SG_ 1223 FPLTLI_AuxPrkLmpRtCmd "Front Park Lamps and Tail Lamps Information : Aux Park Lamp Right Command";
BA_ "SignalType" SG_ 1223 CrwlModeDndRsnIndReq "ENM";
BA_ "SignalLongName" SG_ 1223 CrwlModeDndRsnIndReq "Crawl Mode Denied Reason Indication Request";
BA_ "SignalLongName" SG_ 1223 FuelFiltRmnLife "Fuel Filter Remaining Life";
BA_ "SignalType" SG_ 1223 BSISP_ETRSHydrlcBrkgStsAuth "ENM";
BA_ "SignalLongName" SG_ 1223 BSISP_ETRSHydrlcBrkgStsAuth "Brake System Information Status Protected : ETRS Hydraulic Braking Status Authenticated";
BA_ "SignalType" SG_ 1223 BSISP_ESCActvAuth "ENM";
BA_ "SignalLongName" SG_ 1223 BSISP_ESCActvAuth "Brake System Information Status Protected : Electronic Stability Control Active Authenticated";
BA_ "SignalType" SG_ 1223 BSISP_TCSFaildAuth "ENM";
BA_ "SignalLongName" SG_ 1223 BSISP_TCSFaildAuth "Brake System Information Status Protected : Traction Control System Failed Authenticated";
BA_ "SignalType" SG_ 1223 MaxChrgSts "ENM";
BA_ "SignalLongName" SG_ 1223 MaxChrgSts "Maximum Charge Status";
BA_ "SignalType" SG_ 1223 ArtcldRnngBrdSt "ENM";
BA_ "SignalLongName" SG_ 1223 ArtcldRnngBrdSt "Articulated Running Board State";
BA_ "SignalType" SG_ 1223 BSISP_ESCSysStsAuth "ENM";
BA_ "SignalLongName" SG_ 1223 BSISP_ESCSysStsAuth "Brake System Information Status Protected : Electronic Stability Control System Status Authenticated";
BA_ "SignalType" SG_ 1223 BSISP_TCSActvAuth "ENM";
BA_ "SignalLongName" SG_ 1223 BSISP_TCSActvAuth "Brake System Information Status Protected : Traction Control System Active Authenticated";
BA_ "SignalType" SG_ 1223 BSISP_TCSDrvrIntntAuth "ENM";
BA_ "SignalLongName" SG_ 1223 BSISP_TCSDrvrIntntAuth "Brake System Information Status Protected : Traction Control System Driver Intent Authenticated";
BA_ "SignalType" SG_ 1224 BVSCRP_CPSAxlTrqCmdLimStsAuth "ENM";
BA_ "SignalLongName" SG_ 1224 BVSCRP_CPSAxlTrqCmdLimStsAuth "Body Vehicle Speed Control Response Protected : Collision Preparation System Axle Torque Command Limiting Status Authenticated";
BA_ "SignalType" SG_ 1224 BVSCRP_ACCAxlTrqCmdReqStsAuth "ENM";
BA_ "SignalLongName" SG_ 1224 BVSCRP_ACCAxlTrqCmdReqStsAuth "Body Vehicle Speed Control Response Protected : Adaptive Cruise Control Axle Torque Command Request Status Authenticated";
BA_ "SignalType" SG_ 1224 BVSCRP_ACCAxlTrqCmdLimStsAuth "ENM";
BA_ "SignalLongName" SG_ 1224 BVSCRP_ACCAxlTrqCmdLimStsAuth "Body Vehicle Speed Control Response Protected : Adaptive Cruise Control Axle Torque Command Limiting Status Authenticated";
BA_ "SignalType" SG_ 1224 BVSCRP_CruzCtlEnbldAuth "ENM";
BA_ "SignalLongName" SG_ 1224 BVSCRP_CruzCtlEnbldAuth "Body Vehicle Speed Control Response Protected : Cruise Control Enabled Authenticated";
BA_ "SignalLongName" SG_ 1224 BVSCRP_CltchPdlActPosAuth "Body Vehicle Speed Control Response Protected : Clutch Pedal Actual Position Authenticated";
BA_ "SignalType" SG_ 1224 BVSCRP_CPSAxlTrqCmdReqStsAuth "ENM";
BA_ "SignalLongName" SG_ 1224 BVSCRP_CPSAxlTrqCmdReqStsAuth "Body Vehicle Speed Control Response Protected : Collision Preparation System Axle Torque Command Request Status Authenticated";
BA_ "SignalLongName" SG_ 1224 TCTPIR_EstdClchTmpDisp "Transmission Clutch Thermal Protection Indication Request : Estimated Clutch Temperature Display";
BA_ "SignalType" SG_ 1224 BVSCRP_CltchPdlActPosAuth_Inv "ENM";
BA_ "SignalLongName" SG_ 1224 BVSCRP_CltchPdlActPosAuth_Inv "Body Vehicle Speed Control Response Protected : Clutch Pedal Actual Position Authenticated Invalid";
BA_ "SignalType" SG_ 1224 TCTPIR_DrvrNtfn "ENM";
BA_ "SignalLongName" SG_ 1224 TCTPIR_DrvrNtfn "Transmission Clutch Thermal Protection Indication Request : Driver Notification";
BA_ "SignalLongName" SG_ 1224 TCTPIR_EstdClchCoolDnTmpTgtDisp "Transmission Clutch Thermal Protection Indication Request : Estimated Clutch Cool Down Temperature Target Display";
BA_ "SignalLongName" SG_ 1224 RTPP_TirePrsRRAuth "BCM General Information 1 Protected : Tire Pressure Right Rear Authenticated";
BA_ "SignalType" SG_ 1224 RTPP_TirePrsRRAuth_Inv "ENM";
BA_ "SignalLongName" SG_ 1224 RTPP_TirePrsRRAuth_Inv "BCM General Information 1 Protected : Tire Pressure Right Rear Authenticated Invalid";
BA_ "SignalLongName" SG_ 1224 RTPP_TirePrsLRAuth "BCM General Information 1 Protected : Tire Pressure Left Rear Authenticated";
BA_ "SignalType" SG_ 1224 RTPP_TirePrsLRAuth_Inv "ENM";
BA_ "SignalLongName" SG_ 1224 RTPP_TirePrsLRAuth_Inv "BCM General Information 1 Protected : Tire Pressure Left Rear Authenticated Invalid";
BA_ "SignalType" SG_ 1224 AdptCrsCntrlEngd "ENM";
BA_ "SignalLongName" SG_ 1224 AdptCrsCntrlEngd "Adaptive Cruise Control Engaged";
BA_ "SignalLongName" SG_ 1224 SGI_PV "Seat General Information : Protection Value";
BA_ "SignalLongName" SG_ 1224 SGI_ARC "Seat General Information : Alive Rolling Count";
BA_ "SignalType" SG_ 1224 SGI_ServStSysIndOn "ENM";
BA_ "SignalLongName" SG_ 1224 SGI_ServStSysIndOn "Seat General Information : Service Seat System Indication On";
BA_ "SignalLongName" SG_ 1225 RRSAP_HdrstFwdRrwd "Right Rear Seat Actuator Priority : Headrest Forward/Rearward";
BA_ "SignalLongName" SG_ 1225 RRSAP_HdrstWngsInOut "Right Rear Seat Actuator Priority : Headrest Wings Inward/Outward";
BA_ "SignalLongName" SG_ 1225 RRSAP_CshBlstrInOut "Right Rear Seat Actuator Priority : Cushion Bolster In/Out";
BA_ "SignalLongName" SG_ 1225 RRSAP_HdrstUpDn "Right Rear Seat Actuator Priority : Headrest Up/Down";
BA_ "SignalLongName" SG_ 1225 RRSAP_BkBlstrInOut "Right Rear Seat Actuator Priority : Back Bolster In/Out";
BA_ "SignalLongName" SG_ 1225 RRSAP_LmbrUpDwn "Right Rear Seat Actuator Priority : Lumbar Up/Down";
BA_ "SignalLongName" SG_ 1225 RRSAP_BkCshBlstrInOut "Right Rear Seat Actuator Priority : Back and Cushion Bolster In/Out";
BA_ "SignalLongName" SG_ 1225 RRSAP_CshLgthAdjFdRr "Right Rear Seat Actuator Priority : Cushion Length Adjustment Forward/Rearward";
BA_ "SignalLongName" SG_ 1225 RRSAP_Massg "Right Rear Seat Actuator Priority : Massage";
BA_ "SignalLongName" SG_ 1225 RRSAP_HdrstUpDnFdRr "Right Rear Seat Actuator Priority : Headrest Up/Down and Forward/Rearward";
BA_ "SignalLongName" SG_ 1225 RRSAP_LmbrFwdRr "Right Rear Seat Actuator Priority : Lumbar Forward/Rearward";
BA_ "SignalLongName" SG_ 1225 RRSAP_HdrstTltFwdRr "Right Rear Seat Actuator Priority : Headrest Tilt Forward/Rearward";
BA_ "SignalLongName" SG_ 1225 RRSAP_UprShldrFwdRr "Right Rear Seat Actuator Priority : Upper Shoulder Forward/Rearward";
BA_ "SignalLongName" SG_ 1225 RRSAP_LmbrUpDnFdRr "Right Rear Seat Actuator Priority : Lumbar Up/Down and Forward/Rearward";
BA_ "SignalType" SG_ 1225 DrvStBltRmIndReq "ENM";
BA_ "SignalLongName" SG_ 1225 DrvStBltRmIndReq "Driver Seat Belt Reminder Indication Request";
BA_ "SignalType" SG_ 1225 AirbgStsIndReq "ENM";
BA_ "SignalLongName" SG_ 1225 AirbgStsIndReq "Airbag Status Indication Request";
BA_ "SignalLongName" SG_ 1226 RFSAP_CshLgthAdjFdRr "Right Front Seat Actuator Priority : Cushion Length Adjustment Forward/Rearward";
BA_ "SignalLongName" SG_ 1226 RFSAP_HdrstWngsInOut "Right Front Seat Actuator Priority : Headrest Wings Inward/Outward";
BA_ "SignalLongName" SG_ 1226 RFSAP_LmbrUpDnFdRr "Right Front Seat Actuator Priority : Lumbar Up/Down and Forward/Rearward";
BA_ "SignalLongName" SG_ 1226 RFSAP_HdrstFwdRrwd "Right Front Seat Actuator Priority : Headrest Forward/Rearward";
BA_ "SignalLongName" SG_ 1226 RFSAP_Massg "Right Front Seat Actuator Priority : Massage";
BA_ "SignalLongName" SG_ 1226 RFSAP_HdrstUpDn "Right Front Seat Actuator Priority : Headrest Up/Down";
BA_ "SignalLongName" SG_ 1226 RFSAP_UprShldrFwdRr "Right Front Seat Actuator Priority : Upper Shoulder Forward/Rearward";
BA_ "SignalLongName" SG_ 1226 RFSAP_HdrstUpDnFdRr "Right Front Seat Actuator Priority : Headrest Up/Down and Forward/Rearward";
BA_ "SignalLongName" SG_ 1226 RFSAP_BkBlstrInOut "Right Front Seat Actuator Priority : Back Bolster In/Out";
BA_ "SignalLongName" SG_ 1226 RFSAP_CshBlstrInOut "Right Front Seat Actuator Priority : Cushion Bolster In/Out";
BA_ "SignalLongName" SG_ 1226 RFSAP_LmbrFwdRr "Right Front Seat Actuator Priority : Lumbar Forward/Rearward";
BA_ "SignalLongName" SG_ 1226 RFSAP_BkCshBlstrInOut "Right Front Seat Actuator Priority : Back and Cushion Bolster In/Out";
BA_ "SignalLongName" SG_ 1226 RFSAP_HdrstTltFwdRr "Right Front Seat Actuator Priority : Headrest Tilt Forward/Rearward";
BA_ "SignalLongName" SG_ 1226 RFSAP_LmbrUpDwn "Right Front Seat Actuator Priority : Lumbar Up/Down";
BA_ "SignalLongName" SG_ 1226 XferCaseRngShfSpdLim "Transfer Case Range Shift Speed Limit";
BA_ "SignalLongName" SG_ 1227 LRSAP_LmbrUpDnFdRr "Left Rear Seat Actuator Priority : Lumbar Up/Down and Forward/Rearward";
BA_ "SignalLongName" SG_ 1227 LRSAP_HdrstFwdRrwd "Left Rear Seat Actuator Priority : Headrest Forward/Rearward";
BA_ "SignalLongName" SG_ 1227 LRSAP_HdrstWngsInOut "Left Rear Seat Actuator Priority : Headrest Wings Inward/Outward";
BA_ "SignalLongName" SG_ 1227 LRSAP_Massg "Left Rear Seat Actuator Priority : Massage";
BA_ "SignalLongName" SG_ 1227 LRSAP_HdrstUpDn "Left Rear Seat Actuator Priority : Headrest Up/Down";
BA_ "SignalLongName" SG_ 1227 LRSAP_UprShldrFwdRr "Left Rear Seat Actuator Priority : Upper Shoulder Forward/Rearward";
BA_ "SignalLongName" SG_ 1227 LRSAP_CshBlstrInOut "Left Rear Seat Actuator Priority : Cushion Bolster In/Out";
BA_ "SignalLongName" SG_ 1227 LRSAP_CshLgthAdjFdRr "Left Rear Seat Actuator Priority : Cushion Length Adjustment Forward/Rearward";
BA_ "SignalLongName" SG_ 1227 LRSAP_HdrstUpDnFdRr "Left Rear Seat Actuator Priority : Headrest Up/Down and Forward/Rearward";
BA_ "SignalLongName" SG_ 1227 LRSAP_LmbrFwdRr "Left Rear Seat Actuator Priority : Lumbar Forward/Rearward";
BA_ "SignalLongName" SG_ 1227 LRSAP_BkBlstrInOut "Left Rear Seat Actuator Priority : Back Bolster In/Out";
BA_ "SignalLongName" SG_ 1227 LRSAP_BkCshBlstrInOut "Left Rear Seat Actuator Priority : Back and Cushion Bolster In/Out";
BA_ "SignalLongName" SG_ 1227 LRSAP_LmbrUpDwn "Left Rear Seat Actuator Priority : Lumbar Up/Down";
BA_ "SignalLongName" SG_ 1227 LRSAP_HdrstTltFwdRr "Left Rear Seat Actuator Priority : Headrest Tilt Forward/Rearward";
BA_ "SignalLongName" SG_ 1227 EngOilRmnLf "Engine Oil Remaining Life";
BA_ "SignalLongName" SG_ 1228 LFSAP_HdrstUpDn "Left Front Seat Actuator Priority : Headrest Up/Down";
BA_ "SignalLongName" SG_ 1228 LFSAP_UprShldrFwdRr "Left Front Seat Actuator Priority : Upper Shoulder Forward/Rearward";
BA_ "SignalLongName" SG_ 1228 LFSAP_HdrstWngsInOut "Left Front Seat Actuator Priority : Headrest Wings Inward/Outward";
BA_ "SignalLongName" SG_ 1228 LFSAP_LmbrUpDwn "Left Front Seat Actuator Priority : Lumbar Up/Down";
BA_ "SignalLongName" SG_ 1228 LFSAP_BkCshBlstrInOut "Left Front Seat Actuator Priority : Back and Cushion Bolster In/Out";
BA_ "SignalLongName" SG_ 1228 LFSAP_CshLgthAdjFdRr "Left Front Seat Actuator Priority : Cushion Length Adjustment Forward/Rearward";
BA_ "SignalLongName" SG_ 1228 LFSAP_BkBlstrInOut "Left Front Seat Actuator Priority : Back Bolster In/Out";
BA_ "SignalLongName" SG_ 1228 LFSAP_HdrstTltFwdRr "Left Front Seat Actuator Priority : Headrest Tilt Forward/Rearward";
BA_ "SignalLongName" SG_ 1228 LFSAP_LmbrUpDnFdRr "Left Front Seat Actuator Priority : Lumbar Up/Down and Forward/Rearward";
BA_ "SignalLongName" SG_ 1228 LFSAP_LmbrFwdRr "Left Front Seat Actuator Priority : Lumbar Forward/Rearward";
BA_ "SignalLongName" SG_ 1228 LFSAP_HdrstUpDnFdRr "Left Front Seat Actuator Priority : Headrest Up/Down and Forward/Rearward";
BA_ "SignalLongName" SG_ 1228 LFSAP_HdrstFwdRrwd "Left Front Seat Actuator Priority : Headrest Forward/Rearward";
BA_ "SignalLongName" SG_ 1228 LFSAP_Massg "Left Front Seat Actuator Priority : Massage";
BA_ "SignalLongName" SG_ 1228 LFSAP_CshBlstrInOut "Left Front Seat Actuator Priority : Cushion Bolster In/Out";
BA_ "SignalType" SG_ 1228 AutoEmrgBrkgDsbldIndOn "ENM";
BA_ "SignalLongName" SG_ 1228 AutoEmrgBrkgDsbldIndOn "Automatic Emergency Braking Disabled Indication On";
BA_ "SignalLongName" SG_ 1228 ESCVehTopSpdLimDispVal "Electronic Stability Control Vehicle Top Speed Limit Display Value";
BA_ "SignalType" SG_ 1230 PTCrnkAct "ENM";
BA_ "SignalLongName" SG_ 1230 PTCrnkAct "Powertrain Crank Active";
BA_ "SignalType" SG_ 1230 DrvShftCntrlTrgtGr "ENM";
BA_ "SignalLongName" SG_ 1230 DrvShftCntrlTrgtGr "Driver Shift Control Target Gear";
BA_ "SignalType" SG_ 1240 DrvrAlrtTypCstAvlFlg3 "ENM";
BA_ "SignalLongName" SG_ 1240 DrvrAlrtTypCstAvlFlg3 "DriverAlertTypeCustomizationAvailabilityFlag3";
BA_ "SignalType" SG_ 1240 DrvrAlrtTypCstAvlFlg2 "ENM";
BA_ "SignalLongName" SG_ 1240 DrvrAlrtTypCstAvlFlg2 "DriverAlertTypeCustomizationAvailabilityFlag2";
BA_ "SignalType" SG_ 1240 DrvrAlrtTypCstAvlFlg1 "ENM";
BA_ "SignalLongName" SG_ 1240 DrvrAlrtTypCstAvlFlg1 "DriverAlertTypeCustomizationAvailabilityFlag1";
BA_ "SignalType" SG_ 1240 CrgBedVwAutoLgtCstSetAval "ENM";
BA_ "SignalLongName" SG_ 1240 CrgBedVwAutoLgtCstSetAval "Cargo Bed View Auto Lighting Customization Setting Available";
BA_ "SignalType" SG_ 1240 RrClsrAjrStat "ENM";
BA_ "SignalLongName" SG_ 1240 RrClsrAjrStat "Rear Closure Ajar Status";
BA_ "SignalType" SG_ 1240 RrClsrAjrStat_Inv "ENM";
BA_ "SignalLongName" SG_ 1240 RrClsrAjrStat_Inv "Rear Closure Ajar Status Invalid";
BA_ "SignalType" SG_ 1240 RRDrAjrStat "ENM";
BA_ "SignalLongName" SG_ 1240 RRDrAjrStat "Right Rear Door Ajar Status";
BA_ "SignalType" SG_ 1240 RRDrAjrStat_Inv "ENM";
BA_ "SignalLongName" SG_ 1240 RRDrAjrStat_Inv "Right Rear Door Ajar Status Invalid";
BA_ "SignalType" SG_ 1240 EsyExtCstStAvl "ENM";
BA_ "SignalLongName" SG_ 1240 EsyExtCstStAvl "EasyExitCustomizationSettingAvailable";
BA_ "SignalType" SG_ 1240 DsplyTrgVdOn "ENM";
BA_ "SignalLongName" SG_ 1240 DsplyTrgVdOn "Display Triggered Video On";
BA_ "SignalType" SG_ 1240 DspFrnt360CmrON "ENM";
BA_ "SignalLongName" SG_ 1240 DspFrnt360CmrON "Display Front 360 Camera ON";
BA_ "SignalType" SG_ 1240 DrvrAlrtTypCstStAvl "ENM";
BA_ "SignalLongName" SG_ 1240 DrvrAlrtTypCstStAvl "DriverAlertTypeCustomizationSettingAvailable";
BA_ "SignalType" SG_ 1240 DrvrAlrtTypCstAvlFlg7 "ENM";
BA_ "SignalLongName" SG_ 1240 DrvrAlrtTypCstAvlFlg7 "DriverAlertTypeCustomizationAvailabilityFlag7";
BA_ "SignalType" SG_ 1240 DrvrAlrtTypCstAvlFlg6 "ENM";
BA_ "SignalLongName" SG_ 1240 DrvrAlrtTypCstAvlFlg6 "DriverAlertTypeCustomizationAvailabilityFlag6";
BA_ "SignalType" SG_ 1240 DrvrAlrtTypCstAvlFlg5 "ENM";
BA_ "SignalLongName" SG_ 1240 DrvrAlrtTypCstAvlFlg5 "DriverAlertTypeCustomizationAvailabilityFlag5";
BA_ "SignalType" SG_ 1240 DrvrAlrtTypCstAvlFlg4 "ENM";
BA_ "SignalLongName" SG_ 1240 DrvrAlrtTypCstAvlFlg4 "DriverAlertTypeCustomizationAvailabilityFlag4";
BA_ "SignalType" SG_ 1240 LnChgAlrtLmtdTrlrIndOn "ENM";
BA_ "SignalLongName" SG_ 1240 LnChgAlrtLmtdTrlrIndOn "Lane Change Alert Limited by Trailer Indication On";
BA_ "SignalType" SG_ 1240 LnChgAlrtCstStAvl "ENM";
BA_ "SignalLongName" SG_ 1240 LnChgAlrtCstStAvl "LaneChangeAlertCustomizationSettingAvailable";
BA_ "SignalType" SG_ 1240 JckKnfDtnCstSetAval "ENM";
BA_ "SignalLongName" SG_ 1240 JckKnfDtnCstSetAval "Jack Knife Detection Customization Setting Available";
BA_ "SignalType" SG_ 1240 HptcStFldIndOn "ENM";
BA_ "SignalLongName" SG_ 1240 HptcStFldIndOn "Haptic Seat Failed Indication On";
BA_ "SignalType" SG_ 1240 GoNotfrCstStAvl "ENM";
BA_ "SignalLongName" SG_ 1240 GoNotfrCstStAvl "GoNotifierCustomizationSettingAvailable";
BA_ "SignalType" SG_ 1240 GlrFrHgBmRspTypCstStAvl "ENM";
BA_ "SignalLongName" SG_ 1240 GlrFrHgBmRspTypCstStAvl "Glare Free High Beam Response Type Customization Setting Available";
BA_ "SignalType" SG_ 1240 FrwdImpMtgnOpSlctCstStAvl "ENM";
BA_ "SignalLongName" SG_ 1240 FrwdImpMtgnOpSlctCstStAvl "ForwardImpactMitigationOperation SelectCustomizationSettingAvailable";
BA_ "SignalType" SG_ 1240 FrntPCMRspTypCstStAvl "ENM";
BA_ "SignalLongName" SG_ 1240 FrntPCMRspTypCstStAvl "FrontPCMResponseTypeCustomizationSettingAvailable";
BA_ "SignalType" SG_ 1240 RnngBrdManDplyCstSetSelbl "ENM";
BA_ "SignalLongName" SG_ 1240 RnngBrdManDplyCstSetSelbl "Running Boards Manual Deployment Customization Setting Selectable";
BA_ "SignalType" SG_ 1240 RnngBrdManDplyCstSetAval "ENM";
BA_ "SignalLongName" SG_ 1240 RnngBrdManDplyCstSetAval "Running Boards Manual Deployment Customization Setting Available";
BA_ "SignalType" SG_ 1240 RnngBrdAutoDplyCstSetAval "ENM";
BA_ "SignalLongName" SG_ 1240 RnngBrdAutoDplyCstSetAval "Running Boards Automatic Deployment Customization Setting Available";
BA_ "SignalType" SG_ 1240 PrkAsstTrHtchPsntCstStAvl "ENM";
BA_ "SignalLongName" SG_ 1240 PrkAsstTrHtchPsntCstStAvl "ParkAssistTrailerHitchPresentCustomizationSettingAvailable";
BA_ "SignalType" SG_ 1240 PrkAsstONOFFCstStAvl "ENM";
BA_ "SignalLongName" SG_ 1240 PrkAsstONOFFCstStAvl "ParkAssistOnOffCustomizationSettingAvailable";
BA_ "SignalType" SG_ 1240 LtRtHnTrCstStAvl "ENM";
BA_ "SignalLongName" SG_ 1240 LtRtHnTrCstStAvl "Left Right Hand Traffic Customization Setting Available";
BA_ "SignalType" SG_ 1240 LnChgAlrtSysOffIndOn "ENM";
BA_ "SignalLongName" SG_ 1240 LnChgAlrtSysOffIndOn "Lane Change Alert System Off Indication On";
BA_ "SignalType" SG_ 1240 SBZAlrtCstAvlFlg6 "ENM";
BA_ "SignalLongName" SG_ 1240 SBZAlrtCstAvlFlg6 "SideBlindZoneAlertCustomizationAvailabilityFlag6";
BA_ "SignalType" SG_ 1240 SBZAlrtCstAvlFlg5 "ENM";
BA_ "SignalLongName" SG_ 1240 SBZAlrtCstAvlFlg5 "SideBlindZoneAlertCustomizationAvailabilityFlag5";
BA_ "SignalType" SG_ 1240 SBZAlrtCstAvlFlg4 "ENM";
BA_ "SignalLongName" SG_ 1240 SBZAlrtCstAvlFlg4 "SideBlindZoneAlertCustomizationAvailabilityFlag4";
BA_ "SignalType" SG_ 1240 SBZAlrtCstAvlFlg3 "ENM";
BA_ "SignalLongName" SG_ 1240 SBZAlrtCstAvlFlg3 "SideBlindZoneAlertCustomizationAvailabilityFlag3";
BA_ "SignalType" SG_ 1240 SBZAlrtCstAvlFlg2 "ENM";
BA_ "SignalLongName" SG_ 1240 SBZAlrtCstAvlFlg2 "SideBlindZoneAlertCustomizationAvailabilityFlag2";
BA_ "SignalType" SG_ 1240 SBZAlrtCstAvlFlg1 "ENM";
BA_ "SignalLongName" SG_ 1240 SBZAlrtCstAvlFlg1 "SideBlindZoneAlertCustomizationAvailabilityFlag1";
BA_ "SignalType" SG_ 1240 RrVwPrkAstSymCsStAvl "ENM";
BA_ "SignalLongName" SG_ 1240 RrVwPrkAstSymCsStAvl "RearViewParkAssistSymbolCustomizationSettingAvailable";
BA_ "SignalType" SG_ 1240 RrCrsTrfcAlrtCstStAvl "ENM";
BA_ "SignalLongName" SG_ 1240 RrCrsTrfcAlrtCstStAvl "RearCrossTrafficAlertCustomizationSettingAvailable";
BA_ "SignalType" SG_ 1240 TargaTopAjrStat "ENM";
BA_ "SignalLongName" SG_ 1240 TargaTopAjrStat "Targa Top Ajar Status";
BA_ "SignalType" SG_ 1240 StBltTghtngCstStAv "ENM";
BA_ "SignalLongName" SG_ 1240 StBltTghtngCstStAv "Seat Belt Tightening CustomizationSettingAvailable";
BA_ "SignalType" SG_ 1240 SrrndVwLghtCsStAvl "ENM";
BA_ "SignalLongName" SG_ 1240 SrrndVwLghtCsStAvl "Surround View Lighting Customization Setting Available";
BA_ "SignalType" SG_ 1240 ServSdDtcSysIndOn "ENM";
BA_ "SignalLongName" SG_ 1240 ServSdDtcSysIndOn "Service Side Detection System Indication On";
BA_ "SignalType" SG_ 1240 SdDtcTempUnvIndOn "ENM";
BA_ "SignalLongName" SG_ 1240 SdDtcTempUnvIndOn "Side Detection Temporarily Unavailable Indication On";
BA_ "SignalType" SG_ 1240 SBZAlrtOffIndOn "ENM";
BA_ "SignalLongName" SG_ 1240 SBZAlrtOffIndOn "Side Blind Zone Alert Off Indication On";
BA_ "SignalType" SG_ 1240 SBZAlrtCstStAvl "ENM";
BA_ "SignalLongName" SG_ 1240 SBZAlrtCstStAvl "SideBlindZoneAlertCustomizationSettingAvailable";
BA_ "SignalType" SG_ 1240 SBZAlrtCstAvlFlg7 "ENM";
BA_ "SignalLongName" SG_ 1240 SBZAlrtCstAvlFlg7 "SideBlindZoneAlertCustomizationAvailabilityFlag7";
BA_ "SignalLongName" SG_ 1240 EngAirFiltLifeRmn "Engine Air Filter Life Remaining";
BA_ "SignalType" SG_ 1240 TrnSigSwRtActv "ENM";
BA_ "SignalLongName" SG_ 1240 TrnSigSwRtActv "Turn Signal Switch Right Active";
BA_ "SignalType" SG_ 1240 TrnSigSwLtActv "ENM";
BA_ "SignalLongName" SG_ 1240 TrnSigSwLtActv "Turn Signal Switch Left Active";
BA_ "SignalType" SG_ 1240 TrlrMirVidGdlnsCstSetAval "ENM";
BA_ "SignalLongName" SG_ 1240 TrlrMirVidGdlnsCstSetAval "Trailering Mirror Video Guidelines Customization Setting Available";
BA_ "SignalType" SG_ 1240 TrlrMirVidEnblCstSetAval "ENM";
BA_ "SignalLongName" SG_ 1240 TrlrMirVidEnblCstSetAval "Trailering Mirror Video Enable Customization Setting Available";
BA_ "SignalType" SG_ 1240 TrlrConnStat "ENM";
BA_ "SignalLongName" SG_ 1240 TrlrConnStat "Trailer Connection Status";
BA_ "SignalType" SG_ 1240 TrffcLgtAsstCstSetAval "ENM";
BA_ "SignalLongName" SG_ 1240 TrffcLgtAsstCstSetAval "Traffic Light Assist Customization Setting Available";
BA_ "SignalType" SG_ 1240 PwrRrClsrCstCurrSetVal "ENM";
BA_ "SignalLongName" SG_ 1240 PwrRrClsrCstCurrSetVal "Power Rear Closure Customization Current Setting Value";
BA_ "SignalType" SG_ 1241 GlrFrHgBmRspTypCstCurSetVal "ENM";
BA_ "SignalLongName" SG_ 1241 GlrFrHgBmRspTypCstCurSetVal "Glare Free High Beam Response Type Customization Current Setting Value";
BA_ "SignalType" SG_ 1241 FrwdImpMtgnOpSlctCstCrStVal "ENM";
BA_ "SignalLongName" SG_ 1241 FrwdImpMtgnOpSlctCstCrStVal "ForwardImpactMitigationOperationSelectCustomizationCurrentSettingValue";
BA_ "SignalType" SG_ 1241 FrntPCMRspTypCstCrStVal "ENM";
BA_ "SignalLongName" SG_ 1241 FrntPCMRspTypCstCrStVal "FrontPCMResponseTypeCustomizationCurrentSettingValue";
BA_ "SignalType" SG_ 1241 LnChgAlrtCstCrStVal "ENM";
BA_ "SignalLongName" SG_ 1241 LnChgAlrtCstCrStVal "LaneChangeAlertCustomizationCurrentSettingValue";
BA_ "SignalType" SG_ 1241 JckKnfDtnCstCurrSetVal "ENM";
BA_ "SignalLongName" SG_ 1241 JckKnfDtnCstCurrSetVal "Jack Knife Detection Customization Current Setting Value";
BA_ "SignalType" SG_ 1241 GoNotfrCstCrStVal "ENM";
BA_ "SignalLongName" SG_ 1241 GoNotfrCstCrStVal "GoNotifierCustomizationCurrentSettingValue";
BA_ "SignalType" SG_ 1241 PrkAsstONOFFCstCrStVal "ENM";
BA_ "SignalLongName" SG_ 1241 PrkAsstONOFFCstCrStVal "ParkAssistOnOffCustomizationCurrentSettingValue";
BA_ "SignalType" SG_ 1241 LtRtHnTrCstCurSetVal "ENM";
BA_ "SignalLongName" SG_ 1241 LtRtHnTrCstCurSetVal "Left Right Hand Traffic Customization Current Setting Value";
BA_ "SignalType" SG_ 1241 RnngBrdAutoDplyCstCurrSetVal "ENM";
BA_ "SignalLongName" SG_ 1241 RnngBrdAutoDplyCstCurrSetVal "Running Boards Automatic Deployment Customization Current Setting Value";
BA_ "SignalType" SG_ 1241 PFASndSeltnCstCurrSetVal "ENM";
BA_ "SignalLongName" SG_ 1241 PFASndSeltnCstCurrSetVal "Pedestrian Friendly Alert Sound Selection Customization Current Setting Value";
BA_ "SignalType" SG_ 1241 PrkAsstTrHtchPsntCstCrStVal "ENM";
BA_ "SignalLongName" SG_ 1241 PrkAsstTrHtchPsntCstCrStVal "ParkAssistTrailerHitchPresentCustomizationCurrentSettingValue";
BA_ "SignalType" SG_ 1241 RrVwPrkAstSymCsCrStVal "ENM";
BA_ "SignalLongName" SG_ 1241 RrVwPrkAstSymCsCrStVal "RearViewParkAssistSymbolCustomizationCurrentSettingValue";
BA_ "SignalType" SG_ 1241 RrCrsTrfcAlrtCstCrStVal "ENM";
BA_ "SignalLongName" SG_ 1241 RrCrsTrfcAlrtCstCrStVal "RearCrossTrafficAlertCustomizationCurrentSettingValue";
BA_ "SignalType" SG_ 1241 RnngBrdManDplyCstCurrSetVal "ENM";
BA_ "SignalLongName" SG_ 1241 RnngBrdManDplyCstCurrSetVal "Running Boards Manual Deployment Customization Current Setting Value";
BA_ "SignalType" SG_ 1241 SrrndVwLghtCsCrStVal "ENM";
BA_ "SignalLongName" SG_ 1241 SrrndVwLghtCsCrStVal "Surround View Lighting Customization Current Setting Value";
BA_ "SignalType" SG_ 1241 SBZAlrtCstCrStVal "ENM";
BA_ "SignalLongName" SG_ 1241 SBZAlrtCstCrStVal "SideBlindZoneAlertCustomizationCurrentSettingValue";
BA_ "SignalType" SG_ 1241 TrlrMirVidGdlnsCstCurrSetVal "ENM";
BA_ "SignalLongName" SG_ 1241 TrlrMirVidGdlnsCstCurrSetVal "Trailering Mirror Video Guidelines Customization Current Setting Value";
BA_ "SignalType" SG_ 1241 TrffcLgtAsstCstCurrSetVal "ENM";
BA_ "SignalLongName" SG_ 1241 TrffcLgtAsstCstCurrSetVal "Traffic Light Assist Customization Current Setting Value";
BA_ "SignalType" SG_ 1241 StBltTghtngCstCrStVal "ENM";
BA_ "SignalLongName" SG_ 1241 StBltTghtngCstCrStVal "Seat Belt Tightening CustomizationCurrentSettingValue";
BA_ "SignalType" SG_ 1241 CnvtblTopTneuAjrStat "ENM";
BA_ "SignalLongName" SG_ 1241 CnvtblTopTneuAjrStat "Convertible Top Tonneau Ajar Status";
BA_ "SignalType" SG_ 1241 LftglsAjrStat "ENM";
BA_ "SignalLongName" SG_ 1241 LftglsAjrStat "Liftglass Ajar Status";
BA_ "SignalType" SG_ 1241 LftglsAjrStat_Inv "ENM";
BA_ "SignalLongName" SG_ 1241 LftglsAjrStat_Inv "Liftglass Ajar Status Invalid";
BA_ "SignalType" SG_ 1241 LRDrAjrStat "ENM";
BA_ "SignalLongName" SG_ 1241 LRDrAjrStat "Left Rear Door Ajar Status";
BA_ "SignalType" SG_ 1241 LRDrAjrStat_Inv "ENM";
BA_ "SignalLongName" SG_ 1241 LRDrAjrStat_Inv "Left Rear Door Ajar Status Invalid";
BA_ "SignalType" SG_ 1241 ElvtdIdlCstCrStVal "ENM";
BA_ "SignalLongName" SG_ 1241 ElvtdIdlCstCrStVal "Elevated Idle Customization Current Setting Value";
VAL_ 1425 PTOSet2SpdCstAvlFlg4 0 "FALSE" 1 "TRUE" ;
VAL_ 1425 PTOSet2SpdCstAvlFlg3 0 "FALSE" 1 "TRUE" ;
VAL_ 1425 PTOSet2SpdCstAvlFlg2 0 "FALSE" 1 "TRUE" ;
VAL_ 1425 PTOSet2SpdCstAvlFlg15 0 "FALSE" 1 "TRUE" ;
VAL_ 1425 PTOSet2SpdCstAvlFlg14 0 "FALSE" 1 "TRUE" ;
VAL_ 1425 PTOSet2SpdCstAvlFlg13 0 "FALSE" 1 "TRUE" ;
VAL_ 1425 PTOSet2SpdCstAvlFlg12 0 "FALSE" 1 "TRUE" ;
VAL_ 1425 PTOSet2SpdCstAvlFlg11 0 "FALSE" 1 "TRUE" ;
VAL_ 1425 PTOStndbySpdCstAvlFlg3 0 "FALSE" 1 "TRUE" ;
VAL_ 1425 PTOStndbySpdCstAvlFlg2 0 "FALSE" 1 "TRUE" ;
VAL_ 1425 PTOStndbySpdCstAvlFlg1 0 "FALSE" 1 "TRUE" ;
VAL_ 1425 PTOSet2SpdCstAvlFlg9 0 "FALSE" 1 "TRUE" ;
VAL_ 1425 PTOSet2SpdCstAvlFlg8 0 "FALSE" 1 "TRUE" ;
VAL_ 1425 PTOSet2SpdCstAvlFlg7 0 "FALSE" 1 "TRUE" ;
VAL_ 1425 PTOSet2SpdCstAvlFlg6 0 "FALSE" 1 "TRUE" ;
VAL_ 1425 PTOSet2SpdCstAvlFlg5 0 "FALSE" 1 "TRUE" ;
VAL_ 1425 PTOTpStpSpdCstAvlFlg4 0 "FALSE" 1 "TRUE" ;
VAL_ 1425 PTOTpStpSpdCstAvlFlg3 0 "FALSE" 1 "TRUE" ;
VAL_ 1425 PTOTpStpSpdCstAvlFlg2 0 "FALSE" 1 "TRUE" ;
VAL_ 1425 PTOTpStpSpdCstAvlFlg1 0 "FALSE" 1 "TRUE" ;
VAL_ 1425 PTOStndbySpdCstAvlFlg7 0 "FALSE" 1 "TRUE" ;
VAL_ 1425 PTOStndbySpdCstAvlFlg6 0 "FALSE" 1 "TRUE" ;
VAL_ 1425 PTOStndbySpdCstAvlFlg5 0 "FALSE" 1 "TRUE" ;
VAL_ 1425 PTOStndbySpdCstAvlFlg4 0 "FALSE" 1 "TRUE" ;
VAL_ 1425 UpftrSnwPlwIndReq 0 "No Indication" 1 "Active" 2 "Active with Headlamps Disabled" 3 "Not Available" ;
VAL_ 1425 UpftrRrAprchPrtctnIndReq 0 "No Indication" 1 "Armed" 2 "Deactivated" 3 "Triggered" 4 "Not Available" ;
VAL_ 1425 PTOTpStpSpdCstAvlFlg7 0 "FALSE" 1 "TRUE" ;
VAL_ 1425 PTOTpStpSpdCstAvlFlg6 0 "FALSE" 1 "TRUE" ;
VAL_ 1425 PTOTpStpSpdCstAvlFlg5 0 "FALSE" 1 "TRUE" ;
VAL_ 1425 IBS12VEstdBatTemp_Inv 0 "FALSE" 1 "TRUE" ;
VAL_ 1425 UpftrRadioMutReqd 0 "FALSE" 1 "TRUE" ;
VAL_ 1425 UpftrBkupCamActvnReqd 0 "FALSE" 1 "TRUE" ;
VAL_ 1425 UpftrVehStrtEnblIndReq 0 "No Indication" 1 "On" 2 "Off" 3 "Not Available" ;
VAL_ 1425 TransOilFiltChgIndOn 0 "FALSE" 1 "TRUE" ;
VAL_ 1188 StBltTghtngCstAvlFlg7 0 "FALSE" 1 "TRUE" ;
VAL_ 1188 StBltTghtngCstAvlFlg6 0 "FALSE" 1 "TRUE" ;
VAL_ 1188 StBltTghtngCstAvlFlg5 0 "FALSE" 1 "TRUE" ;
VAL_ 1188 StBltTghtngCstAvlFlg4 0 "FALSE" 1 "TRUE" ;
VAL_ 1188 StBltTghtngCstAvlFlg3 0 "FALSE" 1 "TRUE" ;
VAL_ 1188 StBltTghtngCstAvlFlg2 0 "FALSE" 1 "TRUE" ;
VAL_ 1188 StBltTghtngCstAvlFlg1 0 "FALSE" 1 "TRUE" ;
VAL_ 1188 RrCrsTrfcAlrtCstAvlFlg7 0 "FALSE" 1 "TRUE" ;
VAL_ 1188 TrnsOlTmpSnsPrs 0 "FALSE" 1 "TRUE" ;
VAL_ 1188 TrffcLgtAsstCstAvlFlg7 0 "FALSE" 1 "TRUE" ;
VAL_ 1188 TrffcLgtAsstCstAvlFlg6 0 "FALSE" 1 "TRUE" ;
VAL_ 1188 TrffcLgtAsstCstAvlFlg5 0 "FALSE" 1 "TRUE" ;
VAL_ 1188 TrffcLgtAsstCstAvlFlg4 0 "FALSE" 1 "TRUE" ;
VAL_ 1188 TrffcLgtAsstCstAvlFlg3 0 "FALSE" 1 "TRUE" ;
VAL_ 1188 TrffcLgtAsstCstAvlFlg2 0 "FALSE" 1 "TRUE" ;
VAL_ 1188 TrffcLgtAsstCstAvlFlg1 0 "FALSE" 1 "TRUE" ;
VAL_ 1188 CustNonUsblSOC_DuD 0 "FALSE" 1 "TRUE" ;
VAL_ 1189 GoNotfrCstAvlFlg7 0 "FALSE" 1 "TRUE" ;
VAL_ 1189 GoNotfrCstAvlFlg6 0 "FALSE" 1 "TRUE" ;
VAL_ 1189 GoNotfrCstAvlFlg5 0 "FALSE" 1 "TRUE" ;
VAL_ 1189 GoNotfrCstAvlFlg4 0 "FALSE" 1 "TRUE" ;
VAL_ 1189 GoNotfrCstAvlFlg3 0 "FALSE" 1 "TRUE" ;
VAL_ 1189 GoNotfrCstAvlFlg2 0 "FALSE" 1 "TRUE" ;
VAL_ 1189 GoNotfrCstAvlFlg1 0 "FALSE" 1 "TRUE" ;
VAL_ 1189 GlrFrHgBmRspTypCstAvlFlg7 0 "FALSE" 1 "TRUE" ;
VAL_ 1189 LtRtHnTrCstAvlFlg1 0 "FALSE" 1 "TRUE" ;
VAL_ 1189 LnChgAlrtCstAvlFlg7 0 "FALSE" 1 "TRUE" ;
VAL_ 1189 LnChgAlrtCstAvlFlg6 0 "FALSE" 1 "TRUE" ;
VAL_ 1189 LnChgAlrtCstAvlFlg5 0 "FALSE" 1 "TRUE" ;
VAL_ 1189 LnChgAlrtCstAvlFlg4 0 "FALSE" 1 "TRUE" ;
VAL_ 1189 LnChgAlrtCstAvlFlg3 0 "FALSE" 1 "TRUE" ;
VAL_ 1189 LnChgAlrtCstAvlFlg2 0 "FALSE" 1 "TRUE" ;
VAL_ 1189 LnChgAlrtCstAvlFlg1 0 "FALSE" 1 "TRUE" ;
VAL_ 1189 PrkAsstONOFFCstAvlFlg1 0 "FALSE" 1 "TRUE" ;
VAL_ 1189 PTHiElecLdReqd 0 "FALSE" 1 "TRUE" ;
VAL_ 1189 LtRtHnTrCstAvlFlg7 0 "FALSE" 1 "TRUE" ;
VAL_ 1189 LtRtHnTrCstAvlFlg6 0 "FALSE" 1 "TRUE" ;
VAL_ 1189 LtRtHnTrCstAvlFlg5 0 "FALSE" 1 "TRUE" ;
VAL_ 1189 LtRtHnTrCstAvlFlg4 0 "FALSE" 1 "TRUE" ;
VAL_ 1189 LtRtHnTrCstAvlFlg3 0 "FALSE" 1 "TRUE" ;
VAL_ 1189 LtRtHnTrCstAvlFlg2 0 "FALSE" 1 "TRUE" ;
VAL_ 1189 PrkAsstTrHtchPsntCstAvlFlg2 0 "FALSE" 1 "TRUE" ;
VAL_ 1189 PrkAsstTrHtchPsntCstAvlFlg1 0 "FALSE" 1 "TRUE" ;
VAL_ 1189 PrkAsstONOFFCstAvlFlg7 0 "FALSE" 1 "TRUE" ;
VAL_ 1189 PrkAsstONOFFCstAvlFlg6 0 "FALSE" 1 "TRUE" ;
VAL_ 1189 PrkAsstONOFFCstAvlFlg5 0 "FALSE" 1 "TRUE" ;
VAL_ 1189 PrkAsstONOFFCstAvlFlg4 0 "FALSE" 1 "TRUE" ;
VAL_ 1189 PrkAsstONOFFCstAvlFlg3 0 "FALSE" 1 "TRUE" ;
VAL_ 1189 PrkAsstONOFFCstAvlFlg2 0 "FALSE" 1 "TRUE" ;
VAL_ 1189 PFASndSeltnCstAvlFlg2 0 "FALSE" 1 "TRUE" ;
VAL_ 1189 PFASndSeltnCstAvlFlg1 0 "FALSE" 1 "TRUE" ;
VAL_ 1189 LgslDiagStdCndMet 0 "FALSE" 1 "TRUE" ;
VAL_ 1189 PrkAsstTrHtchPsntCstAvlFlg7 0 "FALSE" 1 "TRUE" ;
VAL_ 1189 PrkAsstTrHtchPsntCstAvlFlg6 0 "FALSE" 1 "TRUE" ;
VAL_ 1189 PrkAsstTrHtchPsntCstAvlFlg5 0 "FALSE" 1 "TRUE" ;
VAL_ 1189 PrkAsstTrHtchPsntCstAvlFlg4 0 "FALSE" 1 "TRUE" ;
VAL_ 1189 PrkAsstTrHtchPsntCstAvlFlg3 0 "FALSE" 1 "TRUE" ;
VAL_ 1189 RnngBrdAutoDplyCstAvlFlg4 0 "FALSE" 1 "TRUE" ;
VAL_ 1189 RnngBrdAutoDplyCstAvlFlg3 0 "FALSE" 1 "TRUE" ;
VAL_ 1189 RnngBrdAutoDplyCstAvlFlg2 0 "FALSE" 1 "TRUE" ;
VAL_ 1189 RnngBrdAutoDplyCstAvlFlg1 0 "FALSE" 1 "TRUE" ;
VAL_ 1189 PFASndSeltnCstAvlFlg6 0 "FALSE" 1 "TRUE" ;
VAL_ 1189 PFASndSeltnCstAvlFlg5 0 "FALSE" 1 "TRUE" ;
VAL_ 1189 PFASndSeltnCstAvlFlg4 0 "FALSE" 1 "TRUE" ;
VAL_ 1189 PFASndSeltnCstAvlFlg3 0 "FALSE" 1 "TRUE" ;
VAL_ 1189 RnngBrdManDplyCstAvlFlg5 0 "FALSE" 1 "TRUE" ;
VAL_ 1189 RnngBrdManDplyCstAvlFlg4 0 "FALSE" 1 "TRUE" ;
VAL_ 1189 RnngBrdManDplyCstAvlFlg3 0 "FALSE" 1 "TRUE" ;
VAL_ 1189 RnngBrdManDplyCstAvlFlg2 0 "FALSE" 1 "TRUE" ;
VAL_ 1189 RnngBrdManDplyCstAvlFlg1 0 "FALSE" 1 "TRUE" ;
VAL_ 1189 RnngBrdAutoDplyCstAvlFlg7 0 "FALSE" 1 "TRUE" ;
VAL_ 1189 RnngBrdAutoDplyCstAvlFlg6 0 "FALSE" 1 "TRUE" ;
VAL_ 1189 RnngBrdAutoDplyCstAvlFlg5 0 "FALSE" 1 "TRUE" ;
VAL_ 1189 RrCrsTrfcAlrtCstAvlFlg6 0 "FALSE" 1 "TRUE" ;
VAL_ 1189 RrCrsTrfcAlrtCstAvlFlg5 0 "FALSE" 1 "TRUE" ;
VAL_ 1189 RrCrsTrfcAlrtCstAvlFlg4 0 "FALSE" 1 "TRUE" ;
VAL_ 1189 RrCrsTrfcAlrtCstAvlFlg3 0 "FALSE" 1 "TRUE" ;
VAL_ 1189 RrCrsTrfcAlrtCstAvlFlg2 0 "FALSE" 1 "TRUE" ;
VAL_ 1189 RrCrsTrfcAlrtCstAvlFlg1 0 "FALSE" 1 "TRUE" ;
VAL_ 1189 RnngBrdManDplyCstAvlFlg7 0 "FALSE" 1 "TRUE" ;
VAL_ 1189 RnngBrdManDplyCstAvlFlg6 0 "FALSE" 1 "TRUE" ;
VAL_ 1190 AutMemRclCstAvlFlg4 0 "FALSE" 1 "TRUE" ;
VAL_ 1190 AutMemRclCstAvlFlg3 0 "FALSE" 1 "TRUE" ;
VAL_ 1190 AutMemRclCstAvlFlg2 0 "FALSE" 1 "TRUE" ;
VAL_ 1190 AutMemRclCstAvlFlg1 0 "FALSE" 1 "TRUE" ;
VAL_ 1190 AdpLghtRspTypCstAvlFlg7 0 "FALSE" 1 "TRUE" ;
VAL_ 1190 AdpLghtRspTypCstAvlFlg6 0 "FALSE" 1 "TRUE" ;
VAL_ 1190 AdpLghtRspTypCstAvlFlg5 0 "FALSE" 1 "TRUE" ;
VAL_ 1190 AdpLghtRspTypCstAvlFlg4 0 "FALSE" 1 "TRUE" ;
VAL_ 1190 EsyExtCstAvlFlg4 0 "FALSE" 1 "TRUE" ;
VAL_ 1190 EsyExtCstAvlFlg3 0 "FALSE" 1 "TRUE" ;
VAL_ 1190 EsyExtCstAvlFlg2 0 "FALSE" 1 "TRUE" ;
VAL_ 1190 EsyExtCstAvlFlg1 0 "FALSE" 1 "TRUE" ;
VAL_ 1190 EngIdlAtv 0 "FALSE" 1 "TRUE" ;
VAL_ 1190 AutMemRclCstAvlFlg7 0 "FALSE" 1 "TRUE" ;
VAL_ 1190 AutMemRclCstAvlFlg6 0 "FALSE" 1 "TRUE" ;
VAL_ 1190 AutMemRclCstAvlFlg5 0 "FALSE" 1 "TRUE" ;
VAL_ 1190 FrntPCMRspTypCstAvlFlg4 0 "FALSE" 1 "TRUE" ;
VAL_ 1190 FrntPCMRspTypCstAvlFlg3 0 "FALSE" 1 "TRUE" ;
VAL_ 1190 FrntPCMRspTypCstAvlFlg2 0 "FALSE" 1 "TRUE" ;
VAL_ 1190 FrntPCMRspTypCstAvlFlg1 0 "FALSE" 1 "TRUE" ;
VAL_ 1190 FlToPsSwAtv 0 "FALSE" 1 "TRUE" ;
VAL_ 1190 EsyExtCstAvlFlg7 0 "FALSE" 1 "TRUE" ;
VAL_ 1190 EsyExtCstAvlFlg6 0 "FALSE" 1 "TRUE" ;
VAL_ 1190 EsyExtCstAvlFlg5 0 "FALSE" 1 "TRUE" ;
VAL_ 1190 FrwdImpMtgnOpSlctCstAvlFlg5 0 "FALSE" 1 "TRUE" ;
VAL_ 1190 FrwdImpMtgnOpSlctCstAvlFlg4 0 "FALSE" 1 "TRUE" ;
VAL_ 1190 FrwdImpMtgnOpSlctCstAvlFlg3 0 "FALSE" 1 "TRUE" ;
VAL_ 1190 FrwdImpMtgnOpSlctCstAvlFlg2 0 "FALSE" 1 "TRUE" ;
VAL_ 1190 FrwdImpMtgnOpSlctCstAvlFlg1 0 "FALSE" 1 "TRUE" ;
VAL_ 1190 FrntPCMRspTypCstAvlFlg7 0 "FALSE" 1 "TRUE" ;
VAL_ 1190 FrntPCMRspTypCstAvlFlg6 0 "FALSE" 1 "TRUE" ;
VAL_ 1190 FrntPCMRspTypCstAvlFlg5 0 "FALSE" 1 "TRUE" ;
VAL_ 1190 GlrFrHgBmRspTypCstAvlFlg6 0 "FALSE" 1 "TRUE" ;
VAL_ 1190 GlrFrHgBmRspTypCstAvlFlg5 0 "FALSE" 1 "TRUE" ;
VAL_ 1190 GlrFrHgBmRspTypCstAvlFlg4 0 "FALSE" 1 "TRUE" ;
VAL_ 1190 GlrFrHgBmRspTypCstAvlFlg3 0 "FALSE" 1 "TRUE" ;
VAL_ 1190 GlrFrHgBmRspTypCstAvlFlg2 0 "FALSE" 1 "TRUE" ;
VAL_ 1190 GlrFrHgBmRspTypCstAvlFlg1 0 "FALSE" 1 "TRUE" ;
VAL_ 1190 FrwdImpMtgnOpSlctCstAvlFlg7 0 "FALSE" 1 "TRUE" ;
VAL_ 1190 FrwdImpMtgnOpSlctCstAvlFlg6 0 "FALSE" 1 "TRUE" ;
VAL_ 1191 BarPrsAbs_Inv 0 "FALSE" 1 "TRUE" ;
VAL_ 1191 BatVlt_Inv 0 "FALSE" 1 "TRUE" ;
VAL_ 1191 DslExhFldLvlPct_Inv 0 "FALSE" 1 "TRUE" ;
VAL_ 1191 EngOilTmp_Inv 0 "FALSE" 1 "TRUE" ;
VAL_ 1191 RVC12VBatSOC_Inv 0 "FALSE" 1 "TRUE" ;
VAL_ 1191 SprTireSt 0 "Undetermined" 1 "No Spare Detected" 2 "Spare Detected" ;
VAL_ 1192 HiVltgBatMaxTemp_Inv 0 "FALSE" 1 "TRUE" ;
VAL_ 1192 OATP_OtsAirTmpCrValAuth_Inv 0 "FALSE" 1 "TRUE" ;
VAL_ 1192 PwrRrClsrCstAvlFlg4 0 "FALSE" 1 "TRUE" ;
VAL_ 1192 PwrRrClsrCstAvlFlg3 0 "FALSE" 1 "TRUE" ;
VAL_ 1192 PwrRrClsrCstAvlFlg2 0 "FALSE" 1 "TRUE" ;
VAL_ 1192 PwrRrClsrCstAvlFlg1 0 "FALSE" 1 "TRUE" ;
VAL_ 1192 PFASndSeltnCstSetAval 0 "FALSE" 1 "TRUE" ;
VAL_ 1192 PFASndSeltnCstAvlFlg7 0 "FALSE" 1 "TRUE" ;
VAL_ 1192 PwrRrClsrCstAvlFlg5 0 "FALSE" 1 "TRUE" ;
VAL_ 1192 ACRfHiSdFldPrs_Inv 0 "FALSE" 1 "TRUE" ;
VAL_ 1193 AdpLghtRspTypCstAvlFlg3 0 "FALSE" 1 "TRUE" ;
VAL_ 1193 AdpLghtRspTypCstAvlFlg2 0 "FALSE" 1 "TRUE" ;
VAL_ 1193 AdpLghtRspTypCstAvlFlg1 0 "FALSE" 1 "TRUE" ;
VAL_ 1193 ABSPr 0 "FALSE" 1 "TRUE" ;
VAL_ 1197 PMMiRAPStatus 0 "FALSE" 1 "TRUE" ;
VAL_ 1197 RrPCMRspTypCstStAvl 0 "FALSE" 1 "TRUE" ;
VAL_ 1197 RrPCMRspTypCstAvlFlg7 0 "FALSE" 1 "TRUE" ;
VAL_ 1197 RrPCMRspTypCstAvlFlg6 0 "FALSE" 1 "TRUE" ;
VAL_ 1197 RrPCMRspTypCstAvlFlg5 0 "FALSE" 1 "TRUE" ;
VAL_ 1197 RrPCMRspTypCstAvlFlg4 0 "FALSE" 1 "TRUE" ;
VAL_ 1197 RrPCMRspTypCstAvlFlg3 0 "FALSE" 1 "TRUE" ;
VAL_ 1197 RrPCMRspTypCstAvlFlg2 0 "FALSE" 1 "TRUE" ;
VAL_ 1197 RrPCMRspTypCstAvlFlg1 0 "FALSE" 1 "TRUE" ;
VAL_ 1197 PAMutSts 0 "No Action" 1 "Show Mute" 2 "Show Unmute" ;
VAL_ 1197 LDWCtrlAudAttnReqd 0 "FALSE" 1 "TRUE" ;
VAL_ 1197 LDWCtrlHndOff3ChmEvntStat 0 "NO_ACTION" 1 "ACTIVE" 2 "CANCEL_CHIME" ;
VAL_ 1197 StBltRmndrChmTyp2EvntStat 0 "No_Action" 1 "Active" 2 "Cancel_Chime" ;
VAL_ 1197 TrnLmpRtIO 0 "FALSE" 1 "TRUE" ;
VAL_ 1197 TrnLmpLftIO 0 "FALSE" 1 "TRUE" ;
VAL_ 1197 RetainedACCpwrStatus 0 "FALSE" 1 "TRUE" ;
VAL_ 1198 PrkAsstRrLftSdZn1ChEvntSt 0 "NO_ACTION" 1 "ACTIVE" 2 "CANCEL_CHIME" ;
VAL_ 1198 PrkAsstRrFrstRprtChEvntSt 0 "NO_ACTION" 1 "ACTIVE" 2 "CANCEL_CHIME" ;
VAL_ 1198 PrkAsstFrRgrChEvntSt 0 "NO_ACTION" 1 "ACTIVE" 2 "CANCEL_CHIME" ;
VAL_ 1198 PrkAsstFrRghtSdZn6ChEvntSt 0 "NO_ACTION" 1 "ACTIVE" 2 "CANCEL_CHIME" ;
VAL_ 1198 PrkAsstRrLftSdZn5ChEvntSt 0 "NO_ACTION" 1 "ACTIVE" 2 "CANCEL_CHIME" ;
VAL_ 1198 PrkAsstRrLftSdZn4ChEvntSt 0 "NO_ACTION" 1 "ACTIVE" 2 "CANCEL_CHIME" ;
VAL_ 1198 PrkAsstRrLftSdZn3ChEvntSt 0 "NO_ACTION" 1 "ACTIVE" 2 "CANCEL_CHIME" ;
VAL_ 1198 PrkAsstRrLftSdZn2ChEvntSt 0 "NO_ACTION" 1 "ACTIVE" 2 "CANCEL_CHIME" ;
VAL_ 1198 PrkAsstRrRghtSdZn3ChEvntSt 0 "NO_ACTION" 1 "ACTIVE" 2 "CANCEL_CHIME" ;
VAL_ 1198 PrkAsstRrRghtSdZn2ChEvntSt 0 "NO_ACTION" 1 "ACTIVE" 2 "CANCEL_CHIME" ;
VAL_ 1198 PrkAsstRrRghtSdZn1ChEvntSt 0 "NO_ACTION" 1 "ACTIVE" 2 "CANCEL_CHIME" ;
VAL_ 1198 PrkAsstRrLftSdZn6ChEvntSt 0 "NO_ACTION" 1 "ACTIVE" 2 "CANCEL_CHIME" ;
VAL_ 1198 PrkAsstRrRgrChEvntSt 0 "NO_ACTION" 1 "ACTIVE" 2 "CANCEL_CHIME" ;
VAL_ 1198 PrkAsstRrRghtSdZn6ChEvntSt 0 "NO_ACTION" 1 "ACTIVE" 2 "CANCEL_CHIME" ;
VAL_ 1198 PrkAsstRrRghtSdZn5ChEvntSt 0 "NO_ACTION" 1 "ACTIVE" 2 "CANCEL_CHIME" ;
VAL_ 1198 PrkAsstRrRghtSdZn4ChEvntSt 0 "NO_ACTION" 1 "ACTIVE" 2 "CANCEL_CHIME" ;
VAL_ 1198 RrCrsTrfcAlrtLftIndCtrl 0 "ON" 1 "OFF" 2 "FLASH" ;
VAL_ 1198 RlOvrDsblStsChgChmEvntStat 0 "No_Action" 1 "Active" 2 "Cancel_Chime" ;
VAL_ 1198 RIMIntCllnChmEvStat 0 "NO_ACTION" 1 "ACTIVE" 2 "CANCEL_CHIM" ;
VAL_ 1198 RIMBrkPlsChEvStat 0 "NO_ACTION" 1 "ACTIVE" 2 "CANCEL_CHIM" ;
VAL_ 1198 RrPCMChmEvntSt 0 "NO_ACTION" 1 "ACTIVE" 2 "CANCEL_CHIME" ;
VAL_ 1198 RrCrsTrfcAlrtRtSdChmEvntStat 0 "NO_ACTION" 1 "ACTIVE" 2 "CANCEL_CHIME" ;
VAL_ 1198 RrCrsTrfcAlrtRgIndCtrl 0 "ON" 1 "OFF" 2 "FLASH" ;
VAL_ 1198 RrCrsTrfcAlrtLtSdChmEvntStat 0 "NO_ACTION" 1 "ACTIVE" 2 "CANCEL_CHIME" ;
VAL_ 1198 DrHndlLRAuthReqd 0 "FALSE" 1 "TRUE" ;
VAL_ 1198 DrHndlLFAuthReqd 0 "FALSE" 1 "TRUE" ;
VAL_ 1198 FrtPedtrnClsnMtgnAudAttnReqd 0 "FALSE" 1 "TRUE" ;
VAL_ 1198 ACCGoNtfrChmEvntSt 0 "NO_ACTION" 1 "ACTIVE" ;
VAL_ 1198 TrffcLgtAsstWrnChmEvntStat 0 "NO_ACTION" 1 "ACTIVE" 2 "CANCEL_CHIME" 3 "RESERVED_1" ;
VAL_ 1198 StBltRmndrChmEvntStat 0 "NO_ACTION" 1 "ACTIVE" 2 "CANCEL_CHIME" ;
VAL_ 1198 HVACUsrCtlIntrctnDispReqd 0 "FALSE" 1 "TRUE" ;
VAL_ 1198 AirDflctrIndReq 0 "Off" 1 "Service" 2 "Stuck" ;
VAL_ 1198 RrClsrRelAuthReqd 0 "FALSE" 1 "TRUE" ;
VAL_ 1198 LnKpAsstTkStrIndOn 0 "FALSE" 1 "TRUE" ;
VAL_ 1198 FrtClsrRelAuthReqd 0 "FALSE" 1 "TRUE" ;
VAL_ 1198 DrHndlRRAuthReqd 0 "FALSE" 1 "TRUE" ;
VAL_ 1198 DrHndlRFAuthReqd 0 "FALSE" 1 "TRUE" ;
VAL_ 1199 MemStrTrplBeepChmEvStCoDrv 0 "No Action" 1 "Active" 2 "Cancel Chime" ;
VAL_ 1199 MemStrSnglBeepChmEvStRR 0 "No Action" 1 "Active" 2 "Cancel Chime" ;
VAL_ 1199 MemStrSnglBeepChmEvStLR 0 "No Action" 1 "Active" 2 "Cancel Chime" ;
VAL_ 1199 MemStrSnglBeepChmEvStDrv 0 "No Action" 1 "Active" 2 "Cancel Chime" ;
VAL_ 1199 PrkAsstFlChEvntSt 0 "NO_ACTION" 1 "ACTIVE" 2 "CANCEL_CHIME" ;
VAL_ 1199 MemStrTrplBeepChmEvStRR 0 "No Action" 1 "Active" 2 "Cancel Chime" ;
VAL_ 1199 MemStrTrplBeepChmEvStLR 0 "No Action" 1 "Active" 2 "Cancel Chime" ;
VAL_ 1199 MemStrTrplBeepChmEvStDrv 0 "No Action" 1 "Active" 2 "Cancel Chime" ;
VAL_ 1199 PrkAsstFllFrZn4ChEvntSt 0 "NO_ACTION" 1 "ACTIVE" 2 "CANCEL_CHIME" ;
VAL_ 1199 PrkAsstFllFrZn3ChEvntSt 0 "NO_ACTION" 1 "ACTIVE" 2 "CANCEL_CHIME" ;
VAL_ 1199 PrkAsstFllFrZn2ChEvntSt 0 "NO_ACTION" 1 "ACTIVE" 2 "CANCEL_CHIME" ;
VAL_ 1199 PrkAsstFllFrZn1ChEvntSt 0 "NO_ACTION" 1 "ACTIVE" 2 "CANCEL_CHIME" ;
VAL_ 1199 PrkAsstFllRrZn2ChEvntSt 0 "NO_ACTION" 1 "ACTIVE" 2 "CANCEL_CHIME" ;
VAL_ 1199 PrkAsstFllRrZn1ChEvntSt 0 "NO_ACTION" 1 "ACTIVE" 2 "CANCEL_CHIME" ;
VAL_ 1199 PrkAsstFllFrZn6ChEvntSt 0 "NO_ACTION" 1 "ACTIVE" 2 "CANCEL_CHIME" ;
VAL_ 1199 PrkAsstFllFrZn5ChEvntSt 0 "NO_ACTION" 1 "ACTIVE" 2 "CANCEL_CHIME" ;
VAL_ 1199 PrkAsstFllRrZn6ChEvntSt 0 "NO_ACTION" 1 "ACTIVE" 2 "CANCEL_CHIME" ;
VAL_ 1199 PrkAsstFllRrZn5ChEvntSt 0 "NO_ACTION" 1 "ACTIVE" 2 "CANCEL_CHIME" ;
VAL_ 1199 PrkAsstFllRrZn4ChEvntSt 0 "NO_ACTION" 1 "ACTIVE" 2 "CANCEL_CHIME" ;
VAL_ 1199 PrkAsstFllRrZn3ChEvntSt 0 "NO_ACTION" 1 "ACTIVE" 2 "CANCEL_CHIME" ;
VAL_ 1199 PrkAsstFrLftSdZn3ChEvntSt 0 "NO_ACTION" 1 "ACTIVE" 2 "CANCEL_CHIME" ;
VAL_ 1199 PrkAsstFrLftSdZn2ChEvntSt 0 "NO_ACTION" 1 "ACTIVE" 2 "CANCEL_CHIME" ;
VAL_ 1199 PrkAsstFrLftSdZn1ChEvntSt 0 "NO_ACTION" 1 "ACTIVE" 2 "CANCEL_CHIME" ;
VAL_ 1199 PrkAsstFrFrstRprtChEvntSt 0 "NO_ACTION" 1 "ACTIVE" 2 "CANCEL_CHIME" ;
VAL_ 1199 PrkAsstFrRghtSdZn1ChEvntSt 0 "NO_ACTION" 1 "ACTIVE" 2 "CANCEL_CHIME" ;
VAL_ 1199 PrkAsstFrLftSdZn6ChEvntSt 0 "NO_ACTION" 1 "ACTIVE" 2 "CANCEL_CHIME" ;
VAL_ 1199 PrkAsstFrLftSdZn5ChEvntSt 0 "NO_ACTION" 1 "ACTIVE" 2 "CANCEL_CHIME" ;
VAL_ 1199 PrkAsstFrLftSdZn4ChEvntSt 0 "NO_ACTION" 1 "ACTIVE" 2 "CANCEL_CHIME" ;
VAL_ 1199 PrkAsstFrRghtSdZn5ChEvntSt 0 "NO_ACTION" 1 "ACTIVE" 2 "CANCEL_CHIME" ;
VAL_ 1199 PrkAsstFrRghtSdZn4ChEvntSt 0 "NO_ACTION" 1 "ACTIVE" 2 "CANCEL_CHIME" ;
VAL_ 1199 PrkAsstFrRghtSdZn3ChEvntSt 0 "NO_ACTION" 1 "ACTIVE" 2 "CANCEL_CHIME" ;
VAL_ 1199 PrkAsstFrRghtSdZn2ChEvntSt 0 "NO_ACTION" 1 "ACTIVE" 2 "CANCEL_CHIME" ;
VAL_ 1200 FrwdClsnAlrtImntAlrtAudAttnReqd 0 "FALSE" 1 "TRUE" ;
VAL_ 1200 LKALnMrkgIndLt 0 "Off" 1 "White" 2 "Green" 3 "Amber" 4 "Amber Flashing" ;
VAL_ 1200 LKALnMrkgIndRt 0 "Off" 1 "White" 2 "Green" 3 "Amber" 4 "Amber Flashing" ;
VAL_ 1200 FrntPsSeatbeltStat 0 "Unknown" 1 "Unfastened" 2 "Fastened" ;
VAL_ 1200 FrntPsSeatbeltStat_Inv 0 "FALSE" 1 "TRUE" ;
VAL_ 1200 EPBSP_ElecPrkBrkApplStsAuth 0 "Unknown" 1 "Applied" 2 "Released" 3 "Dynamic Apply" 4 "In-Progress" ;
VAL_ 1200 RrPCMRspTypCstCrStVal 0 "SETTING_UNKNOWN" 1 "OFF" 2 "ALERT" 3 "ALERT_AND_BRAKE" 4 "RESERVED_4 RESERVED_5" 5 "RESERVED_6" 6 "RESERVED_7" ;
VAL_ 1200 ORIP_DrvrStBltStsAuth_Inv 0 "FALSE" 1 "TRUE" ;
VAL_ 1200 ORIP_DrvrStBltStsAuth 0 "Unknown" 1 "UnFastened" 2 "Fastened" ;
VAL_ 1200 LnDtWrnCntrlVsAlrtCmdGnc 0 "OFF" 1 "NOT READY TO ASSIST" 2 "READY TO ASSIST" 3 "ALERT" 4 "INTERVENTION" ;
VAL_ 1200 ElecPrkBrkCtnChiEveStat 0 "NO_ACTION" 1 "ACTIVE" 2 "CANCEL_CHIME" ;
VAL_ 1200 LDWCtrlHndOff1ChmEvntStat 0 "NO_ACTION" 1 "ACTIVE" 2 "CANCEL_CHIME" ;
VAL_ 1200 FrwdCllsnAlrtImAlrtDrIntAlrtChmE 0 "NO_ACTION" 1 "ACTIVE" 2 "CANCEL_CHIME" ;
VAL_ 1200 FrntPCMChmEvntStat 0 "NO_ACTION" 1 "ACTIVE" 2 "CANCEL_CHIME" ;
VAL_ 1200 ElecPrkBrkFixDurChiEveStat 0 "NO_ACTION" 1 "ACTIVE" 2 "CANCEL_CHIME" ;
VAL_ 1200 MemStrDblBeepChmEvStCoDrv 0 "No Action" 1 "Active" 2 "Cancel Chime" ;
VAL_ 1200 LDWCtrlRtHndSdChmEvntStat 0 "NO_ACTION" 1 "ACTIVE" 2 "CANCEL_CHIME" ;
VAL_ 1200 LDWCtrlLtHndSdChmEvntStat 0 "NO_ACTION" 1 "ACTIVE" 2 "CANCEL_CHIME" ;
VAL_ 1200 LDWCtrlHndOff2ChmEvntStat 0 "NO_ACTION" 1 "ACTIVE" 2 "CANCEL_CHIME" ;
VAL_ 1200 MemStrSnglBeepChmEvStCoDrv 0 "No Action" 1 "Active" 2 "Cancel Chime" ;
VAL_ 1200 MemStrDblBeepChmEvStRR 0 "No Action" 1 "Active" 2 "Cancel Chime" ;
VAL_ 1200 MemStrDblBeepChmEvStLR 0 "No Action" 1 "Active" 2 "Cancel Chime" ;
VAL_ 1200 MemStrDblBeepChmEvStDrv 0 "No Action" 1 "Active" 2 "Cancel Chime" ;
VAL_ 1201 ELWWIP_WprFrtFtrReqAuth 0 "Wiper Front Stop" 1 "Wiper Front Crank Suspend" 2 "Wiper Front Depressed Park" 3 "Wiper Front Park" 4 "Wiper Front Winter Park" 5 "Wiper Front Service Park" 6 "Wiper Front Intermittent 5" 7 "Wiper Front Intermittent 4" 8 "Wiper Front Intermittent 3" 9 "Wiper Front Intermittent 2" 10 "Wiper Front Intermittent 1" 11 "Wiper Front Low Wipe" 12 "Wiper Front High Wipe" ;
VAL_ 1201 ELWWIP_RvrsLmpCmdAuth 0 "Off" 1 "On" 2 "Flashing" ;
VAL_ 1201 ELWWIP_TrlrRvrsLmpsCmdAuth 0 "Off" 1 "On" 2 "Flashing" ;
VAL_ 1201 ELWWIP_CHMSLCmdAuth 0 "No_Action" 1 "Off" 2 "On" 3 "Emergency_Brake_Flashing" ;
VAL_ 1201 ELWWIP_BrkLmpRtCmdAuth 0 "No_Action" 1 "Off" 2 "On" 3 "Emergency_Brake_Flashing" 4 "Police_Flashing" ;
VAL_ 1201 ELWWIP_BrkLmpLtCmdAuth 0 "No_Action" 1 "Off" 2 "On" 3 "Emergency_Brake_Flashing" 4 "Police_Flashing" ;
VAL_ 1201 APACR_FaildChmEvntStat 0 "NO_ACTION" 1 "ACTIVE" 2 "CANCEL_CHIME" ;
VAL_ 1201 APACR_StopChmEvntStat 0 "NO_ACTION" 1 "ACTIVE" 2 "CANCEL_CHIME" ;
VAL_ 1201 APACR_CmpltChmEvntStat 0 "NO_ACTION" 1 "ACTIVE" 2 "CANCEL_CHIME" ;
VAL_ 1201 APACR_CncldChmEvntStat 0 "NO_ACTION" 1 "ACTIVE" 2 "CANCEL_CHIME" ;
VAL_ 1201 APACR_SptFndChmEvntStat 0 "NO_ACTION" 1 "ACTIVE" 2 "CANCEL_CHIME" ;
VAL_ 1201 LnCntrWrnIndRqst 0 "No Indication" 1 "Can not See Lanes" 2 "Tight Curve" 3 "Freeway Ends" 4 "Construction" 5 "Excessive Speed" 6 "Vehicles Too Close" 7 "Canceled Take Steering" 8 "Can not See Eyes" 9 "Due to Weather" 10 "Take Steering" 11 "Take Vehicle Control" 12 "Service Driver Assist System" 13 "Lane Following Locked Out" 14 "TJA Max Speed Reached" 15 "TJA Available" 16 "TJA Active" ;
VAL_ 1201 UpftrRrAprchPrtctnChmEvntStat 0 "No Action" 1 "Active" 2 "Cancel Chime" ;
VAL_ 1219 TrlLfTrInLtFld 0 "FALSE" 1 "TRUE" ;
VAL_ 1219 TnDrvRIMOFFUnvIndOn 0 "FALSE" 1 "TRUE" ;
VAL_ 1219 StNtLtchdIO 0 "FALSE" 1 "TRUE" ;
VAL_ 1219 SrvPedtrnProtSysIO 0 "FALSE" 1 "TRUE" ;
VAL_ 1219 SftTpVltLwIO 0 "FALSE" 1 "TRUE" ;
VAL_ 1219 SftTpVehOvSpdIO 0 "FALSE" 1 "TRUE" ;
VAL_ 1219 SftTpTmpLwIO 0 "FALSE" 1 "TRUE" ;
VAL_ 1219 SftTpStrIO 0 "FALSE" 1 "TRUE" ;
VAL_ 1219 TrlrTlLtFld 0 "FALSE" 1 "TRUE" ;
VAL_ 1219 RrVirtBmpAutoBrkRelIndOn 0 "FALSE" 1 "TRUE" ;
VAL_ 1219 TrlrRvrsLmpOtgIndOn 0 "FALSE" 1 "TRUE" ;
VAL_ 1219 TrlrRtTrInLtFld 0 "FALSE" 1 "TRUE" ;
VAL_ 1219 TrlrFgLtFld 0 "FALSE" 1 "TRUE" ;
VAL_ 1219 TrlrDisconndIndOn 0 "FALSE" 1 "TRUE" ;
VAL_ 1219 TrlrBrkLtFld 0 "FALSE" 1 "TRUE" ;
VAL_ 1219 TrnsNEmsRltMlfActv 0 "FALSE" 1 "TRUE" ;
VAL_ 1219 TrnsEmsRltMlfAtv 0 "FALSE" 1 "TRUE" ;
VAL_ 1219 DM2Denied 0 "FALSE" 1 "TRUE" ;
VAL_ 1219 TrnLmpRrRtOtgIndOn 0 "FALSE" 1 "TRUE" ;
VAL_ 1219 TrnLmpRrLtOtgIndOn 0 "FALSE" 1 "TRUE" ;
VAL_ 1219 DM1Denied 0 "FALSE" 1 "TRUE" ;
VAL_ 1219 TrnLmpFrtRtOtgIndOn 0 "FALSE" 1 "TRUE" ;
VAL_ 1219 TrnLmpFrtLtOtgIndOn 0 "FALSE" 1 "TRUE" ;
VAL_ 1219 RdHgtStatIndReq 0 "Nominal Trim" 1 "Raised 2" 2 "Raised 1" 3 "Lowered 1" 4 "Lowered 2" 5 "Cargo/Trailer" 6 "Entry/Exit" 7 "Alignment Mode" 8 "Service Mode" 9 "Entry/Exit Pending" 10 "Safety Lowered" ;
VAL_ 1219 SftTpFlrIO 0 "FALSE" 1 "TRUE" ;
VAL_ 1219 ACCSysSlctdMd 0 "Cruise Control Mode Switching Not Supported" 1 "Adaptive Cruise Control" 2 "Enhanced Cruise Control" ;
VAL_ 1219 BkupPwrMdStrtStpIgntSwtchPrsdRpt 0 "FALSE" 1 "TRUE" ;
VAL_ 1219 VltSwAtvIO 0 "FALSE" 1 "TRUE" ;
VAL_ 1219 ValetModeActive 0 "FALSE" 1 "TRUE" ;
VAL_ 1219 TrnsOilChngIO 0 "FALSE" 1 "TRUE" ;
VAL_ 1219 RdHgtWrn2IndReq 0 "No Indication" 1 "Auto Lowering" 2 "Suspension Low-Wait" 3 "Suspension Low-Caution" 4 "Suspension High" 5 "Safety Lowered" 6 "Raised 2 Inhibit 4WD" 7 "Raised 2 Inhibit Speed" 8 "Raised Inhibit Speed" 9 "Cargo Inhibit Speed" 10 "Entry Exit Pending Speed" 11 "Raised 2 Inhibit Crawl" 12 "Object Detected" 13 "SuspensionOverloaded" 14 "Lowered Inhibit DMC" ;
VAL_ 1219 LnchCtlWhlSlSts 0 "No Action" 1 "Five Percent" 2 "Five And A Half Percent" 3 "Six Percent" 4 "Six And A Half Percent" 5 "Seven Percent" 6 "Seven And A Half Percent" 7 "Eight Percent" 8 "Eight And A Half Percent" 9 "Nine Percent" 10 "Nine And A Half Percent" 11 "Ten Percent" 12 "Ten And A Half Percent" 13 "Eleven Percent" 14 "Eleven And a Half Percent" 15 "Twelve Percent" 16 "Twelve And A Half Percent" 17 "Thirteen Percent" 18 "Thirteen And A Half Percent" 19 "Fourteen Percent" 20 "Fourteen And A Half Percent" 21 "Fifteen Percent" ;
VAL_ 1219 LnchCtlEngRPMSts 0 "No Action" 1 "800" 2 "900" 3 "1000" 4 "1100" 5 "1200" 6 "1300" 7 "1400" 8 "1500" 9 "1600" 10 "1700" 11 "1800" 12 "1900" 13 "2000" 14 "2100" 15 "2200" 16 "2300" 17 "2400" 18 "2500" 19 "2600" 20 "2700" 21 "2800" 22 "2900" 23 "3000" 24 "3100" 25 "3200" 26 "3300" 27 "3400" 28 "3500" 29 "3600" 30 "3700" 31 "3800" 32 "3900" 33 "4000" 34 "FlexibleRPM 1" 35 "FlexibleRPM 2" 36 "FlexibleRPM 3" 37 "FlexibleRPM 4" 38 "FlexibleRPM 5" ;
VAL_ 1220 LogisticModeStatus 0 "Off" 1 "Plant" 2 "Transport Mode" 3 "Storage Mode" ;
VAL_ 1220 LnCntrEsclnSts 0 "None" 1 "Driver Not Looking to Roadway" 2 "Limited Condition" 3 "System Faulted" ;
VAL_ 1220 InvsblTrlrOprtlSts 0 "Available" 1 "Degraded" 2 "Unavailable" 3 "Unknown" ;
VAL_ 1220 GlrFrHiBmSts 0 "OFF" 1 "AHBA" 2 "GFHB" ;
VAL_ 1220 CkBrkLmpsIndOn 0 "FALSE" 1 "TRUE" ;
VAL_ 1220 CIBAutoBrkRelIndOn 0 "FALSE" 1 "TRUE" ;
VAL_ 1220 BrkLtsAtv 0 "FALSE" 1 "TRUE" ;
VAL_ 1220 AutoHgBmCtrlIO 0 "FALSE" 1 "TRUE" ;
VAL_ 1220 PAVisObjIndStatReq 0 "No Action" 1 "Driver Tube Front" 2 "Driver Tube Rear" 3 "Full Active" ;
VAL_ 1220 ClsTrnkLidIO 0 "FALSE" 1 "TRUE" ;
VAL_ 1220 CkSoftTpIO 0 "FALSE" 1 "TRUE" ;
VAL_ 1220 CkRrPrkLmpIndOn 0 "FALSE" 1 "TRUE" ;
VAL_ 1220 CkLoBmsIndOn 0 "FALSE" 1 "TRUE" ;
VAL_ 1220 CkFrtPrkLmpsIndOn 0 "FALSE" 1 "TRUE" ;
VAL_ 1220 CkFgLmpsIndOn 0 "FALSE" 1 "TRUE" ;
VAL_ 1220 CkDyTmRnngLmpsIndOn 0 "FALSE" 1 "TRUE" ;
VAL_ 1220 CkCrnrLmpsIndOn 0 "FALSE" 1 "TRUE" ;
VAL_ 1220 FrntPsMtzdStBltFldIndOn 0 "FALSE" 1 "TRUE" ;
VAL_ 1220 ESCLTrntheStrWheelWhlStrtgIO 0 "FALSE" 1 "TRUE" ;
VAL_ 1220 DrvStBltRmIndOn 0 "FALSE" 1 "TRUE" ;
VAL_ 1220 DrvShftCntrlReqDndIO 0 "FALSE" 1 "TRUE" ;
VAL_ 1220 DrMtzdStBltUnIndOn 0 "FALSE" 1 "TRUE" ;
VAL_ 1220 DrMtzdStBltFldIndOn 0 "FALSE" 1 "TRUE" ;
VAL_ 1220 DRLAct 0 "FALSE" 1 "TRUE" ;
VAL_ 1220 CrsCntAtv 0 "FALSE" 1 "TRUE" ;
VAL_ 1220 LicLpOtIO 0 "FALSE" 1 "TRUE" ;
VAL_ 1220 LSCMBAutoBrkRlsIndOn 0 "FALSE" 1 "TRUE" ;
VAL_ 1220 HiBmOtgIndOn 0 "FALSE" 1 "TRUE" ;
VAL_ 1220 GrdBrkgAct 0 "FALSE" 1 "TRUE" ;
VAL_ 1220 FrwdVhHdwyAlrtIndOn 0 "FALSE" 1 "TRUE" ;
VAL_ 1220 EngFuelInjnSysFltIndOn 0 "FALSE" 1 "TRUE" ;
VAL_ 1220 FrntPsStbltRmIndOn 0 "FALSE" 1 "TRUE" ;
VAL_ 1220 FrntPsMtzdStBltUnIndOn 0 "FALSE" 1 "TRUE" ;
VAL_ 1220 RIMOFFIndOn 0 "FALSE" 1 "TRUE" ;
VAL_ 1220 PrkBrkSwAtv 0 "FALSE" 1 "TRUE" ;
VAL_ 1220 PedtrnProtSysDpl 0 "FALSE" 1 "TRUE" ;
VAL_ 1220 NoSDCrdPrIndOn 0 "FALSE" 1 "TRUE" ;
VAL_ 1220 MovblTpServRqrdIO 0 "FALSE" 1 "TRUE" ;
VAL_ 1220 MovblTpNormzRqrdIO 0 "FALSE" 1 "TRUE" ;
VAL_ 1220 LnCntrMisuseCond 0 "FALSE" 1 "TRUE" ;
VAL_ 1220 LnCntrDrvAwrIndOn 0 "FALSE" 1 "TRUE" ;
VAL_ 1220 RvLpOtIO 0 "FALSE" 1 "TRUE" ;
VAL_ 1220 RstrntDplyIndOn 0 "FALSE" 1 "TRUE" ;
VAL_ 1220 RrFgLpOtIO 0 "FALSE" 1 "TRUE" ;
VAL_ 1220 RrCrsTrfcAlrtOffIndOn 0 "FALSE" 1 "TRUE" ;
VAL_ 1220 BrkOvrhtdIndOn 0 "FALSE" 1 "TRUE" ;
VAL_ 1220 RearPsStbltVisIndMd 0 "FALSE" 1 "TRUE" ;
VAL_ 1220 RIMUnIndOn 0 "FALSE" 1 "TRUE" ;
VAL_ 1220 RIMONIndOn 0 "FALSE" 1 "TRUE" ;
VAL_ 1220 SftTpPlsDnWrngIO 0 "FALSE" 1 "TRUE" ;
VAL_ 1220 SftTpPlsDnSrtdIO 0 "FALSE" 1 "TRUE" ;
VAL_ 1220 SftTpMchnOvhtIO 0 "FALSE" 1 "TRUE" ;
VAL_ 1220 SftTpLtcIO 0 "FALSE" 1 "TRUE" ;
VAL_ 1220 ServHdlmpsIndOn 0 "FALSE" 1 "TRUE" ;
VAL_ 1220 SerRideSysIO 0 "FALSE" 1 "TRUE" ;
VAL_ 1220 SDCrdFllIndOn 0 "FALSE" 1 "TRUE" ;
VAL_ 1220 SDCrdErrIndOn 0 "FALSE" 1 "TRUE" ;
VAL_ 1221 LnchCtlModeSts 0 "Disable" 1 "General" 2 "General Custom" 3 "High Traction" 4 "High Traction Custom" 5 "Line Lock" 6 "Line lock Press Brake" 7 "Line Lock Release Brake" ;
VAL_ 1221 RdHgtMvmtIndReq 0 "No Movement" 1 "Raising to 2" 2 "Raising" 3 "Lowering" 4 "Cargo Loading" ;
VAL_ 1221 RdHgtAtLocIndReq 0 "No Indication" 1 "Stored" 2 "Cleared" 3 "All Cleared" 4 "Not Saved" 5 "Unknown" ;
VAL_ 1221 TrlrMirVidEnblCstCurrSetVal 0 "Setting_Unknown" 1 "Off" 2 "On" 3 "Reserved_3" 4 "Reserved_4" 5 "Reserved_5" 6 "Reserved_6" 7 "Reserved_7" ;
VAL_ 1221 PARgn 0 "Europe" 1 "North America" ;
VAL_ 1221 RdHgtWrn1IndReq 0 "No indication" 1 "Front Lift Inhibited" 2 "Leveling Inhibited" 3 "Front Lift Unavailable" 4 "Leveling Unavailable" 5 "Front Lift Faulted" 6 "Leveling Faulted" ;
VAL_ 1221 WndPstnStsLF 0 "Denormalized" 1 "Fully Closed" 2 "Less Than Position A" 3 "Position A" 4 "Greater Than A but less than Position C" 5 "Position C" 6 "Greater than Position C but less than Fully open" 7 "Fully Open" ;
VAL_ 1221 TrnsSftMdSt 0 "No Override Mode" 1 "Performance Mode" 2 "Lift-Foot Cornering Mode" 3 "Automatic Grade Braking Mode" ;
VAL_ 1221 WndPstnStsRR 0 "Denormalized" 1 "Fully Closed" 2 "Less Than Position A" 3 "Position A" 4 "Greater Than A but less than Position C" 5 "Position C" 6 "Greater than Position C but less than Fully open" 7 "Fully Open" ;
VAL_ 1221 WndPstnStsRF 0 "Denormalized" 1 "Fully Closed" 2 "Less Than Position A" 3 "Position A" 4 "Greater Than A but less than Position C" 5 "Position C" 6 "Greater than Position C but less than Fully open" 7 "Fully Open" ;
VAL_ 1221 WndPstnStsLR 0 "Denormalized" 1 "Fully Closed" 2 "Less Than Position A" 3 "Position A" 4 "Greater Than A but less than Position C" 5 "Position C" 6 "Greater than Position C but less than Fully open" 7 "Fully Open" ;
VAL_ 1221 CltTpTrvAchv_Inv 0 "FALSE" 1 "TRUE" ;
VAL_ 1221 BrkPadLifeFrtDistWrnIndReq 0 "No Action" 1 "Low" 2 "Display Distance" ;
VAL_ 1221 AdvdFrtLgtSysIndReq 0 "NO INDICATION" 1 "FAILURE INDICATION" 2 "TOURIST MODE SETTING CHANGED" 3 "TOURIST MODE REMINDER" ;
VAL_ 1221 ACCAutoStSpStat 0 "No_Set_Speed_Change" 1 "Proposed_Speed_Limit_Change" 2 "Accepted_Speed_Limit_Change" 3 "Declined_Speed_Limit_Change" ;
VAL_ 1221 CmdThrdRwCtStbtVisInd 0 "No Indication" 1 "Unbuckled Indication" 2 "Buckled Indication" 3 "Unbuckled Flashing Indication" ;
VAL_ 1221 CmdSndRwRtStbtVisInd 0 "No Indication" 1 "Unbuckled Indication" 2 "Buckled Indication" 3 "Unbuckled Flashing Indication" ;
VAL_ 1221 CmdSndRwLtStbtVisInd 0 "No Indication" 1 "Unbuckled Indication" 2 "Buckled Indication" 3 "Unbuckled Flashing Indication" ;
VAL_ 1221 CmdSndRwCtStbtVisInd 0 "No Indication" 1 "Unbuckled Indication" 2 "Buckled Indication" 3 "Unbuckled Flashing Indication" ;
VAL_ 1221 CltTpTrvAchv 0 "FALSE" 1 "TRUE" ;
VAL_ 1221 DrLckStsLR 0 "Unknown" 1 "Locked" 2 "Unlocked" ;
VAL_ 1221 DrLckStsLF 0 "Unknown" 1 "Locked" 2 "Unlocked" ;
VAL_ 1221 CmdThrdRwRtStbtVisInd 0 "No Indication" 1 "Unbuckled Indication" 2 "Buckled Indication" 3 "Unbuckled Flashing Indication" ;
VAL_ 1221 CmdThrdRwLtStbtVisInd 0 "No Indication" 1 "Unbuckled Indication" 2 "Buckled Indication" 3 "Unbuckled Flashing Indication" ;
VAL_ 1221 AutoBmSlctAllwd 0 "FALSE" 1 "TRUE" ;
VAL_ 1221 DrSlctdSpdLmtAutMdSpdLmtStat 0 "No Set Speed Change" 1 "Proposed Speed Limit Change" 2 "Accepted Speed Limit Change" 3 "Declined Speed Limit Change" ;
VAL_ 1221 DrLckStsRR 0 "Unknown" 1 "Locked" 2 "Unlocked" ;
VAL_ 1221 DrLckStsRF 0 "Unknown" 1 "Locked" 2 "Unlocked" ;
VAL_ 1222 PAIM_FaildIndOn 0 "FALSE" 1 "TRUE" ;
VAL_ 1222 PAIM_RrOffIndOn 0 "FALSE" 1 "TRUE" ;
VAL_ 1222 PAIM_DsbldIndOn 0 "FALSE" 1 "TRUE" ;
VAL_ 1222 PAIM_TeenDrvrPAOffUnvIndOn 0 "FALSE" 1 "TRUE" ;
VAL_ 1222 PAIM_FrtOffIndOn 0 "FALSE" 1 "TRUE" ;
VAL_ 1222 PAIM_SnsrDstbdIndOn 0 "FALSE" 1 "TRUE" ;
VAL_ 1222 PAIM_SnsrBlckdIndOn 0 "FALSE" 1 "TRUE" ;
VAL_ 1222 PAIM_SnsrClnIndOn 0 "FALSE" 1 "TRUE" ;
VAL_ 1222 eLSDActrTrqPctg_Inv 0 "FALSE" 1 "TRUE" ;
VAL_ 1222 PAIM_OffIndOn 0 "FALSE" 1 "TRUE" ;
VAL_ 1222 FourWhlDrvWrnIndReq 0 "No Action" 1 "No Indication" 2 "For 4WD Low Shift Transmission To Neutral" 3 "To Exit 4WD Low Shift Transmission to Neutral" 4 "For 4WD Low Reduce Speed" 5 "To Exit 4WD Low Reduce Speed" 6 "Reminder Vehicle Still In 4WD Low" 7 "4WD Shift in Progress" 8 "4WD Shift Not Allowed Engine Warming Up" 9 "4WD Shift Not Allowed Mismatched Tire" 10 "4WD Shift Not Allowed In Park" 11 "Apply Brake For 4WD Shift" 12 "No 4WD Shifts Allowed" 13 "Reduce Speed For 4WD Shift" 14 "Turn off Engine for 4WD Shift" 15 "For 4WD Shift Transmission Neutral" ;
VAL_ 1222 EnrgMgtLdShdRq 0 "No Load Shedding" 1 "Load Shed Level 1" 2 "Load Shed Level 2" 3 "Load Shed Level 3" 4 "Load Shed Level 4" ;
VAL_ 1222 BrkSysHillStrtAsstStat 0 "Inactive" 1 "Brake Pressure Hold" 2 "Normal Pressure Decay" 3 "Drive-off Pressure Decay" 4 "Reserved_4" 5 "Reserved_5" 6 "Reserved_6" 7 "Reserved_7" ;
VAL_ 1222 FrntPsStbltRmIndReq 0 "OFF" 1 "ON" 2 "0.5_Hz" 3 "1_Hz" 4 "2_Hz" 5 "4_Hz" 6 "RESERVED_1" 7 "RESERVED_2" ;
VAL_ 1222 CrgBedVwAutoLgtCstCurrSetVal 0 "Setting_Unknown" 1 "Off" 2 "On" 3 "Reserved_3" 4 "Reserved_4" 5 "Reserved_5" 6 "Reserved_6" 7 "Reserved_7" ;
VAL_ 1222 CnvtBkWndPstnSts 0 "Denormalized" 1 "Fully Closed" 2 "Less Than Position A" 3 "Position A" 4 "Greater Than A but less than Position C" 5 "Position C" 6 "Greater than Position C but less than Fully open" 7 "Fully Open" ;
VAL_ 1222 CTDStat 0 "OFF" 1 "ARMED" 2 "DISARMED" 3 "ALARM ACTIVE" 4 "ARMING DELAY" 5 "POST ALARM DELAY" ;
VAL_ 1222 FrntPsStBltRmOccStat 0 "UNKNOWN" 1 "EMPTY" 2 "OCCUPIED" ;
VAL_ 1222 FrntPsStBltRmOccStat_Inv 0 "FALSE" 1 "TRUE" ;
VAL_ 1222 EngAirFiltMonSts 0 "OK" 1 "Replace Air Filter Soon" 2 "Replace Air Filter Now" 3 "Fault Present" 4 "Disabled" 5 "No Action" ;
VAL_ 1222 LnDtWrnCntrlFtrSt 0 "OFF" 1 "STANDBY" 2 "READY TO ASSIST" 3 "FAILED" 4 "ALERT AND CONTROL" ;
VAL_ 1222 FrwdVhImAlrtIndRqst 0 "OFF" 1 "ON" 2 "0.5_Hz" 3 "1_Hz" 4 "2_Hz" 5 "4_Hz" 6 "RESERVED_1" 7 "RESERVED_2" ;
VAL_ 1222 AirbgStIndOn 0 "FALSE" 1 "TRUE" ;
VAL_ 1222 PrkAsstStat 0 "OFF" 1 "STANDBY" 2 "DISABLED" 3 "FAILED" 4 "FRONT_REAR_ACTIVE" 5 "REAR_ACTIVE" 6 "FRONT_ACTIVE" 7 "UNKNOWN" ;
VAL_ 1222 NghtVsnSysStat 0 "UNKNOWN" 1 "INITIALIZING" 2 "INACTIVE" 3 "ACTIVE" 4 "NEEDS SERVICE" 5 "NOT DARK" 6 "TEMPORARILY UNAVAILABLE" 7 "NEEDS HEADLIGHTS" ;
VAL_ 1223 FPARS_RtCntr 0 "OFF" 1 "FAILED" 2 "BLOCKED" 3 "ATTACHED_OBJECT" 4 "NO_OBJECT" 5 "ZONE_1" 6 "ZONE_2" 7 "ZONE_3" 8 "ZONE_4" 9 "ZONE_5" 10 "ZONE_6" 11 "OFF_NO_FAULT" 12 "RESERVED_1" 13 "RESERVED_2" 14 "RESERVED_3" ;
VAL_ 1223 FPARS_Lt 0 "OFF" 1 "FAILED" 2 "BLOCKED" 3 "ATTACHED_OBJECT" 4 "NO_OBJECT" 5 "ZONE_1" 6 "ZONE_2" 7 "ZONE_3" 8 "ZONE_4" 9 "ZONE_5" 10 "ZONE_6" 11 "OFF_NO_FAULT" 12 "RESERVED_1" 13 "RESERVED_2" 14 "RESERVED_3" ;
VAL_ 1223 FPARS_Rt 0 "OFF" 1 "FAILED" 2 "BLOCKED" 3 "ATTACHED_OBJECT" 4 "NO_OBJECT" 5 "ZONE_1" 6 "ZONE_2" 7 "ZONE_3" 8 "ZONE_4" 9 "ZONE_5" 10 "ZONE_6" 11 "OFF_NO_FAULT" 12 "RESERVED_1" 13 "RESERVED_2" 14 "RESERVED_3" ;
VAL_ 1223 FPARS_LtCntr 0 "OFF" 1 "FAILED" 2 "BLOCKED" 3 "ATTACHED_OBJECT" 4 "NO_OBJECT" 5 "ZONE_1" 6 "ZONE_2" 7 "ZONE_3" 8 "ZONE_4" 9 "ZONE_5" 10 "ZONE_6" 11 "OFF_NO_FAULT" 12 "RESERVED_1" 13 "RESERVED_2" 14 "RESERVED_3" ;
VAL_ 1223 FPLTLI_PrkLmpLtCmd 0 "No Action" 1 "Off" 2 "On" 3 "Ramp On" 4 "Ramp Off" ;
VAL_ 1223 FPLTLI_AuxPrkLmpLtCmd 0 "No Action" 1 "Off" 2 "On" 3 "Ramp On" 4 "Ramp Off" ;
VAL_ 1223 FPLTLI_PrkLmpRtCmd 0 "No Action" 1 "Off" 2 "On" 3 "Ramp On" 4 "Ramp Off" ;
VAL_ 1223 FPLTLI_AuxPrkLmpRtCmd 0 "No Action" 1 "Off" 2 "On" 3 "Ramp On" 4 "Ramp Off" ;
VAL_ 1223 CrwlModeDndRsnIndReq 0 "No Indication" 1 "Unavailable" 2 "Brakes Overtemp" 3 "Shift to 4 High" 4 "Reduce Speed" ;
VAL_ 1223 BSISP_ETRSHydrlcBrkgStsAuth 0 "Not Active" 1 "Active" 2 "Failed" ;
VAL_ 1223 BSISP_ESCActvAuth 0 "FALSE" 1 "TRUE" ;
VAL_ 1223 BSISP_TCSFaildAuth 0 "FALSE" 1 "TRUE" ;
VAL_ 1223 MaxChrgSts 0 "Not Active" 1 "Active" 2 "Not Available" ;
VAL_ 1223 ArtcldRnngBrdSt 0 "No Action" 1 "Resume Normal Operation" 2 "Running Boards Deployed" 3 "Running Boards Stowed" 4 "Running Boards Cargo Access" 5 "Running Boards Inhibited" 6 "Running Boards Could Not Extend" ;
VAL_ 1223 BSISP_ESCSysStsAuth 0 "Normal Operation" 1 "Failed" 2 "Initializing" 3 "Enhanced Operation" 4 "Driver Disable" ;
VAL_ 1223 BSISP_TCSActvAuth 0 "FALSE" 1 "TRUE" ;
VAL_ 1223 BSISP_TCSDrvrIntntAuth 0 "Disabled" 1 "Enabled" ;
VAL_ 1224 BVSCRP_CPSAxlTrqCmdLimStsAuth 0 "Request Not Limited" 1 "Request Value Limited to Minimum" 2 "Request Value Limited to Maximum" 3 "Request Rate Limited" ;
VAL_ 1224 BVSCRP_ACCAxlTrqCmdReqStsAuth 0 "No Request" 1 "Request Honored" 2 "Lost Arbitration" 3 "Request Denied" 4 "Request Suspended Till Driver Input" ;
VAL_ 1224 BVSCRP_ACCAxlTrqCmdLimStsAuth 0 "Request Not Limited" 1 "Request Value Limited Minimum" 2 "Request Value Limited Maximum" 3 "Request Rate Limited" ;
VAL_ 1224 BVSCRP_CruzCtlEnbldAuth 0 "FALSE" 1 "TRUE" ;
VAL_ 1224 BVSCRP_CPSAxlTrqCmdReqStsAuth 0 "No Request" 1 "Request Honored" 2 "Lost Arbitration" 3 "Serial Data Failure Temporary" 4 "Serial Data Failure Permanent" 5 "Control System Failure Temporary" 6 "Control System Failure Permanent" ;
VAL_ 1224 BVSCRP_CltchPdlActPosAuth_Inv 0 "FALSE" 1 "TRUE" ;
VAL_ 1224 TCTPIR_DrvrNtfn 0 "No Action" 1 "No Indication" 2 "Warm" 3 "Increase Speed or Apply Brake" 4 "Ready for Drive Away" 5 "Please Wait" 6 "Apply and Hold Brake" 7 "Cool Down" 8 "Creep Disabled" ;
VAL_ 1224 RTPP_TirePrsRRAuth_Inv 0 "FALSE" 1 "TRUE" ;
VAL_ 1224 RTPP_TirePrsLRAuth_Inv 0 "FALSE" 1 "TRUE" ;
VAL_ 1224 AdptCrsCntrlEngd 0 "FALSE" 1 "TRUE" ;
VAL_ 1224 SGI_ServStSysIndOn 0 "FALSE" 1 "TRUE" ;
VAL_ 1225 DrvStBltRmIndReq 0 "OFF" 1 "ON" 2 "0.5_Hz" 3 "1_Hz" 4 "2_Hz" 5 "4_Hz" 6 "RESERVED_1" 7 "RESERVED_2" ;
VAL_ 1225 AirbgStsIndReq 0 "OFF" 1 "ON" 2 "0.5_Hz" 3 "1_Hz" 4 "2_Hz" 5 "4_Hz" 6 "RESERVED_1" 7 "RESERVED_2" ;
VAL_ 1228 AutoEmrgBrkgDsbldIndOn 0 "FALSE" 1 "TRUE" ;
VAL_ 1230 PTCrnkAct 0 "FALSE" 1 "TRUE" ;
VAL_ 1230 DrvShftCntrlTrgtGr 0 "Unknown" 1 "First Gear" 2 "Second Gear" 3 "Third Gear" 4 "Fourth Gear" 5 "Fifth Gear" 6 "Sixth Gear" 7 "Seventh Gear" 8 "Eighth Gear" 9 "Ninth Gear" 10 "Tenth Gear" ;
VAL_ 1240 DrvrAlrtTypCstAvlFlg3 0 "FALSE" 1 "TRUE" ;
VAL_ 1240 DrvrAlrtTypCstAvlFlg2 0 "FALSE" 1 "TRUE" ;
VAL_ 1240 DrvrAlrtTypCstAvlFlg1 0 "FALSE" 1 "TRUE" ;
VAL_ 1240 CrgBedVwAutoLgtCstSetAval 0 "FALSE" 1 "TRUE" ;
VAL_ 1240 RrClsrAjrStat 0 "FALSE" 1 "TRUE" ;
VAL_ 1240 RrClsrAjrStat_Inv 0 "FALSE" 1 "TRUE" ;
VAL_ 1240 RRDrAjrStat 0 "FALSE" 1 "TRUE" ;
VAL_ 1240 RRDrAjrStat_Inv 0 "FALSE" 1 "TRUE" ;
VAL_ 1240 EsyExtCstStAvl 0 "FALSE" 1 "TRUE" ;
VAL_ 1240 DsplyTrgVdOn 0 "FALSE" 1 "TRUE" ;
VAL_ 1240 DspFrnt360CmrON 0 "FALSE" 1 "TRUE" ;
VAL_ 1240 DrvrAlrtTypCstStAvl 0 "FALSE" 1 "TRUE" ;
VAL_ 1240 DrvrAlrtTypCstAvlFlg7 0 "FALSE" 1 "TRUE" ;
VAL_ 1240 DrvrAlrtTypCstAvlFlg6 0 "FALSE" 1 "TRUE" ;
VAL_ 1240 DrvrAlrtTypCstAvlFlg5 0 "FALSE" 1 "TRUE" ;
VAL_ 1240 DrvrAlrtTypCstAvlFlg4 0 "FALSE" 1 "TRUE" ;
VAL_ 1240 LnChgAlrtLmtdTrlrIndOn 0 "FALSE" 1 "TRUE" ;
VAL_ 1240 LnChgAlrtCstStAvl 0 "FALSE" 1 "TRUE" ;
VAL_ 1240 JckKnfDtnCstSetAval 0 "FALSE" 1 "TRUE" ;
VAL_ 1240 HptcStFldIndOn 0 "FALSE" 1 "TRUE" ;
VAL_ 1240 GoNotfrCstStAvl 0 "FALSE" 1 "TRUE" ;
VAL_ 1240 GlrFrHgBmRspTypCstStAvl 0 "FALSE" 1 "TRUE" ;
VAL_ 1240 FrwdImpMtgnOpSlctCstStAvl 0 "FALSE" 1 "TRUE" ;
VAL_ 1240 FrntPCMRspTypCstStAvl 0 "FALSE" 1 "TRUE" ;
VAL_ 1240 RnngBrdManDplyCstSetSelbl 0 "FALSE" 1 "TRUE" ;
VAL_ 1240 RnngBrdManDplyCstSetAval 0 "FALSE" 1 "TRUE" ;
VAL_ 1240 RnngBrdAutoDplyCstSetAval 0 "FALSE" 1 "TRUE" ;
VAL_ 1240 PrkAsstTrHtchPsntCstStAvl 0 "FALSE" 1 "TRUE" ;
VAL_ 1240 PrkAsstONOFFCstStAvl 0 "FALSE" 1 "TRUE" ;
VAL_ 1240 LtRtHnTrCstStAvl 0 "FALSE" 1 "TRUE" ;
VAL_ 1240 LnChgAlrtSysOffIndOn 0 "FALSE" 1 "TRUE" ;
VAL_ 1240 SBZAlrtCstAvlFlg6 0 "FALSE" 1 "TRUE" ;
VAL_ 1240 SBZAlrtCstAvlFlg5 0 "FALSE" 1 "TRUE" ;
VAL_ 1240 SBZAlrtCstAvlFlg4 0 "FALSE" 1 "TRUE" ;
VAL_ 1240 SBZAlrtCstAvlFlg3 0 "FALSE" 1 "TRUE" ;
VAL_ 1240 SBZAlrtCstAvlFlg2 0 "FALSE" 1 "TRUE" ;
VAL_ 1240 SBZAlrtCstAvlFlg1 0 "FALSE" 1 "TRUE" ;
VAL_ 1240 RrVwPrkAstSymCsStAvl 0 "FALSE" 1 "TRUE" ;
VAL_ 1240 RrCrsTrfcAlrtCstStAvl 0 "FALSE" 1 "TRUE" ;
VAL_ 1240 TargaTopAjrStat 0 "FALSE" 1 "TRUE" ;
VAL_ 1240 StBltTghtngCstStAv 0 "FALSE" 1 "TRUE" ;
VAL_ 1240 SrrndVwLghtCsStAvl 0 "FALSE" 1 "TRUE" ;
VAL_ 1240 ServSdDtcSysIndOn 0 "FALSE" 1 "TRUE" ;
VAL_ 1240 SdDtcTempUnvIndOn 0 "FALSE" 1 "TRUE" ;
VAL_ 1240 SBZAlrtOffIndOn 0 "FALSE" 1 "TRUE" ;
VAL_ 1240 SBZAlrtCstStAvl 0 "FALSE" 1 "TRUE" ;
VAL_ 1240 SBZAlrtCstAvlFlg7 0 "FALSE" 1 "TRUE" ;
VAL_ 1240 TrnSigSwRtActv 0 "FALSE" 1 "TRUE" ;
VAL_ 1240 TrnSigSwLtActv 0 "FALSE" 1 "TRUE" ;
VAL_ 1240 TrlrMirVidGdlnsCstSetAval 0 "FALSE" 1 "TRUE" ;
VAL_ 1240 TrlrMirVidEnblCstSetAval 0 "FALSE" 1 "TRUE" ;
VAL_ 1240 TrlrConnStat 0 "Not Connected" 1 "Connected" ;
VAL_ 1240 TrffcLgtAsstCstSetAval 0 "FALSE" 1 "TRUE" ;
VAL_ 1240 PwrRrClsrCstCurrSetVal 0 "Setting_Unknown" 1 "Off" 2 "On" 3 "On_Custom_Height" 4 "RESERVED_4" 5 "RESERVED_5" 6 "RESERVED_6" 7 "RESERVED_7" ;
VAL_ 1241 GlrFrHgBmRspTypCstCurSetVal 0 "SETTING_UNKNOWN" 1 "AUTOMATIC_HIGH_BEAM" 2 "GLARE_FREE_HIGH_BEAM" 3 "RESERVED_3" 4 "\?? RESERVED_4" 5 "RESERVED_5" 6 "RESERVED_6" 7 "RESERVED_7" ;
VAL_ 1241 FrwdImpMtgnOpSlctCstCrStVal 0 "SETTING_UNKNOWN" 1 "OFF" 2 "ALERT" 3 "ALERT_BRAKE" 4 "ALERT_BRAKE_STEER" 5 "RESERVED_5" 6 "RESERVED_6" 7 "RESERVED_7" ;
VAL_ 1241 FrntPCMRspTypCstCrStVal 0 "SETTING_UNKNOWN" 1 "OFF" 2 "ALERT" 3 "ALERT_AND_BRAKE" 4 "ALERT_AND_BRAKE_AND_STEER" 5 "RESERVED_5" 6 "RESERVED_6" 7 "RESERVED_7" ;
VAL_ 1241 LnChgAlrtCstCrStVal 0 "SETTING_UNKNOWN" 1 "OFF" 2 "ON" 3 "RESERVED_3" 4 "RESERVED_4" 5 "RESERVED_5" 6 "RESERVED_6" 7 "RESERVED_7" ;
VAL_ 1241 JckKnfDtnCstCurrSetVal 0 "Setting_Unknown" 1 "Off" 2 "On" 3 "Reserved_3" 4 "Reserved_4" 5 "Reserved_5" 6 "Reserved_6" 7 "Reserved_7" ;
VAL_ 1241 GoNotfrCstCrStVal 0 "SETTING_UNKNOWN" 1 "OFF" 2 "ON" 3 "RESERVED_3" 4 "RESERVED_4" 5 "RESERVED_5" 6 "RESERVED_6" 7 "RESERVED_7" ;
VAL_ 1241 PrkAsstONOFFCstCrStVal 0 "SETTING_UNKNOWN" 1 "OFF" 2 "ALERT" 3 "ALERT_BRAKE" 4 "RESERVED_4" 5 "RESERVED_5" 6 "RESERVED_6" 7 "RESERVED_7" ;
VAL_ 1241 LtRtHnTrCstCurSetVal 0 "SETTING_UNKNOWN" 1 "LEFT_HAND_DRIVE" 2 "RIGHT_HAND_DRIVE" 3 "AUTOMATIC_WITH_GPS" 4 "RESERVED_4" 5 "RESERVED_5" 6 "RESERVED_6" 7 "RESERVED_7" ;
VAL_ 1241 RnngBrdAutoDplyCstCurrSetVal 0 "Setting_Unknown" 1 "Off" 2 "Door" 3 "Door_Park" 4 "Reserved_5" 5 "Reserved_6" 6 "Reserved_7" ;
VAL_ 1241 PFASndSeltnCstCurrSetVal 0 "Setting_Unknown" 1 "Pedestrian Alert Sound 1" 2 "Pedestrian Alert Sound 2" 3 "Pedestrian Alert Sound 3" 4 "RESERVED_4" 5 "RESERVED_5" 6 "RESERVED_6" 7 "RESERVED_7" ;
VAL_ 1241 PrkAsstTrHtchPsntCstCrStVal 0 "SETTING_UNKNOWN" 1 "OFF_NOT_ATTACHED" 2 "ON_ATTACHED" 3 "RESERVED_3" 4 "RESERVED_4" 5 "RESERVED_5" 6 "RESERVED_6" 7 "RESERVED_7" ;
VAL_ 1241 RrVwPrkAstSymCsCrStVal 0 "SETTING_UNKNOWN" 1 "OFF" 2 "ON" 3 "RESERVED_3" 4 "RESERVED_4" 5 "RESERVED_5" 6 "RESERVED_6" 7 "RESERVED_7" ;
VAL_ 1241 RrCrsTrfcAlrtCstCrStVal 0 "SETTING_UNKNOWN" 1 "OFF" 2 "ALERT" 3 "ALERT and BRAKE" 4 "RESERVED_4" 5 "RESERVED_5" 6 "RESERVED_6" 7 "RESERVED_7" ;
VAL_ 1241 RnngBrdManDplyCstCurrSetVal 0 "Setting_Unknown" 1 "Off" 2 "Extend to Door" 3 "Extend to Bed" 4 "Reserved_4" 5 "Reserved_5" 6 "Reserved_6" 7 "Reserved_7" ;
VAL_ 1241 SrrndVwLghtCsCrStVal 0 "SETTING_UNKNOWN" 1 "OFF" 2 "ON" 3 "RESERVED_3" 4 "RESERVED_4" 5 "RESERVED_5" 6 "RESERVED_6" 7 "RESERVED_7" ;
VAL_ 1241 SBZAlrtCstCrStVal 0 "SETTING_UNKNOWN" 1 "OFF" 2 "ON" 3 "RESERVED_3" 4 "RESERVED_4" 5 "RESERVED_5" 6 "RESERVED_6" 7 "RESERVED_7" ;
VAL_ 1241 TrlrMirVidGdlnsCstCurrSetVal 0 "Setting_Unknown" 1 "Off" 2 "On" 3 "Reserved_3" 4 "Reserved_4" 5 "Reserved_5" 6 "Reserved_6" 7 "Reserved_7" ;
VAL_ 1241 TrffcLgtAsstCstCurrSetVal 0 "SETTING_UNKNOWN" 1 "OFF" 2 "ALERT" 3 "RESERVED_3" 4 "RESERVED_4" 5 "RESERVED_5" 6 "RESERVED_6" 7 "RESERVED_7" ;
VAL_ 1241 StBltTghtngCstCrStVal 0 "SETTING_UNKNOWN" 1 "OFF" 2 "ON" 3 "RESERVED_3" 4 "RESERVED_4" 5 "RESERVED_5" 6 "RESERVED_6" 7 "RESERVED_7" ;
VAL_ 1241 CnvtblTopTneuAjrStat 0 "FALSE" 1 "TRUE" ;
VAL_ 1241 LftglsAjrStat 0 "FALSE" 1 "TRUE" ;
VAL_ 1241 LftglsAjrStat_Inv 0 "FALSE" 1 "TRUE" ;
VAL_ 1241 LRDrAjrStat 0 "FALSE" 1 "TRUE" ;
VAL_ 1241 LRDrAjrStat_Inv 0 "FALSE" 1 "TRUE" ;
VAL_ 1241 ElvtdIdlCstCrStVal 0 "No Action" 1 "Off" 2 "On" ;
